VERSION ""

NS_ :

BS_:

BU_: ECU BMU SHDN CHRG TOOL LOGGER C125 DTI_L DTI_R SEVCON_L SEVCON_R SBG

BO_ 2284095744 BMU_TransmitBalancing_N_16: 8 BMU
 SG_ BMU_M16_Balance : 0|16@1+ (1,0) [0|65535] "" LOGGER
 SG_ BMU_M16_DieTemp : 16|8@1+ (1,0) [0|255] "degC" LOGGER

BO_ 2284095760 BMU_TransmitBalancing_N_17: 8 BMU
 SG_ BMU_M17_Balance : 0|16@1+ (1,0) [0|65535] "" LOGGER
 SG_ BMU_M17_DieTemp : 16|8@1+ (1,0) [0|255] "degC" LOGGER

BO_ 2284095776 BMU_TransmitBalancing_N_18: 8 BMU
 SG_ BMU_M18_Balance : 0|16@1+ (1,0) [0|65535] "" LOGGER
 SG_ BMU_M18_DieTemp : 16|8@1+ (1,0) [0|255] "degC" LOGGER

BO_ 2284095792 BMU_TransmitBalancing_N_19: 8 BMU
 SG_ BMU_M19_Balance : 0|16@1+ (1,0) [0|65535] "" LOGGER
 SG_ BMU_M19_DieTemp : 16|8@1+ (1,0) [0|255] "degC" LOGGER

BO_ 2284095808 BMU_TransmitBalancing_N_20: 8 BMU
 SG_ BMU_M20_Balance : 0|16@1+ (1,0) [0|65535] "" LOGGER
 SG_ BMU_M20_DieTemp : 16|8@1+ (1,0) [0|255] "degC" LOGGER

BO_ 2284095824 BMU_TransmitBalancing_N_21: 8 BMU
 SG_ BMU_M21_Balance : 0|16@1+ (1,0) [0|65535] "" LOGGER
 SG_ BMU_M21_DieTemp : 16|8@1+ (1,0) [0|255] "degC" LOGGER

BO_ 2284095840 BMU_TransmitBalancing_N_22: 8 BMU
 SG_ BMU_M22_Balance : 0|16@1+ (1,0) [0|65535] "" LOGGER
 SG_ BMU_M22_DieTemp : 16|8@1+ (1,0) [0|255] "degC" LOGGER

BO_ 2284095856 BMU_TransmitBalancing_N_23: 8 BMU
 SG_ BMU_M23_Balance : 0|16@1+ (1,0) [0|65535] "" LOGGER
 SG_ BMU_M23_DieTemp : 16|8@1+ (1,0) [0|255] "degC" LOGGER

BO_ 2284096768 BMU25_TransmitPackInfo: 8 BMU
 SG_ BMU_PackCurrent : 0|32@1- (0.000001,0) [-2147.483648|2147.483647] "A" ECU,C125
 SG_ BMU_PackVoltage : 32|32@1- (0.000001,0) [-2147.483648|2147.483647] "V" ECU,C125

BO_ 2284096784 BMU25_TransmitPackSummary: 8 BMU
 SG_ BMU_MinCell : 0|16@1+ (1,0) [0|65535] "mV" C125
 SG_ BMU_ValidCells : 16|16@1+ (1,0) [0|65535] "" C125
 SG_ BMU_MaxCellTemp : 32|8@1+ (1,0) [0|255] "degC" C125

BO_ 2284096800 BMU25_TransmitSOC: 8 BMU
 SG_ BMU_SocPct : 0|8@1+ (1,0) [0|255] "%" C125
 SG_ BMU_SocValid : 8|1@1+ (1,0) [0|1] "" C125
 SG_ BMU_SocCalibrated : 9|1@1+ (1,0) [0|1] "" C125
 SG_ BMU_Charge : 16|32@1- (0.000001,0) [-2147.483648|2147.483647] "Ah" C125

BO_ 2284097024 BMU25_TransmitPower: 8 BMU
 SG_ BMU_PackPower : 0|32@1- (1,0) [-2147483648|2147483647] "W" Vector__XXX

BO_ 2286157824 ECU_HEARTBEAT: 8 ECU
 SG_ ECU_State : 0|8@1+ (1,0) [0|255] "" BMU,SHDN,C125
 SG_ ECU_F_PedalPolarity : 8|1@1+ (1,0) [0|1] "" BMU,SHDN,C125
 SG_ ECU_F_BmuAlive : 9|1@1+ (1,0) [0|1] "" BMU,SHDN,C125
 SG_ ECU_F_InvAlive : 10|1@1+ (1,0) [0|1] "" BMU,SHDN,C125
 SG_ ECU_F_ShdnClosed : 11|1@1+ (1,0) [0|1] "" BMU,SHDN,C125
 SG_ ECU_F_PedalOk : 12|1@1+ (1,0) [0|1] "" BMU,SHDN,C125
 SG_ ECU_F_BrakePressed : 13|1@1+ (1,0) [0|1] "" BMU,SHDN,C125
 SG_ ECU_F_PrechargeReq : 14|1@1+ (1,0) [0|1] "" BMU,SHDN,C125
 SG_ ECU_F_TorqueAllowed : 15|1@1+ (1,0) [0|1] "" BMU,SHDN,C125
 SG_ ECU_F_OutputFault : 16|1@1+ (1,0) [0|1] "" BMU,SHDN,C125
 SG_ ECU_F_CanAOk : 17|1@1+ (1,0) [0|1] "" BMU,SHDN,C125
 SG_ ECU_F_CanBOk : 18|1@1+ (1,0) [0|1] "" BMU,SHDN,C125
 SG_ ECU_F_Warning : 19|1@1+ (1,0) [0|1] "" BMU,SHDN,C125
 SG_ ECU_F_EepromOk : 20|1@1+ (1,0) [0|1] "" BMU,SHDN,C125
 SG_ ECU_F_Calibrated : 21|1@1+ (1,0) [0|1] "" BMU,SHDN,C125
 SG_ ECU_F_HvOffReq : 22|1@1+ (1,0) [0|1] "" BMU,SHDN,C125
 SG_ ECU_FaultCode : 24|16@1+ (1,0) [0|65535] "" BMU,SHDN,C125
 SG_ ECU_FaultSeverity : 40|8@1+ (1,0) [0|255] "" BMU,SHDN,C125
 SG_ ECU_Uptime : 48|16@1+ (1,0) [0|65535] "s" BMU,SHDN,C125

BO_ 2290122752 VCU_ShutdownStatus: 8 SHDN
 SG_ SHDN_OldLines : 0|16@1+ (1,0) [0|65535] "" ECU,BMU
 SG_ SHDN_OldFirstFault : 16|8@1+ (1,0) [0|255] "" ECU,BMU

BO_ 2290122784 VCU_Pedal_Accel: 8 ECU
 SG_ VCU_Pedal_Accel_0 : 7|16@0+ (0.1,0) [0|6553.5] "%" Vector__XXX
 SG_ VCU_Pedal_Accel_1 : 23|16@0+ (0.1,0) [0|6553.5] "%" Vector__XXX
 SG_ VCU_Pedal_Accel_ADC_0 : 39|16@0+ (1,0) [0|65535] "mV" Vector__XXX
 SG_ VCU_Pedal_Accel_ADC_1 : 55|16@0+ (1,0) [0|65535] "mV" Vector__XXX

BO_ 2290122800 VCU_Pedal_Brake: 8 ECU
 SG_ VCU_Pedal_Brake_ADC_0 : 7|16@0+ (1,0) [0|65535] "mV" Vector__XXX
 SG_ VCU_Pedal_Brake_ADC_1 : 23|16@0+ (1,0) [0|65535] "mV" Vector__XXX
 SG_ VCU_Pedal_Brake_PSI_0 : 39|16@0- (0.0625,0) [-2048|2047.9375] "psi" Vector__XXX
 SG_ VCU_Pedal_Brake_PSI_1 : 55|16@0- (0.0625,0) [-2048|2047.9375] "psi" Vector__XXX

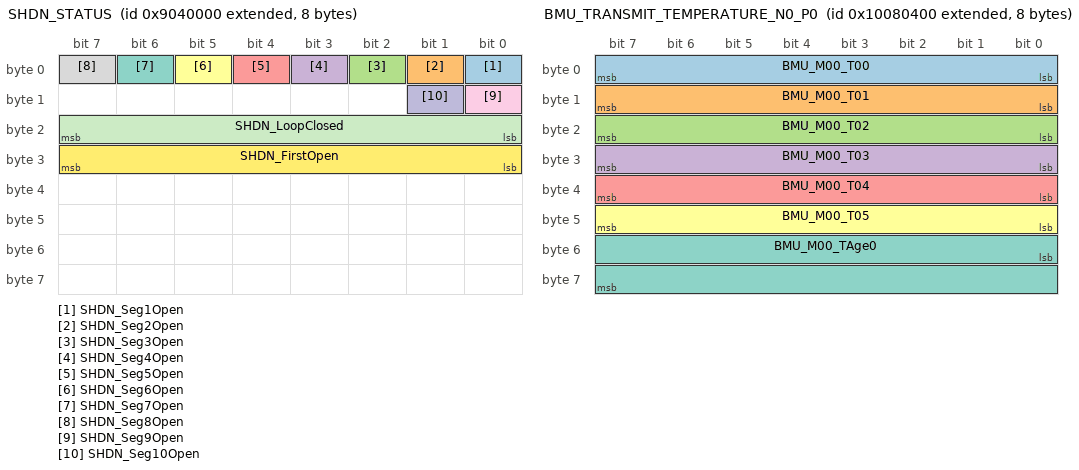
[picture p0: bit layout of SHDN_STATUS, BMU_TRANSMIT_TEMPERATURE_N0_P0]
BO_ 2298740736 SHDN_STATUS: 8 SHDN
 SG_ SHDN_Seg1Open : 0|1@1+ (1,0) [0|1] "" ECU,BMU,C125
 SG_ SHDN_Seg2Open : 1|1@1+ (1,0) [0|1] "" ECU,BMU,C125
 SG_ SHDN_Seg3Open : 2|1@1+ (1,0) [0|1] "" ECU,BMU,C125
 SG_ SHDN_Seg4Open : 3|1@1+ (1,0) [0|1] "" ECU,BMU,C125
 SG_ SHDN_Seg5Open : 4|1@1+ (1,0) [0|1] "" ECU,BMU,C125
 SG_ SHDN_Seg6Open : 5|1@1+ (1,0) [0|1] "" ECU,BMU,C125
 SG_ SHDN_Seg7Open : 6|1@1+ (1,0) [0|1] "" ECU,BMU,C125
 SG_ SHDN_Seg8Open : 7|1@1+ (1,0) [0|1] "" ECU,BMU,C125
 SG_ SHDN_Seg9Open : 8|1@1+ (1,0) [0|1] "" ECU,BMU,C125
 SG_ SHDN_Seg10Open : 9|1@1+ (1,0) [0|1] "" ECU,BMU,C125
 SG_ SHDN_LoopClosed : 16|8@1+ (1,0) [0|255] "" ECU,BMU,C125
 SG_ SHDN_FirstOpen : 24|8@1+ (1,0) [0|255] "" ECU,BMU,C125

BO_ 2307129344 CHARGE_CONTROL_HEARTBEAT: 8 CHRG
 SG_ CHRG_State : 0|8@1+ (1,0) [0|255] "" BMU
 SG_ CHRG_F_HbAms : 8|1@1+ (1,0) [0|1] "" BMU

BO_ 2316304896 BMU25_SendyneForward: 8 BMU

BO_ 2416443392 BMU_TRANSMIT_VOLTAGE_N0_P0: 8 BMU
 SG_ BMU_M00_V00 : 0|16@1+ (1,0) [0|65535] "mV" LOGGER
 SG_ BMU_M00_V01 : 16|16@1+ (1,0) [0|65535] "mV" LOGGER
 SG_ BMU_M00_V02 : 32|16@1+ (1,0) [0|65535] "mV" LOGGER
 SG_ BMU_M00_VAge0 : 48|16@1+ (1,0) [0|65535] "ms" LOGGER

BO_ 2416443393 BMU_TRANSMIT_VOLTAGE_N0_P1: 8 BMU
 SG_ BMU_M00_V03 : 0|16@1+ (1,0) [0|65535] "mV" LOGGER
 SG_ BMU_M00_V04 : 16|16@1+ (1,0) [0|65535] "mV" LOGGER
 SG_ BMU_M00_V05 : 32|16@1+ (1,0) [0|65535] "mV" LOGGER
 SG_ BMU_M00_VAge1 : 48|16@1+ (1,0) [0|65535] "ms" LOGGER

BO_ 2416443394 BMU_TRANSMIT_VOLTAGE_N0_P2: 8 BMU
 SG_ BMU_M00_V06 : 0|16@1+ (1,0) [0|65535] "mV" LOGGER
 SG_ BMU_M00_V07 : 16|16@1+ (1,0) [0|65535] "mV" LOGGER
 SG_ BMU_M00_V08 : 32|16@1+ (1,0) [0|65535] "mV" LOGGER
 SG_ BMU_M00_VAge2 : 48|16@1+ (1,0) [0|65535] "ms" LOGGER

BO_ 2416443395 BMU_TRANSMIT_VOLTAGE_N0_P3: 8 BMU
 SG_ BMU_M00_V09 : 0|16@1+ (1,0) [0|65535] "mV" LOGGER
 SG_ BMU_M00_V10 : 16|16@1+ (1,0) [0|65535] "mV" LOGGER
 SG_ BMU_M00_V11 : 32|16@1+ (1,0) [0|65535] "mV" LOGGER
 SG_ BMU_M00_VAge3 : 48|16@1+ (1,0) [0|65535] "ms" LOGGER

BO_ 2416443408 BMU_TRANSMIT_VOLTAGE_N1_P0: 8 BMU
 SG_ BMU_M01_V00 : 0|16@1+ (1,0) [0|65535] "mV" LOGGER
 SG_ BMU_M01_V01 : 16|16@1+ (1,0) [0|65535] "mV" LOGGER
 SG_ BMU_M01_V02 : 32|16@1+ (1,0) [0|65535] "mV" LOGGER
 SG_ BMU_M01_VAge0 : 48|16@1+ (1,0) [0|65535] "ms" LOGGER

BO_ 2416443409 BMU_TRANSMIT_VOLTAGE_N1_P1: 8 BMU
 SG_ BMU_M01_V03 : 0|16@1+ (1,0) [0|65535] "mV" LOGGER
 SG_ BMU_M01_V04 : 16|16@1+ (1,0) [0|65535] "mV" LOGGER
 SG_ BMU_M01_V05 : 32|16@1+ (1,0) [0|65535] "mV" LOGGER
 SG_ BMU_M01_VAge1 : 48|16@1+ (1,0) [0|65535] "ms" LOGGER

BO_ 2416443410 BMU_TRANSMIT_VOLTAGE_N1_P2: 8 BMU
 SG_ BMU_M01_V06 : 0|16@1+ (1,0) [0|65535] "mV" LOGGER
 SG_ BMU_M01_V07 : 16|16@1+ (1,0) [0|65535] "mV" LOGGER
 SG_ BMU_M01_V08 : 32|16@1+ (1,0) [0|65535] "mV" LOGGER
 SG_ BMU_M01_VAge2 : 48|16@1+ (1,0) [0|65535] "ms" LOGGER

BO_ 2416443411 BMU_TRANSMIT_VOLTAGE_N1_P3: 8 BMU
 SG_ BMU_M01_V09 : 0|16@1+ (1,0) [0|65535] "mV" LOGGER
 SG_ BMU_M01_V10 : 16|16@1+ (1,0) [0|65535] "mV" LOGGER
 SG_ BMU_M01_V11 : 32|16@1+ (1,0) [0|65535] "mV" LOGGER
 SG_ BMU_M01_VAge3 : 48|16@1+ (1,0) [0|65535] "ms" LOGGER

BO_ 2416443424 BMU_TRANSMIT_VOLTAGE_N2_P0: 8 BMU
 SG_ BMU_M02_V00 : 0|16@1+ (1,0) [0|65535] "mV" LOGGER
 SG_ BMU_M02_V01 : 16|16@1+ (1,0) [0|65535] "mV" LOGGER
 SG_ BMU_M02_V02 : 32|16@1+ (1,0) [0|65535] "mV" LOGGER
 SG_ BMU_M02_VAge0 : 48|16@1+ (1,0) [0|65535] "ms" LOGGER

BO_ 2416443425 BMU_TRANSMIT_VOLTAGE_N2_P1: 8 BMU
 SG_ BMU_M02_V03 : 0|16@1+ (1,0) [0|65535] "mV" LOGGER
 SG_ BMU_M02_V04 : 16|16@1+ (1,0) [0|65535] "mV" LOGGER
 SG_ BMU_M02_V05 : 32|16@1+ (1,0) [0|65535] "mV" LOGGER
 SG_ BMU_M02_VAge1 : 48|16@1+ (1,0) [0|65535] "ms" LOGGER

BO_ 2416443426 BMU_TRANSMIT_VOLTAGE_N2_P2: 8 BMU
 SG_ BMU_M02_V06 : 0|16@1+ (1,0) [0|65535] "mV" LOGGER
 SG_ BMU_M02_V07 : 16|16@1+ (1,0) [0|65535] "mV" LOGGER
 SG_ BMU_M02_V08 : 32|16@1+ (1,0) [0|65535] "mV" LOGGER
 SG_ BMU_M02_VAge2 : 48|16@1+ (1,0) [0|65535] "ms" LOGGER

BO_ 2416443427 BMU_TRANSMIT_VOLTAGE_N2_P3: 8 BMU
 SG_ BMU_M02_V09 : 0|16@1+ (1,0) [0|65535] "mV" LOGGER
 SG_ BMU_M02_V10 : 16|16@1+ (1,0) [0|65535] "mV" LOGGER
 SG_ BMU_M02_V11 : 32|16@1+ (1,0) [0|65535] "mV" LOGGER
 SG_ BMU_M02_VAge3 : 48|16@1+ (1,0) [0|65535] "ms" LOGGER

BO_ 2416443440 BMU_TRANSMIT_VOLTAGE_N3_P0: 8 BMU
 SG_ BMU_M03_V00 : 0|16@1+ (1,0) [0|65535] "mV" LOGGER
 SG_ BMU_M03_V01 : 16|16@1+ (1,0) [0|65535] "mV" LOGGER
 SG_ BMU_M03_V02 : 32|16@1+ (1,0) [0|65535] "mV" LOGGER
 SG_ BMU_M03_VAge0 : 48|16@1+ (1,0) [0|65535] "ms" LOGGER

BO_ 2416443441 BMU_TRANSMIT_VOLTAGE_N3_P1: 8 BMU
 SG_ BMU_M03_V03 : 0|16@1+ (1,0) [0|65535] "mV" LOGGER
 SG_ BMU_M03_V04 : 16|16@1+ (1,0) [0|65535] "mV" LOGGER
 SG_ BMU_M03_V05 : 32|16@1+ (1,0) [0|65535] "mV" LOGGER
 SG_ BMU_M03_VAge1 : 48|16@1+ (1,0) [0|65535] "ms" LOGGER

BO_ 2416443442 BMU_TRANSMIT_VOLTAGE_N3_P2: 8 BMU
 SG_ BMU_M03_V06 : 0|16@1+ (1,0) [0|65535] "mV" LOGGER
 SG_ BMU_M03_V07 : 16|16@1+ (1,0) [0|65535] "mV" LOGGER
 SG_ BMU_M03_V08 : 32|16@1+ (1,0) [0|65535] "mV" LOGGER
 SG_ BMU_M03_VAge2 : 48|16@1+ (1,0) [0|65535] "ms" LOGGER

BO_ 2416443443 BMU_TRANSMIT_VOLTAGE_N3_P3: 8 BMU
 SG_ BMU_M03_V09 : 0|16@1+ (1,0) [0|65535] "mV" LOGGER
 SG_ BMU_M03_V10 : 16|16@1+ (1,0) [0|65535] "mV" LOGGER
 SG_ BMU_M03_V11 : 32|16@1+ (1,0) [0|65535] "mV" LOGGER
 SG_ BMU_M03_VAge3 : 48|16@1+ (1,0) [0|65535] "ms" LOGGER

BO_ 2416443456 BMU_TRANSMIT_VOLTAGE_N4_P0: 8 BMU
 SG_ BMU_M04_V00 : 0|16@1+ (1,0) [0|65535] "mV" LOGGER
 SG_ BMU_M04_V01 : 16|16@1+ (1,0) [0|65535] "mV" LOGGER
 SG_ BMU_M04_V02 : 32|16@1+ (1,0) [0|65535] "mV" LOGGER
 SG_ BMU_M04_VAge0 : 48|16@1+ (1,0) [0|65535] "ms" LOGGER

BO_ 2416443457 BMU_TRANSMIT_VOLTAGE_N4_P1: 8 BMU
 SG_ BMU_M04_V03 : 0|16@1+ (1,0) [0|65535] "mV" LOGGER
 SG_ BMU_M04_V04 : 16|16@1+ (1,0) [0|65535] "mV" LOGGER
 SG_ BMU_M04_V05 : 32|16@1+ (1,0) [0|65535] "mV" LOGGER
 SG_ BMU_M04_VAge1 : 48|16@1+ (1,0) [0|65535] "ms" LOGGER

BO_ 2416443458 BMU_TRANSMIT_VOLTAGE_N4_P2: 8 BMU
 SG_ BMU_M04_V06 : 0|16@1+ (1,0) [0|65535] "mV" LOGGER
 SG_ BMU_M04_V07 : 16|16@1+ (1,0) [0|65535] "mV" LOGGER
 SG_ BMU_M04_V08 : 32|16@1+ (1,0) [0|65535] "mV" LOGGER
 SG_ BMU_M04_VAge2 : 48|16@1+ (1,0) [0|65535] "ms" LOGGER

BO_ 2416443459 BMU_TRANSMIT_VOLTAGE_N4_P3: 8 BMU
 SG_ BMU_M04_V09 : 0|16@1+ (1,0) [0|65535] "mV" LOGGER
 SG_ BMU_M04_V10 : 16|16@1+ (1,0) [0|65535] "mV" LOGGER
 SG_ BMU_M04_V11 : 32|16@1+ (1,0) [0|65535] "mV" LOGGER
 SG_ BMU_M04_VAge3 : 48|16@1+ (1,0) [0|65535] "ms" LOGGER

BO_ 2416443472 BMU_TRANSMIT_VOLTAGE_N5_P0: 8 BMU
 SG_ BMU_M05_V00 : 0|16@1+ (1,0) [0|65535] "mV" LOGGER
 SG_ BMU_M05_V01 : 16|16@1+ (1,0) [0|65535] "mV" LOGGER
 SG_ BMU_M05_V02 : 32|16@1+ (1,0) [0|65535] "mV" LOGGER
 SG_ BMU_M05_VAge0 : 48|16@1+ (1,0) [0|65535] "ms" LOGGER

BO_ 2416443473 BMU_TRANSMIT_VOLTAGE_N5_P1: 8 BMU
 SG_ BMU_M05_V03 : 0|16@1+ (1,0) [0|65535] "mV" LOGGER
 SG_ BMU_M05_V04 : 16|16@1+ (1,0) [0|65535] "mV" LOGGER
 SG_ BMU_M05_V05 : 32|16@1+ (1,0) [0|65535] "mV" LOGGER
 SG_ BMU_M05_VAge1 : 48|16@1+ (1,0) [0|65535] "ms" LOGGER

BO_ 2416443474 BMU_TRANSMIT_VOLTAGE_N5_P2: 8 BMU
 SG_ BMU_M05_V06 : 0|16@1+ (1,0) [0|65535] "mV" LOGGER
 SG_ BMU_M05_V07 : 16|16@1+ (1,0) [0|65535] "mV" LOGGER
 SG_ BMU_M05_V08 : 32|16@1+ (1,0) [0|65535] "mV" LOGGER
 SG_ BMU_M05_VAge2 : 48|16@1+ (1,0) [0|65535] "ms" LOGGER

BO_ 2416443475 BMU_TRANSMIT_VOLTAGE_N5_P3: 8 BMU
 SG_ BMU_M05_V09 : 0|16@1+ (1,0) [0|65535] "mV" LOGGER
 SG_ BMU_M05_V10 : 16|16@1+ (1,0) [0|65535] "mV" LOGGER
 SG_ BMU_M05_V11 : 32|16@1+ (1,0) [0|65535] "mV" LOGGER
 SG_ BMU_M05_VAge3 : 48|16@1+ (1,0) [0|65535] "ms" LOGGER

BO_ 2416443488 BMU_TRANSMIT_VOLTAGE_N6_P0: 8 BMU
 SG_ BMU_M06_V00 : 0|16@1+ (1,0) [0|65535] "mV" LOGGER
 SG_ BMU_M06_V01 : 16|16@1+ (1,0) [0|65535] "mV" LOGGER
 SG_ BMU_M06_V02 : 32|16@1+ (1,0) [0|65535] "mV" LOGGER
 SG_ BMU_M06_VAge0 : 48|16@1+ (1,0) [0|65535] "ms" LOGGER

BO_ 2416443489 BMU_TRANSMIT_VOLTAGE_N6_P1: 8 BMU
 SG_ BMU_M06_V03 : 0|16@1+ (1,0) [0|65535] "mV" LOGGER
 SG_ BMU_M06_V04 : 16|16@1+ (1,0) [0|65535] "mV" LOGGER
 SG_ BMU_M06_V05 : 32|16@1+ (1,0) [0|65535] "mV" LOGGER
 SG_ BMU_M06_VAge1 : 48|16@1+ (1,0) [0|65535] "ms" LOGGER

BO_ 2416443490 BMU_TRANSMIT_VOLTAGE_N6_P2: 8 BMU
 SG_ BMU_M06_V06 : 0|16@1+ (1,0) [0|65535] "mV" LOGGER
 SG_ BMU_M06_V07 : 16|16@1+ (1,0) [0|65535] "mV" LOGGER
 SG_ BMU_M06_V08 : 32|16@1+ (1,0) [0|65535] "mV" LOGGER
 SG_ BMU_M06_VAge2 : 48|16@1+ (1,0) [0|65535] "ms" LOGGER

BO_ 2416443491 BMU_TRANSMIT_VOLTAGE_N6_P3: 8 BMU
 SG_ BMU_M06_V09 : 0|16@1+ (1,0) [0|65535] "mV" LOGGER
 SG_ BMU_M06_V10 : 16|16@1+ (1,0) [0|65535] "mV" LOGGER
 SG_ BMU_M06_V11 : 32|16@1+ (1,0) [0|65535] "mV" LOGGER
 SG_ BMU_M06_VAge3 : 48|16@1+ (1,0) [0|65535] "ms" LOGGER

BO_ 2416443504 BMU_TRANSMIT_VOLTAGE_N7_P0: 8 BMU
 SG_ BMU_M07_V00 : 0|16@1+ (1,0) [0|65535] "mV" LOGGER
 SG_ BMU_M07_V01 : 16|16@1+ (1,0) [0|65535] "mV" LOGGER
 SG_ BMU_M07_V02 : 32|16@1+ (1,0) [0|65535] "mV" LOGGER
 SG_ BMU_M07_VAge0 : 48|16@1+ (1,0) [0|65535] "ms" LOGGER

BO_ 2416443505 BMU_TRANSMIT_VOLTAGE_N7_P1: 8 BMU
 SG_ BMU_M07_V03 : 0|16@1+ (1,0) [0|65535] "mV" LOGGER
 SG_ BMU_M07_V04 : 16|16@1+ (1,0) [0|65535] "mV" LOGGER
 SG_ BMU_M07_V05 : 32|16@1+ (1,0) [0|65535] "mV" LOGGER
 SG_ BMU_M07_VAge1 : 48|16@1+ (1,0) [0|65535] "ms" LOGGER

BO_ 2416443506 BMU_TRANSMIT_VOLTAGE_N7_P2: 8 BMU
 SG_ BMU_M07_V06 : 0|16@1+ (1,0) [0|65535] "mV" LOGGER
 SG_ BMU_M07_V07 : 16|16@1+ (1,0) [0|65535] "mV" LOGGER
 SG_ BMU_M07_V08 : 32|16@1+ (1,0) [0|65535] "mV" LOGGER
 SG_ BMU_M07_VAge2 : 48|16@1+ (1,0) [0|65535] "ms" LOGGER

BO_ 2416443507 BMU_TRANSMIT_VOLTAGE_N7_P3: 8 BMU
 SG_ BMU_M07_V09 : 0|16@1+ (1,0) [0|65535] "mV" LOGGER
 SG_ BMU_M07_V10 : 16|16@1+ (1,0) [0|65535] "mV" LOGGER
 SG_ BMU_M07_V11 : 32|16@1+ (1,0) [0|65535] "mV" LOGGER
 SG_ BMU_M07_VAge3 : 48|16@1+ (1,0) [0|65535] "ms" LOGGER

BO_ 2416443520 BMU_TRANSMIT_VOLTAGE_N8_P0: 8 BMU
 SG_ BMU_M08_V00 : 0|16@1+ (1,0) [0|65535] "mV" LOGGER
 SG_ BMU_M08_V01 : 16|16@1+ (1,0) [0|65535] "mV" LOGGER
 SG_ BMU_M08_V02 : 32|16@1+ (1,0) [0|65535] "mV" LOGGER
 SG_ BMU_M08_VAge0 : 48|16@1+ (1,0) [0|65535] "ms" LOGGER

BO_ 2416443521 BMU_TRANSMIT_VOLTAGE_N8_P1: 8 BMU
 SG_ BMU_M08_V03 : 0|16@1+ (1,0) [0|65535] "mV" LOGGER
 SG_ BMU_M08_V04 : 16|16@1+ (1,0) [0|65535] "mV" LOGGER
 SG_ BMU_M08_V05 : 32|16@1+ (1,0) [0|65535] "mV" LOGGER
 SG_ BMU_M08_VAge1 : 48|16@1+ (1,0) [0|65535] "ms" LOGGER

BO_ 2416443522 BMU_TRANSMIT_VOLTAGE_N8_P2: 8 BMU
 SG_ BMU_M08_V06 : 0|16@1+ (1,0) [0|65535] "mV" LOGGER
 SG_ BMU_M08_V07 : 16|16@1+ (1,0) [0|65535] "mV" LOGGER
 SG_ BMU_M08_V08 : 32|16@1+ (1,0) [0|65535] "mV" LOGGER
 SG_ BMU_M08_VAge2 : 48|16@1+ (1,0) [0|65535] "ms" LOGGER

BO_ 2416443523 BMU_TRANSMIT_VOLTAGE_N8_P3: 8 BMU
 SG_ BMU_M08_V09 : 0|16@1+ (1,0) [0|65535] "mV" LOGGER
 SG_ BMU_M08_V10 : 16|16@1+ (1,0) [0|65535] "mV" LOGGER
 SG_ BMU_M08_V11 : 32|16@1+ (1,0) [0|65535] "mV" LOGGER
 SG_ BMU_M08_VAge3 : 48|16@1+ (1,0) [0|65535] "ms" LOGGER

BO_ 2416443536 BMU_TRANSMIT_VOLTAGE_N9_P0: 8 BMU
 SG_ BMU_M09_V00 : 0|16@1+ (1,0) [0|65535] "mV" LOGGER
 SG_ BMU_M09_V01 : 16|16@1+ (1,0) [0|65535] "mV" LOGGER
 SG_ BMU_M09_V02 : 32|16@1+ (1,0) [0|65535] "mV" LOGGER
 SG_ BMU_M09_VAge0 : 48|16@1+ (1,0) [0|65535] "ms" LOGGER

BO_ 2416443537 BMU_TRANSMIT_VOLTAGE_N9_P1: 8 BMU
 SG_ BMU_M09_V03 : 0|16@1+ (1,0) [0|65535] "mV" LOGGER
 SG_ BMU_M09_V04 : 16|16@1+ (1,0) [0|65535] "mV" LOGGER
 SG_ BMU_M09_V05 : 32|16@1+ (1,0) [0|65535] "mV" LOGGER
 SG_ BMU_M09_VAge1 : 48|16@1+ (1,0) [0|65535] "ms" LOGGER

BO_ 2416443538 BMU_TRANSMIT_VOLTAGE_N9_P2: 8 BMU
 SG_ BMU_M09_V06 : 0|16@1+ (1,0) [0|65535] "mV" LOGGER
 SG_ BMU_M09_V07 : 16|16@1+ (1,0) [0|65535] "mV" LOGGER
 SG_ BMU_M09_V08 : 32|16@1+ (1,0) [0|65535] "mV" LOGGER
 SG_ BMU_M09_VAge2 : 48|16@1+ (1,0) [0|65535] "ms" LOGGER

BO_ 2416443539 BMU_TRANSMIT_VOLTAGE_N9_P3: 8 BMU
 SG_ BMU_M09_V09 : 0|16@1+ (1,0) [0|65535] "mV" LOGGER
 SG_ BMU_M09_V10 : 16|16@1+ (1,0) [0|65535] "mV" LOGGER
 SG_ BMU_M09_V11 : 32|16@1+ (1,0) [0|65535] "mV" LOGGER
 SG_ BMU_M09_VAge3 : 48|16@1+ (1,0) [0|65535] "ms" LOGGER

BO_ 2416443552 BMU_TRANSMIT_VOLTAGE_N10_P0: 8 BMU
 SG_ BMU_M10_V00 : 0|16@1+ (1,0) [0|65535] "mV" LOGGER
 SG_ BMU_M10_V01 : 16|16@1+ (1,0) [0|65535] "mV" LOGGER
 SG_ BMU_M10_V02 : 32|16@1+ (1,0) [0|65535] "mV" LOGGER
 SG_ BMU_M10_VAge0 : 48|16@1+ (1,0) [0|65535] "ms" LOGGER

BO_ 2416443553 BMU_TRANSMIT_VOLTAGE_N10_P1: 8 BMU
 SG_ BMU_M10_V03 : 0|16@1+ (1,0) [0|65535] "mV" LOGGER
 SG_ BMU_M10_V04 : 16|16@1+ (1,0) [0|65535] "mV" LOGGER
 SG_ BMU_M10_V05 : 32|16@1+ (1,0) [0|65535] "mV" LOGGER
 SG_ BMU_M10_VAge1 : 48|16@1+ (1,0) [0|65535] "ms" LOGGER

BO_ 2416443554 BMU_TRANSMIT_VOLTAGE_N10_P2: 8 BMU
 SG_ BMU_M10_V06 : 0|16@1+ (1,0) [0|65535] "mV" LOGGER
 SG_ BMU_M10_V07 : 16|16@1+ (1,0) [0|65535] "mV" LOGGER
 SG_ BMU_M10_V08 : 32|16@1+ (1,0) [0|65535] "mV" LOGGER
 SG_ BMU_M10_VAge2 : 48|16@1+ (1,0) [0|65535] "ms" LOGGER

BO_ 2416443555 BMU_TRANSMIT_VOLTAGE_N10_P3: 8 BMU
 SG_ BMU_M10_V09 : 0|16@1+ (1,0) [0|65535] "mV" LOGGER
 SG_ BMU_M10_V10 : 16|16@1+ (1,0) [0|65535] "mV" LOGGER
 SG_ BMU_M10_V11 : 32|16@1+ (1,0) [0|65535] "mV" LOGGER
 SG_ BMU_M10_VAge3 : 48|16@1+ (1,0) [0|65535] "ms" LOGGER

BO_ 2416443568 BMU_TRANSMIT_VOLTAGE_N11_P0: 8 BMU
 SG_ BMU_M11_V00 : 0|16@1+ (1,0) [0|65535] "mV" LOGGER
 SG_ BMU_M11_V01 : 16|16@1+ (1,0) [0|65535] "mV" LOGGER
 SG_ BMU_M11_V02 : 32|16@1+ (1,0) [0|65535] "mV" LOGGER
 SG_ BMU_M11_VAge0 : 48|16@1+ (1,0) [0|65535] "ms" LOGGER

BO_ 2416443569 BMU_TRANSMIT_VOLTAGE_N11_P1: 8 BMU
 SG_ BMU_M11_V03 : 0|16@1+ (1,0) [0|65535] "mV" LOGGER
 SG_ BMU_M11_V04 : 16|16@1+ (1,0) [0|65535] "mV" LOGGER
 SG_ BMU_M11_V05 : 32|16@1+ (1,0) [0|65535] "mV" LOGGER
 SG_ BMU_M11_VAge1 : 48|16@1+ (1,0) [0|65535] "ms" LOGGER

BO_ 2416443570 BMU_TRANSMIT_VOLTAGE_N11_P2: 8 BMU
 SG_ BMU_M11_V06 : 0|16@1+ (1,0) [0|65535] "mV" LOGGER
 SG_ BMU_M11_V07 : 16|16@1+ (1,0) [0|65535] "mV" LOGGER
 SG_ BMU_M11_V08 : 32|16@1+ (1,0) [0|65535] "mV" LOGGER
 SG_ BMU_M11_VAge2 : 48|16@1+ (1,0) [0|65535] "ms" LOGGER

BO_ 2416443571 BMU_TRANSMIT_VOLTAGE_N11_P3: 8 BMU
 SG_ BMU_M11_V09 : 0|16@1+ (1,0) [0|65535] "mV" LOGGER
 SG_ BMU_M11_V10 : 16|16@1+ (1,0) [0|65535] "mV" LOGGER
 SG_ BMU_M11_V11 : 32|16@1+ (1,0) [0|65535] "mV" LOGGER
 SG_ BMU_M11_VAge3 : 48|16@1+ (1,0) [0|65535] "ms" LOGGER

BO_ 2416443584 BMU_TRANSMIT_VOLTAGE_N12_P0: 8 BMU
 SG_ BMU_M12_V00 : 0|16@1+ (1,0) [0|65535] "mV" LOGGER
 SG_ BMU_M12_V01 : 16|16@1+ (1,0) [0|65535] "mV" LOGGER
 SG_ BMU_M12_V02 : 32|16@1+ (1,0) [0|65535] "mV" LOGGER
 SG_ BMU_M12_VAge0 : 48|16@1+ (1,0) [0|65535] "ms" LOGGER

BO_ 2416443585 BMU_TRANSMIT_VOLTAGE_N12_P1: 8 BMU
 SG_ BMU_M12_V03 : 0|16@1+ (1,0) [0|65535] "mV" LOGGER
 SG_ BMU_M12_V04 : 16|16@1+ (1,0) [0|65535] "mV" LOGGER
 SG_ BMU_M12_V05 : 32|16@1+ (1,0) [0|65535] "mV" LOGGER
 SG_ BMU_M12_VAge1 : 48|16@1+ (1,0) [0|65535] "ms" LOGGER

BO_ 2416443586 BMU_TRANSMIT_VOLTAGE_N12_P2: 8 BMU
 SG_ BMU_M12_V06 : 0|16@1+ (1,0) [0|65535] "mV" LOGGER
 SG_ BMU_M12_V07 : 16|16@1+ (1,0) [0|65535] "mV" LOGGER
 SG_ BMU_M12_V08 : 32|16@1+ (1,0) [0|65535] "mV" LOGGER
 SG_ BMU_M12_VAge2 : 48|16@1+ (1,0) [0|65535] "ms" LOGGER

BO_ 2416443587 BMU_TRANSMIT_VOLTAGE_N12_P3: 8 BMU
 SG_ BMU_M12_V09 : 0|16@1+ (1,0) [0|65535] "mV" LOGGER
 SG_ BMU_M12_V10 : 16|16@1+ (1,0) [0|65535] "mV" LOGGER
 SG_ BMU_M12_V11 : 32|16@1+ (1,0) [0|65535] "mV" LOGGER
 SG_ BMU_M12_VAge3 : 48|16@1+ (1,0) [0|65535] "ms" LOGGER

BO_ 2416443600 BMU_TRANSMIT_VOLTAGE_N13_P0: 8 BMU
 SG_ BMU_M13_V00 : 0|16@1+ (1,0) [0|65535] "mV" LOGGER
 SG_ BMU_M13_V01 : 16|16@1+ (1,0) [0|65535] "mV" LOGGER
 SG_ BMU_M13_V02 : 32|16@1+ (1,0) [0|65535] "mV" LOGGER
 SG_ BMU_M13_VAge0 : 48|16@1+ (1,0) [0|65535] "ms" LOGGER

BO_ 2416443601 BMU_TRANSMIT_VOLTAGE_N13_P1: 8 BMU
 SG_ BMU_M13_V03 : 0|16@1+ (1,0) [0|65535] "mV" LOGGER
 SG_ BMU_M13_V04 : 16|16@1+ (1,0) [0|65535] "mV" LOGGER
 SG_ BMU_M13_V05 : 32|16@1+ (1,0) [0|65535] "mV" LOGGER
 SG_ BMU_M13_VAge1 : 48|16@1+ (1,0) [0|65535] "ms" LOGGER

BO_ 2416443602 BMU_TRANSMIT_VOLTAGE_N13_P2: 8 BMU
 SG_ BMU_M13_V06 : 0|16@1+ (1,0) [0|65535] "mV" LOGGER
 SG_ BMU_M13_V07 : 16|16@1+ (1,0) [0|65535] "mV" LOGGER
 SG_ BMU_M13_V08 : 32|16@1+ (1,0) [0|65535] "mV" LOGGER
 SG_ BMU_M13_VAge2 : 48|16@1+ (1,0) [0|65535] "ms" LOGGER

BO_ 2416443603 BMU_TRANSMIT_VOLTAGE_N13_P3: 8 BMU
 SG_ BMU_M13_V09 : 0|16@1+ (1,0) [0|65535] "mV" LOGGER
 SG_ BMU_M13_V10 : 16|16@1+ (1,0) [0|65535] "mV" LOGGER
 SG_ BMU_M13_V11 : 32|16@1+ (1,0) [0|65535] "mV" LOGGER
 SG_ BMU_M13_VAge3 : 48|16@1+ (1,0) [0|65535] "ms" LOGGER

BO_ 2416443616 BMU_TRANSMIT_VOLTAGE_N14_P0: 8 BMU
 SG_ BMU_M14_V00 : 0|16@1+ (1,0) [0|65535] "mV" LOGGER
 SG_ BMU_M14_V01 : 16|16@1+ (1,0) [0|65535] "mV" LOGGER
 SG_ BMU_M14_V02 : 32|16@1+ (1,0) [0|65535] "mV" LOGGER
 SG_ BMU_M14_VAge0 : 48|16@1+ (1,0) [0|65535] "ms" LOGGER

BO_ 2416443617 BMU_TRANSMIT_VOLTAGE_N14_P1: 8 BMU
 SG_ BMU_M14_V03 : 0|16@1+ (1,0) [0|65535] "mV" LOGGER
 SG_ BMU_M14_V04 : 16|16@1+ (1,0) [0|65535] "mV" LOGGER
 SG_ BMU_M14_V05 : 32|16@1+ (1,0) [0|65535] "mV" LOGGER
 SG_ BMU_M14_VAge1 : 48|16@1+ (1,0) [0|65535] "ms" LOGGER

BO_ 2416443618 BMU_TRANSMIT_VOLTAGE_N14_P2: 8 BMU
 SG_ BMU_M14_V06 : 0|16@1+ (1,0) [0|65535] "mV" LOGGER
 SG_ BMU_M14_V07 : 16|16@1+ (1,0) [0|65535] "mV" LOGGER
 SG_ BMU_M14_V08 : 32|16@1+ (1,0) [0|65535] "mV" LOGGER
 SG_ BMU_M14_VAge2 : 48|16@1+ (1,0) [0|65535] "ms" LOGGER

BO_ 2416443619 BMU_TRANSMIT_VOLTAGE_N14_P3: 8 BMU
 SG_ BMU_M14_V09 : 0|16@1+ (1,0) [0|65535] "mV" LOGGER
 SG_ BMU_M14_V10 : 16|16@1+ (1,0) [0|65535] "mV" LOGGER
 SG_ BMU_M14_V11 : 32|16@1+ (1,0) [0|65535] "mV" LOGGER
 SG_ BMU_M14_VAge3 : 48|16@1+ (1,0) [0|65535] "ms" LOGGER

BO_ 2416443632 BMU_TRANSMIT_VOLTAGE_N15_P0: 8 BMU
 SG_ BMU_M15_V00 : 0|16@1+ (1,0) [0|65535] "mV" LOGGER
 SG_ BMU_M15_V01 : 16|16@1+ (1,0) [0|65535] "mV" LOGGER
 SG_ BMU_M15_V02 : 32|16@1+ (1,0) [0|65535] "mV" LOGGER
 SG_ BMU_M15_VAge0 : 48|16@1+ (1,0) [0|65535] "ms" LOGGER

BO_ 2416443633 BMU_TRANSMIT_VOLTAGE_N15_P1: 8 BMU
 SG_ BMU_M15_V03 : 0|16@1+ (1,0) [0|65535] "mV" LOGGER
 SG_ BMU_M15_V04 : 16|16@1+ (1,0) [0|65535] "mV" LOGGER
 SG_ BMU_M15_V05 : 32|16@1+ (1,0) [0|65535] "mV" LOGGER
 SG_ BMU_M15_VAge1 : 48|16@1+ (1,0) [0|65535] "ms" LOGGER

BO_ 2416443634 BMU_TRANSMIT_VOLTAGE_N15_P2: 8 BMU
 SG_ BMU_M15_V06 : 0|16@1+ (1,0) [0|65535] "mV" LOGGER
 SG_ BMU_M15_V07 : 16|16@1+ (1,0) [0|65535] "mV" LOGGER
 SG_ BMU_M15_V08 : 32|16@1+ (1,0) [0|65535] "mV" LOGGER
 SG_ BMU_M15_VAge2 : 48|16@1+ (1,0) [0|65535] "ms" LOGGER

BO_ 2416443635 BMU_TRANSMIT_VOLTAGE_N15_P3: 8 BMU
 SG_ BMU_M15_V09 : 0|16@1+ (1,0) [0|65535] "mV" LOGGER
 SG_ BMU_M15_V10 : 16|16@1+ (1,0) [0|65535] "mV" LOGGER
 SG_ BMU_M15_V11 : 32|16@1+ (1,0) [0|65535] "mV" LOGGER
 SG_ BMU_M15_VAge3 : 48|16@1+ (1,0) [0|65535] "ms" LOGGER

BO_ 2416443648 BMU_TRANSMIT_VOLTAGE_N16_P0: 8 BMU
 SG_ BMU_M16_V00 : 0|16@1+ (1,0) [0|65535] "mV" LOGGER
 SG_ BMU_M16_V01 : 16|16@1+ (1,0) [0|65535] "mV" LOGGER
 SG_ BMU_M16_V02 : 32|16@1+ (1,0) [0|65535] "mV" LOGGER
 SG_ BMU_M16_VAge0 : 48|16@1+ (1,0) [0|65535] "ms" LOGGER

BO_ 2416443649 BMU_TRANSMIT_VOLTAGE_N16_P1: 8 BMU
 SG_ BMU_M16_V03 : 0|16@1+ (1,0) [0|65535] "mV" LOGGER
 SG_ BMU_M16_V04 : 16|16@1+ (1,0) [0|65535] "mV" LOGGER
 SG_ BMU_M16_V05 : 32|16@1+ (1,0) [0|65535] "mV" LOGGER
 SG_ BMU_M16_VAge1 : 48|16@1+ (1,0) [0|65535] "ms" LOGGER

BO_ 2416443650 BMU_TRANSMIT_VOLTAGE_N16_P2: 8 BMU
 SG_ BMU_M16_V06 : 0|16@1+ (1,0) [0|65535] "mV" LOGGER
 SG_ BMU_M16_V07 : 16|16@1+ (1,0) [0|65535] "mV" LOGGER
 SG_ BMU_M16_V08 : 32|16@1+ (1,0) [0|65535] "mV" LOGGER
 SG_ BMU_M16_VAge2 : 48|16@1+ (1,0) [0|65535] "ms" LOGGER

BO_ 2416443651 BMU_TRANSMIT_VOLTAGE_N16_P3: 8 BMU
 SG_ BMU_M16_V09 : 0|16@1+ (1,0) [0|65535] "mV" LOGGER
 SG_ BMU_M16_V10 : 16|16@1+ (1,0) [0|65535] "mV" LOGGER
 SG_ BMU_M16_V11 : 32|16@1+ (1,0) [0|65535] "mV" LOGGER
 SG_ BMU_M16_VAge3 : 48|16@1+ (1,0) [0|65535] "ms" LOGGER

BO_ 2416443664 BMU_TRANSMIT_VOLTAGE_N17_P0: 8 BMU
 SG_ BMU_M17_V00 : 0|16@1+ (1,0) [0|65535] "mV" LOGGER
 SG_ BMU_M17_V01 : 16|16@1+ (1,0) [0|65535] "mV" LOGGER
 SG_ BMU_M17_V02 : 32|16@1+ (1,0) [0|65535] "mV" LOGGER
 SG_ BMU_M17_VAge0 : 48|16@1+ (1,0) [0|65535] "ms" LOGGER

BO_ 2416443665 BMU_TRANSMIT_VOLTAGE_N17_P1: 8 BMU
 SG_ BMU_M17_V03 : 0|16@1+ (1,0) [0|65535] "mV" LOGGER
 SG_ BMU_M17_V04 : 16|16@1+ (1,0) [0|65535] "mV" LOGGER
 SG_ BMU_M17_V05 : 32|16@1+ (1,0) [0|65535] "mV" LOGGER
 SG_ BMU_M17_VAge1 : 48|16@1+ (1,0) [0|65535] "ms" LOGGER

BO_ 2416443666 BMU_TRANSMIT_VOLTAGE_N17_P2: 8 BMU
 SG_ BMU_M17_V06 : 0|16@1+ (1,0) [0|65535] "mV" LOGGER
 SG_ BMU_M17_V07 : 16|16@1+ (1,0) [0|65535] "mV" LOGGER
 SG_ BMU_M17_V08 : 32|16@1+ (1,0) [0|65535] "mV" LOGGER
 SG_ BMU_M17_VAge2 : 48|16@1+ (1,0) [0|65535] "ms" LOGGER

BO_ 2416443667 BMU_TRANSMIT_VOLTAGE_N17_P3: 8 BMU
 SG_ BMU_M17_V09 : 0|16@1+ (1,0) [0|65535] "mV" LOGGER
 SG_ BMU_M17_V10 : 16|16@1+ (1,0) [0|65535] "mV" LOGGER
 SG_ BMU_M17_V11 : 32|16@1+ (1,0) [0|65535] "mV" LOGGER
 SG_ BMU_M17_VAge3 : 48|16@1+ (1,0) [0|65535] "ms" LOGGER

BO_ 2416443680 BMU_TRANSMIT_VOLTAGE_N18_P0: 8 BMU
 SG_ BMU_M18_V00 : 0|16@1+ (1,0) [0|65535] "mV" LOGGER
 SG_ BMU_M18_V01 : 16|16@1+ (1,0) [0|65535] "mV" LOGGER
 SG_ BMU_M18_V02 : 32|16@1+ (1,0) [0|65535] "mV" LOGGER
 SG_ BMU_M18_VAge0 : 48|16@1+ (1,0) [0|65535] "ms" LOGGER

BO_ 2416443681 BMU_TRANSMIT_VOLTAGE_N18_P1: 8 BMU
 SG_ BMU_M18_V03 : 0|16@1+ (1,0) [0|65535] "mV" LOGGER
 SG_ BMU_M18_V04 : 16|16@1+ (1,0) [0|65535] "mV" LOGGER
 SG_ BMU_M18_V05 : 32|16@1+ (1,0) [0|65535] "mV" LOGGER
 SG_ BMU_M18_VAge1 : 48|16@1+ (1,0) [0|65535] "ms" LOGGER

BO_ 2416443682 BMU_TRANSMIT_VOLTAGE_N18_P2: 8 BMU
 SG_ BMU_M18_V06 : 0|16@1+ (1,0) [0|65535] "mV" LOGGER
 SG_ BMU_M18_V07 : 16|16@1+ (1,0) [0|65535] "mV" LOGGER
 SG_ BMU_M18_V08 : 32|16@1+ (1,0) [0|65535] "mV" LOGGER
 SG_ BMU_M18_VAge2 : 48|16@1+ (1,0) [0|65535] "ms" LOGGER

BO_ 2416443683 BMU_TRANSMIT_VOLTAGE_N18_P3: 8 BMU
 SG_ BMU_M18_V09 : 0|16@1+ (1,0) [0|65535] "mV" LOGGER
 SG_ BMU_M18_V10 : 16|16@1+ (1,0) [0|65535] "mV" LOGGER
 SG_ BMU_M18_V11 : 32|16@1+ (1,0) [0|65535] "mV" LOGGER
 SG_ BMU_M18_VAge3 : 48|16@1+ (1,0) [0|65535] "ms" LOGGER

BO_ 2416443696 BMU_TRANSMIT_VOLTAGE_N19_P0: 8 BMU
 SG_ BMU_M19_V00 : 0|16@1+ (1,0) [0|65535] "mV" LOGGER
 SG_ BMU_M19_V01 : 16|16@1+ (1,0) [0|65535] "mV" LOGGER
 SG_ BMU_M19_V02 : 32|16@1+ (1,0) [0|65535] "mV" LOGGER
 SG_ BMU_M19_VAge0 : 48|16@1+ (1,0) [0|65535] "ms" LOGGER

BO_ 2416443697 BMU_TRANSMIT_VOLTAGE_N19_P1: 8 BMU
 SG_ BMU_M19_V03 : 0|16@1+ (1,0) [0|65535] "mV" LOGGER
 SG_ BMU_M19_V04 : 16|16@1+ (1,0) [0|65535] "mV" LOGGER
 SG_ BMU_M19_V05 : 32|16@1+ (1,0) [0|65535] "mV" LOGGER
 SG_ BMU_M19_VAge1 : 48|16@1+ (1,0) [0|65535] "ms" LOGGER

BO_ 2416443698 BMU_TRANSMIT_VOLTAGE_N19_P2: 8 BMU
 SG_ BMU_M19_V06 : 0|16@1+ (1,0) [0|65535] "mV" LOGGER
 SG_ BMU_M19_V07 : 16|16@1+ (1,0) [0|65535] "mV" LOGGER
 SG_ BMU_M19_V08 : 32|16@1+ (1,0) [0|65535] "mV" LOGGER
 SG_ BMU_M19_VAge2 : 48|16@1+ (1,0) [0|65535] "ms" LOGGER

BO_ 2416443699 BMU_TRANSMIT_VOLTAGE_N19_P3: 8 BMU
 SG_ BMU_M19_V09 : 0|16@1+ (1,0) [0|65535] "mV" LOGGER
 SG_ BMU_M19_V10 : 16|16@1+ (1,0) [0|65535] "mV" LOGGER
 SG_ BMU_M19_V11 : 32|16@1+ (1,0) [0|65535] "mV" LOGGER
 SG_ BMU_M19_VAge3 : 48|16@1+ (1,0) [0|65535] "ms" LOGGER

BO_ 2416443712 BMU_TRANSMIT_VOLTAGE_N20_P0: 8 BMU
 SG_ BMU_M20_V00 : 0|16@1+ (1,0) [0|65535] "mV" LOGGER
 SG_ BMU_M20_V01 : 16|16@1+ (1,0) [0|65535] "mV" LOGGER
 SG_ BMU_M20_V02 : 32|16@1+ (1,0) [0|65535] "mV" LOGGER
 SG_ BMU_M20_VAge0 : 48|16@1+ (1,0) [0|65535] "ms" LOGGER

BO_ 2416443713 BMU_TRANSMIT_VOLTAGE_N20_P1: 8 BMU
 SG_ BMU_M20_V03 : 0|16@1+ (1,0) [0|65535] "mV" LOGGER
 SG_ BMU_M20_V04 : 16|16@1+ (1,0) [0|65535] "mV" LOGGER
 SG_ BMU_M20_V05 : 32|16@1+ (1,0) [0|65535] "mV" LOGGER
 SG_ BMU_M20_VAge1 : 48|16@1+ (1,0) [0|65535] "ms" LOGGER

BO_ 2416443714 BMU_TRANSMIT_VOLTAGE_N20_P2: 8 BMU
 SG_ BMU_M20_V06 : 0|16@1+ (1,0) [0|65535] "mV" LOGGER
 SG_ BMU_M20_V07 : 16|16@1+ (1,0) [0|65535] "mV" LOGGER
 SG_ BMU_M20_V08 : 32|16@1+ (1,0) [0|65535] "mV" LOGGER
 SG_ BMU_M20_VAge2 : 48|16@1+ (1,0) [0|65535] "ms" LOGGER

BO_ 2416443715 BMU_TRANSMIT_VOLTAGE_N20_P3: 8 BMU
 SG_ BMU_M20_V09 : 0|16@1+ (1,0) [0|65535] "mV" LOGGER
 SG_ BMU_M20_V10 : 16|16@1+ (1,0) [0|65535] "mV" LOGGER
 SG_ BMU_M20_V11 : 32|16@1+ (1,0) [0|65535] "mV" LOGGER
 SG_ BMU_M20_VAge3 : 48|16@1+ (1,0) [0|65535] "ms" LOGGER

BO_ 2416443728 BMU_TRANSMIT_VOLTAGE_N21_P0: 8 BMU
 SG_ BMU_M21_V00 : 0|16@1+ (1,0) [0|65535] "mV" LOGGER
 SG_ BMU_M21_V01 : 16|16@1+ (1,0) [0|65535] "mV" LOGGER
 SG_ BMU_M21_V02 : 32|16@1+ (1,0) [0|65535] "mV" LOGGER
 SG_ BMU_M21_VAge0 : 48|16@1+ (1,0) [0|65535] "ms" LOGGER

BO_ 2416443729 BMU_TRANSMIT_VOLTAGE_N21_P1: 8 BMU
 SG_ BMU_M21_V03 : 0|16@1+ (1,0) [0|65535] "mV" LOGGER
 SG_ BMU_M21_V04 : 16|16@1+ (1,0) [0|65535] "mV" LOGGER
 SG_ BMU_M21_V05 : 32|16@1+ (1,0) [0|65535] "mV" LOGGER
 SG_ BMU_M21_VAge1 : 48|16@1+ (1,0) [0|65535] "ms" LOGGER

BO_ 2416443730 BMU_TRANSMIT_VOLTAGE_N21_P2: 8 BMU
 SG_ BMU_M21_V06 : 0|16@1+ (1,0) [0|65535] "mV" LOGGER
 SG_ BMU_M21_V07 : 16|16@1+ (1,0) [0|65535] "mV" LOGGER
 SG_ BMU_M21_V08 : 32|16@1+ (1,0) [0|65535] "mV" LOGGER
 SG_ BMU_M21_VAge2 : 48|16@1+ (1,0) [0|65535] "ms" LOGGER

BO_ 2416443731 BMU_TRANSMIT_VOLTAGE_N21_P3: 8 BMU
 SG_ BMU_M21_V09 : 0|16@1+ (1,0) [0|65535] "mV" LOGGER
 SG_ BMU_M21_V10 : 16|16@1+ (1,0) [0|65535] "mV" LOGGER
 SG_ BMU_M21_V11 : 32|16@1+ (1,0) [0|65535] "mV" LOGGER
 SG_ BMU_M21_VAge3 : 48|16@1+ (1,0) [0|65535] "ms" LOGGER

BO_ 2416443744 BMU_TRANSMIT_VOLTAGE_N22_P0: 8 BMU
 SG_ BMU_M22_V00 : 0|16@1+ (1,0) [0|65535] "mV" LOGGER
 SG_ BMU_M22_V01 : 16|16@1+ (1,0) [0|65535] "mV" LOGGER
 SG_ BMU_M22_V02 : 32|16@1+ (1,0) [0|65535] "mV" LOGGER
 SG_ BMU_M22_VAge0 : 48|16@1+ (1,0) [0|65535] "ms" LOGGER

BO_ 2416443745 BMU_TRANSMIT_VOLTAGE_N22_P1: 8 BMU
 SG_ BMU_M22_V03 : 0|16@1+ (1,0) [0|65535] "mV" LOGGER
 SG_ BMU_M22_V04 : 16|16@1+ (1,0) [0|65535] "mV" LOGGER
 SG_ BMU_M22_V05 : 32|16@1+ (1,0) [0|65535] "mV" LOGGER
 SG_ BMU_M22_VAge1 : 48|16@1+ (1,0) [0|65535] "ms" LOGGER

BO_ 2416443746 BMU_TRANSMIT_VOLTAGE_N22_P2: 8 BMU
 SG_ BMU_M22_V06 : 0|16@1+ (1,0) [0|65535] "mV" LOGGER
 SG_ BMU_M22_V07 : 16|16@1+ (1,0) [0|65535] "mV" LOGGER
 SG_ BMU_M22_V08 : 32|16@1+ (1,0) [0|65535] "mV" LOGGER
 SG_ BMU_M22_VAge2 : 48|16@1+ (1,0) [0|65535] "ms" LOGGER

BO_ 2416443747 BMU_TRANSMIT_VOLTAGE_N22_P3: 8 BMU
 SG_ BMU_M22_V09 : 0|16@1+ (1,0) [0|65535] "mV" LOGGER
 SG_ BMU_M22_V10 : 16|16@1+ (1,0) [0|65535] "mV" LOGGER
 SG_ BMU_M22_V11 : 32|16@1+ (1,0) [0|65535] "mV" LOGGER
 SG_ BMU_M22_VAge3 : 48|16@1+ (1,0) [0|65535] "ms" LOGGER

BO_ 2416443760 BMU_TRANSMIT_VOLTAGE_N23_P0: 8 BMU
 SG_ BMU_M23_V00 : 0|16@1+ (1,0) [0|65535] "mV" LOGGER
 SG_ BMU_M23_V01 : 16|16@1+ (1,0) [0|65535] "mV" LOGGER
 SG_ BMU_M23_V02 : 32|16@1+ (1,0) [0|65535] "mV" LOGGER
 SG_ BMU_M23_VAge0 : 48|16@1+ (1,0) [0|65535] "ms" LOGGER

BO_ 2416443761 BMU_TRANSMIT_VOLTAGE_N23_P1: 8 BMU
 SG_ BMU_M23_V03 : 0|16@1+ (1,0) [0|65535] "mV" LOGGER
 SG_ BMU_M23_V04 : 16|16@1+ (1,0) [0|65535] "mV" LOGGER
 SG_ BMU_M23_V05 : 32|16@1+ (1,0) [0|65535] "mV" LOGGER
 SG_ BMU_M23_VAge1 : 48|16@1+ (1,0) [0|65535] "ms" LOGGER

BO_ 2416443762 BMU_TRANSMIT_VOLTAGE_N23_P2: 8 BMU
 SG_ BMU_M23_V06 : 0|16@1+ (1,0) [0|65535] "mV" LOGGER
 SG_ BMU_M23_V07 : 16|16@1+ (1,0) [0|65535] "mV" LOGGER
 SG_ BMU_M23_V08 : 32|16@1+ (1,0) [0|65535] "mV" LOGGER
 SG_ BMU_M23_VAge2 : 48|16@1+ (1,0) [0|65535] "ms" LOGGER

BO_ 2416443763 BMU_TRANSMIT_VOLTAGE_N23_P3: 8 BMU
 SG_ BMU_M23_V09 : 0|16@1+ (1,0) [0|65535] "mV" LOGGER
 SG_ BMU_M23_V10 : 16|16@1+ (1,0) [0|65535] "mV" LOGGER
 SG_ BMU_M23_V11 : 32|16@1+ (1,0) [0|65535] "mV" LOGGER
 SG_ BMU_M23_VAge3 : 48|16@1+ (1,0) [0|65535] "ms" LOGGER

BO_ 2416444416 BMU_TRANSMIT_TEMPERATURE_N0_P0: 8 BMU
 SG_ BMU_M00_T00 : 0|8@1+ (1,0) [0|255] "degC" LOGGER
 SG_ BMU_M00_T01 : 8|8@1+ (1,0) [0|255] "degC" LOGGER
 SG_ BMU_M00_T02 : 16|8@1+ (1,0) [0|255] "degC" LOGGER
 SG_ BMU_M00_T03 : 24|8@1+ (1,0) [0|255] "degC" LOGGER
 SG_ BMU_M00_T04 : 32|8@1+ (1,0) [0|255] "degC" LOGGER
 SG_ BMU_M00_T05 : 40|8@1+ (1,0) [0|255] "degC" LOGGER
 SG_ BMU_M00_TAge0 : 48|16@1+ (1,0) [0|65535] "ms" LOGGER

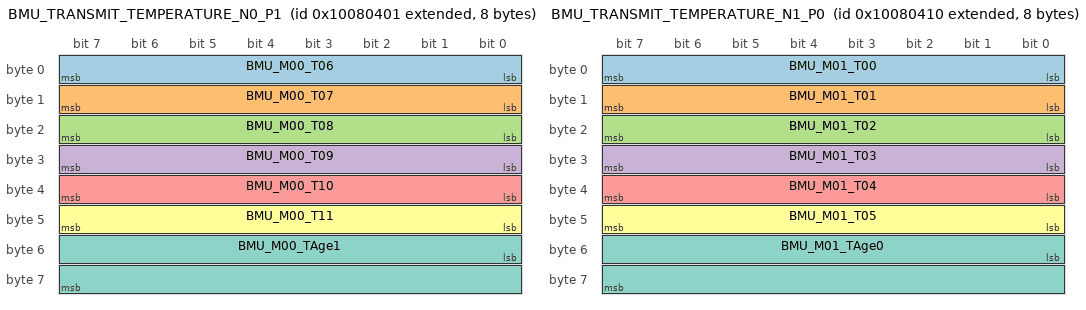
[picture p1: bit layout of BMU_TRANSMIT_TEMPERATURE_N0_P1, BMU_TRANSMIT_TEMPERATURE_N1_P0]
BO_ 2416444417 BMU_TRANSMIT_TEMPERATURE_N0_P1: 8 BMU
 SG_ BMU_M00_T06 : 0|8@1+ (1,0) [0|255] "degC" LOGGER
 SG_ BMU_M00_T07 : 8|8@1+ (1,0) [0|255] "degC" LOGGER
 SG_ BMU_M00_T08 : 16|8@1+ (1,0) [0|255] "degC" LOGGER
 SG_ BMU_M00_T09 : 24|8@1+ (1,0) [0|255] "degC" LOGGER
 SG_ BMU_M00_T10 : 32|8@1+ (1,0) [0|255] "degC" LOGGER
 SG_ BMU_M00_T11 : 40|8@1+ (1,0) [0|255] "degC" LOGGER
 SG_ BMU_M00_TAge1 : 48|16@1+ (1,0) [0|65535] "ms" LOGGER

BO_ 2416444432 BMU_TRANSMIT_TEMPERATURE_N1_P0: 8 BMU
 SG_ BMU_M01_T00 : 0|8@1+ (1,0) [0|255] "degC" LOGGER
 SG_ BMU_M01_T01 : 8|8@1+ (1,0) [0|255] "degC" LOGGER
 SG_ BMU_M01_T02 : 16|8@1+ (1,0) [0|255] "degC" LOGGER
 SG_ BMU_M01_T03 : 24|8@1+ (1,0) [0|255] "degC" LOGGER
 SG_ BMU_M01_T04 : 32|8@1+ (1,0) [0|255] "degC" LOGGER
 SG_ BMU_M01_T05 : 40|8@1+ (1,0) [0|255] "degC" LOGGER
 SG_ BMU_M01_TAge0 : 48|16@1+ (1,0) [0|65535] "ms" LOGGER

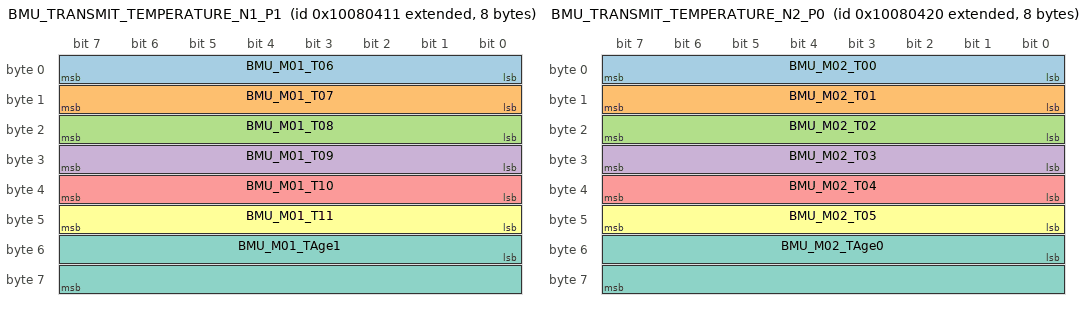
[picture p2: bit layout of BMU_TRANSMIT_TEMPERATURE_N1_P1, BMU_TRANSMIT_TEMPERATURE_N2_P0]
BO_ 2416444433 BMU_TRANSMIT_TEMPERATURE_N1_P1: 8 BMU
 SG_ BMU_M01_T06 : 0|8@1+ (1,0) [0|255] "degC" LOGGER
 SG_ BMU_M01_T07 : 8|8@1+ (1,0) [0|255] "degC" LOGGER
 SG_ BMU_M01_T08 : 16|8@1+ (1,0) [0|255] "degC" LOGGER
 SG_ BMU_M01_T09 : 24|8@1+ (1,0) [0|255] "degC" LOGGER
 SG_ BMU_M01_T10 : 32|8@1+ (1,0) [0|255] "degC" LOGGER
 SG_ BMU_M01_T11 : 40|8@1+ (1,0) [0|255] "degC" LOGGER
 SG_ BMU_M01_TAge1 : 48|16@1+ (1,0) [0|65535] "ms" LOGGER

BO_ 2416444448 BMU_TRANSMIT_TEMPERATURE_N2_P0: 8 BMU
 SG_ BMU_M02_T00 : 0|8@1+ (1,0) [0|255] "degC" LOGGER
 SG_ BMU_M02_T01 : 8|8@1+ (1,0) [0|255] "degC" LOGGER
 SG_ BMU_M02_T02 : 16|8@1+ (1,0) [0|255] "degC" LOGGER
 SG_ BMU_M02_T03 : 24|8@1+ (1,0) [0|255] "degC" LOGGER
 SG_ BMU_M02_T04 : 32|8@1+ (1,0) [0|255] "degC" LOGGER
 SG_ BMU_M02_T05 : 40|8@1+ (1,0) [0|255] "degC" LOGGER
 SG_ BMU_M02_TAge0 : 48|16@1+ (1,0) [0|65535] "ms" LOGGER

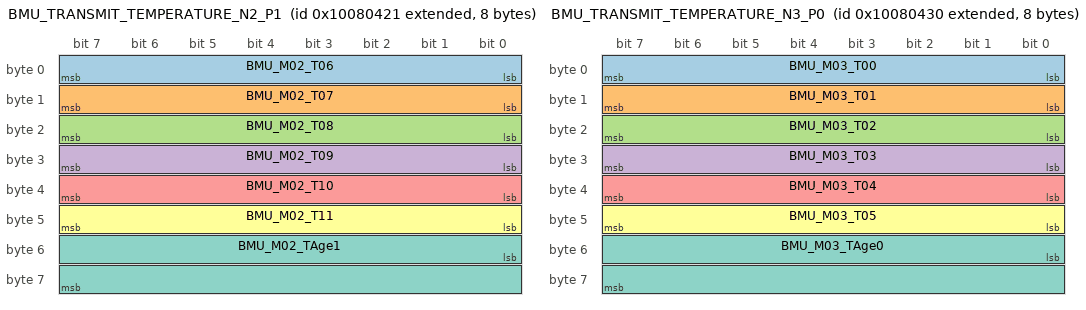
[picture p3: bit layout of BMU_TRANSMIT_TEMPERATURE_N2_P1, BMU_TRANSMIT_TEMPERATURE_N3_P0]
BO_ 2416444449 BMU_TRANSMIT_TEMPERATURE_N2_P1: 8 BMU
 SG_ BMU_M02_T06 : 0|8@1+ (1,0) [0|255] "degC" LOGGER
 SG_ BMU_M02_T07 : 8|8@1+ (1,0) [0|255] "degC" LOGGER
 SG_ BMU_M02_T08 : 16|8@1+ (1,0) [0|255] "degC" LOGGER
 SG_ BMU_M02_T09 : 24|8@1+ (1,0) [0|255] "degC" LOGGER
 SG_ BMU_M02_T10 : 32|8@1+ (1,0) [0|255] "degC" LOGGER
 SG_ BMU_M02_T11 : 40|8@1+ (1,0) [0|255] "degC" LOGGER
 SG_ BMU_M02_TAge1 : 48|16@1+ (1,0) [0|65535] "ms" LOGGER

BO_ 2416444464 BMU_TRANSMIT_TEMPERATURE_N3_P0: 8 BMU
 SG_ BMU_M03_T00 : 0|8@1+ (1,0) [0|255] "degC" LOGGER
 SG_ BMU_M03_T01 : 8|8@1+ (1,0) [0|255] "degC" LOGGER
 SG_ BMU_M03_T02 : 16|8@1+ (1,0) [0|255] "degC" LOGGER
 SG_ BMU_M03_T03 : 24|8@1+ (1,0) [0|255] "degC" LOGGER
 SG_ BMU_M03_T04 : 32|8@1+ (1,0) [0|255] "degC" LOGGER
 SG_ BMU_M03_T05 : 40|8@1+ (1,0) [0|255] "degC" LOGGER
 SG_ BMU_M03_TAge0 : 48|16@1+ (1,0) [0|65535] "ms" LOGGER

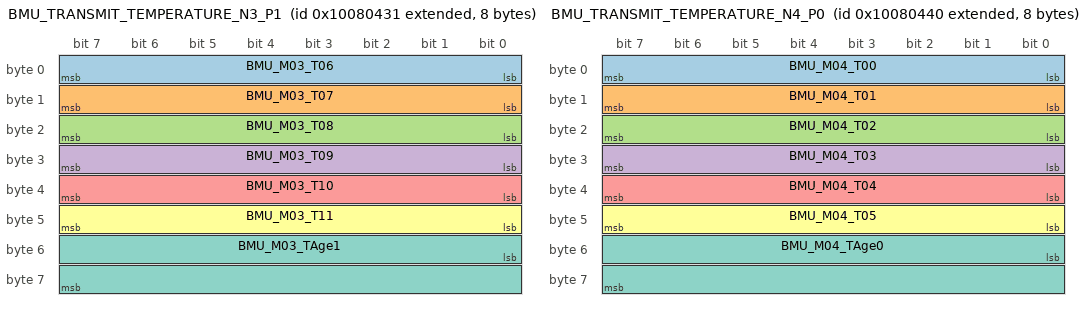
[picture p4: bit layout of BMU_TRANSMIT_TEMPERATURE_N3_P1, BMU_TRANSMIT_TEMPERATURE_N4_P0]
BO_ 2416444465 BMU_TRANSMIT_TEMPERATURE_N3_P1: 8 BMU
 SG_ BMU_M03_T06 : 0|8@1+ (1,0) [0|255] "degC" LOGGER
 SG_ BMU_M03_T07 : 8|8@1+ (1,0) [0|255] "degC" LOGGER
 SG_ BMU_M03_T08 : 16|8@1+ (1,0) [0|255] "degC" LOGGER
 SG_ BMU_M03_T09 : 24|8@1+ (1,0) [0|255] "degC" LOGGER
 SG_ BMU_M03_T10 : 32|8@1+ (1,0) [0|255] "degC" LOGGER
 SG_ BMU_M03_T11 : 40|8@1+ (1,0) [0|255] "degC" LOGGER
 SG_ BMU_M03_TAge1 : 48|16@1+ (1,0) [0|65535] "ms" LOGGER

BO_ 2416444480 BMU_TRANSMIT_TEMPERATURE_N4_P0: 8 BMU
 SG_ BMU_M04_T00 : 0|8@1+ (1,0) [0|255] "degC" LOGGER
 SG_ BMU_M04_T01 : 8|8@1+ (1,0) [0|255] "degC" LOGGER
 SG_ BMU_M04_T02 : 16|8@1+ (1,0) [0|255] "degC" LOGGER
 SG_ BMU_M04_T03 : 24|8@1+ (1,0) [0|255] "degC" LOGGER
 SG_ BMU_M04_T04 : 32|8@1+ (1,0) [0|255] "degC" LOGGER
 SG_ BMU_M04_T05 : 40|8@1+ (1,0) [0|255] "degC" LOGGER
 SG_ BMU_M04_TAge0 : 48|16@1+ (1,0) [0|65535] "ms" LOGGER

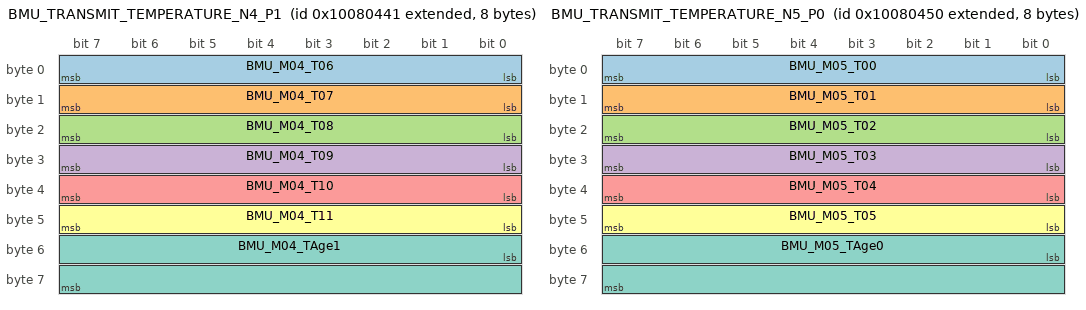
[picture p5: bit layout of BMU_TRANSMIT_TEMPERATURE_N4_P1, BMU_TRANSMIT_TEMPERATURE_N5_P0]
BO_ 2416444481 BMU_TRANSMIT_TEMPERATURE_N4_P1: 8 BMU
 SG_ BMU_M04_T06 : 0|8@1+ (1,0) [0|255] "degC" LOGGER
 SG_ BMU_M04_T07 : 8|8@1+ (1,0) [0|255] "degC" LOGGER
 SG_ BMU_M04_T08 : 16|8@1+ (1,0) [0|255] "degC" LOGGER
 SG_ BMU_M04_T09 : 24|8@1+ (1,0) [0|255] "degC" LOGGER
 SG_ BMU_M04_T10 : 32|8@1+ (1,0) [0|255] "degC" LOGGER
 SG_ BMU_M04_T11 : 40|8@1+ (1,0) [0|255] "degC" LOGGER
 SG_ BMU_M04_TAge1 : 48|16@1+ (1,0) [0|65535] "ms" LOGGER

BO_ 2416444496 BMU_TRANSMIT_TEMPERATURE_N5_P0: 8 BMU
 SG_ BMU_M05_T00 : 0|8@1+ (1,0) [0|255] "degC" LOGGER
 SG_ BMU_M05_T01 : 8|8@1+ (1,0) [0|255] "degC" LOGGER
 SG_ BMU_M05_T02 : 16|8@1+ (1,0) [0|255] "degC" LOGGER
 SG_ BMU_M05_T03 : 24|8@1+ (1,0) [0|255] "degC" LOGGER
 SG_ BMU_M05_T04 : 32|8@1+ (1,0) [0|255] "degC" LOGGER
 SG_ BMU_M05_T05 : 40|8@1+ (1,0) [0|255] "degC" LOGGER
 SG_ BMU_M05_TAge0 : 48|16@1+ (1,0) [0|65535] "ms" LOGGER

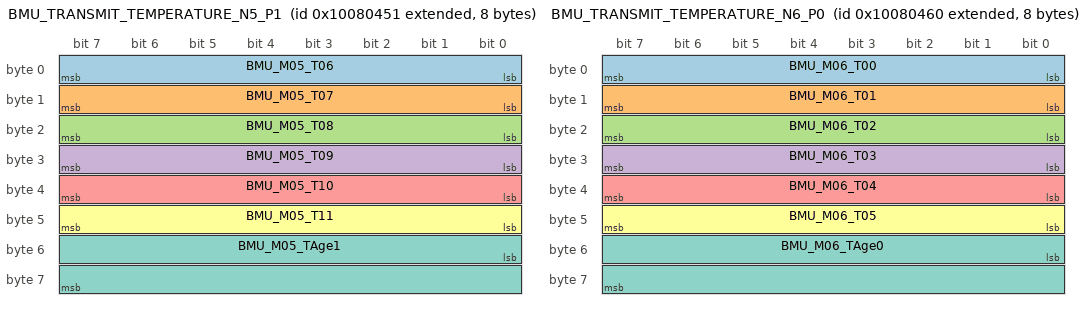
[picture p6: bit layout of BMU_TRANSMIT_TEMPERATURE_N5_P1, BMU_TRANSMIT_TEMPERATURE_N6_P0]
BO_ 2416444497 BMU_TRANSMIT_TEMPERATURE_N5_P1: 8 BMU
 SG_ BMU_M05_T06 : 0|8@1+ (1,0) [0|255] "degC" LOGGER
 SG_ BMU_M05_T07 : 8|8@1+ (1,0) [0|255] "degC" LOGGER
 SG_ BMU_M05_T08 : 16|8@1+ (1,0) [0|255] "degC" LOGGER
 SG_ BMU_M05_T09 : 24|8@1+ (1,0) [0|255] "degC" LOGGER
 SG_ BMU_M05_T10 : 32|8@1+ (1,0) [0|255] "degC" LOGGER
 SG_ BMU_M05_T11 : 40|8@1+ (1,0) [0|255] "degC" LOGGER
 SG_ BMU_M05_TAge1 : 48|16@1+ (1,0) [0|65535] "ms" LOGGER

BO_ 2416444512 BMU_TRANSMIT_TEMPERATURE_N6_P0: 8 BMU
 SG_ BMU_M06_T00 : 0|8@1+ (1,0) [0|255] "degC" LOGGER
 SG_ BMU_M06_T01 : 8|8@1+ (1,0) [0|255] "degC" LOGGER
 SG_ BMU_M06_T02 : 16|8@1+ (1,0) [0|255] "degC" LOGGER
 SG_ BMU_M06_T03 : 24|8@1+ (1,0) [0|255] "degC" LOGGER
 SG_ BMU_M06_T04 : 32|8@1+ (1,0) [0|255] "degC" LOGGER
 SG_ BMU_M06_T05 : 40|8@1+ (1,0) [0|255] "degC" LOGGER
 SG_ BMU_M06_TAge0 : 48|16@1+ (1,0) [0|65535] "ms" LOGGER

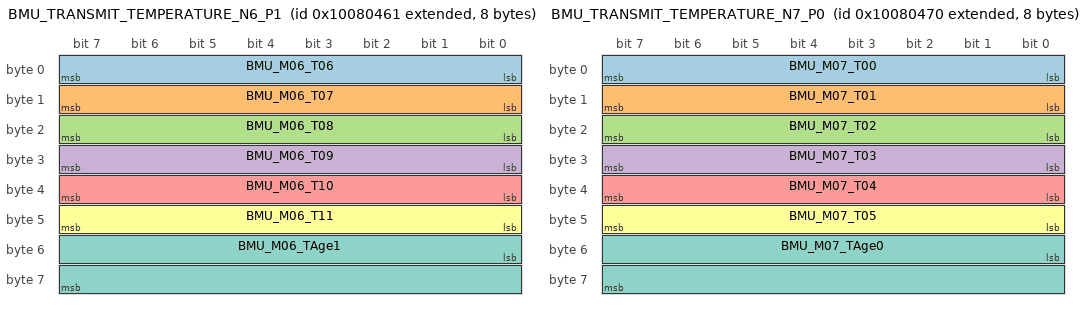
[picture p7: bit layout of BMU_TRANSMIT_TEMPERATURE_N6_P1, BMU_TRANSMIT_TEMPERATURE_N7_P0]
BO_ 2416444513 BMU_TRANSMIT_TEMPERATURE_N6_P1: 8 BMU
 SG_ BMU_M06_T06 : 0|8@1+ (1,0) [0|255] "degC" LOGGER
 SG_ BMU_M06_T07 : 8|8@1+ (1,0) [0|255] "degC" LOGGER
 SG_ BMU_M06_T08 : 16|8@1+ (1,0) [0|255] "degC" LOGGER
 SG_ BMU_M06_T09 : 24|8@1+ (1,0) [0|255] "degC" LOGGER
 SG_ BMU_M06_T10 : 32|8@1+ (1,0) [0|255] "degC" LOGGER
 SG_ BMU_M06_T11 : 40|8@1+ (1,0) [0|255] "degC" LOGGER
 SG_ BMU_M06_TAge1 : 48|16@1+ (1,0) [0|65535] "ms" LOGGER

BO_ 2416444528 BMU_TRANSMIT_TEMPERATURE_N7_P0: 8 BMU
 SG_ BMU_M07_T00 : 0|8@1+ (1,0) [0|255] "degC" LOGGER
 SG_ BMU_M07_T01 : 8|8@1+ (1,0) [0|255] "degC" LOGGER
 SG_ BMU_M07_T02 : 16|8@1+ (1,0) [0|255] "degC" LOGGER
 SG_ BMU_M07_T03 : 24|8@1+ (1,0) [0|255] "degC" LOGGER
 SG_ BMU_M07_T04 : 32|8@1+ (1,0) [0|255] "degC" LOGGER
 SG_ BMU_M07_T05 : 40|8@1+ (1,0) [0|255] "degC" LOGGER
 SG_ BMU_M07_TAge0 : 48|16@1+ (1,0) [0|65535] "ms" LOGGER

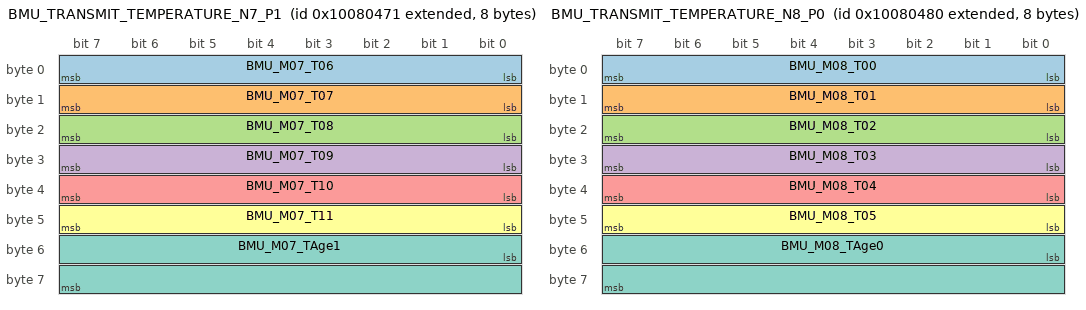
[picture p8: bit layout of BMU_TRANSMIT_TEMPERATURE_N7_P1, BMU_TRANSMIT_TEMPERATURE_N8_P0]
BO_ 2416444529 BMU_TRANSMIT_TEMPERATURE_N7_P1: 8 BMU
 SG_ BMU_M07_T06 : 0|8@1+ (1,0) [0|255] "degC" LOGGER
 SG_ BMU_M07_T07 : 8|8@1+ (1,0) [0|255] "degC" LOGGER
 SG_ BMU_M07_T08 : 16|8@1+ (1,0) [0|255] "degC" LOGGER
 SG_ BMU_M07_T09 : 24|8@1+ (1,0) [0|255] "degC" LOGGER
 SG_ BMU_M07_T10 : 32|8@1+ (1,0) [0|255] "degC" LOGGER
 SG_ BMU_M07_T11 : 40|8@1+ (1,0) [0|255] "degC" LOGGER
 SG_ BMU_M07_TAge1 : 48|16@1+ (1,0) [0|65535] "ms" LOGGER

BO_ 2416444544 BMU_TRANSMIT_TEMPERATURE_N8_P0: 8 BMU
 SG_ BMU_M08_T00 : 0|8@1+ (1,0) [0|255] "degC" LOGGER
 SG_ BMU_M08_T01 : 8|8@1+ (1,0) [0|255] "degC" LOGGER
 SG_ BMU_M08_T02 : 16|8@1+ (1,0) [0|255] "degC" LOGGER
 SG_ BMU_M08_T03 : 24|8@1+ (1,0) [0|255] "degC" LOGGER
 SG_ BMU_M08_T04 : 32|8@1+ (1,0) [0|255] "degC" LOGGER
 SG_ BMU_M08_T05 : 40|8@1+ (1,0) [0|255] "degC" LOGGER
 SG_ BMU_M08_TAge0 : 48|16@1+ (1,0) [0|65535] "ms" LOGGER

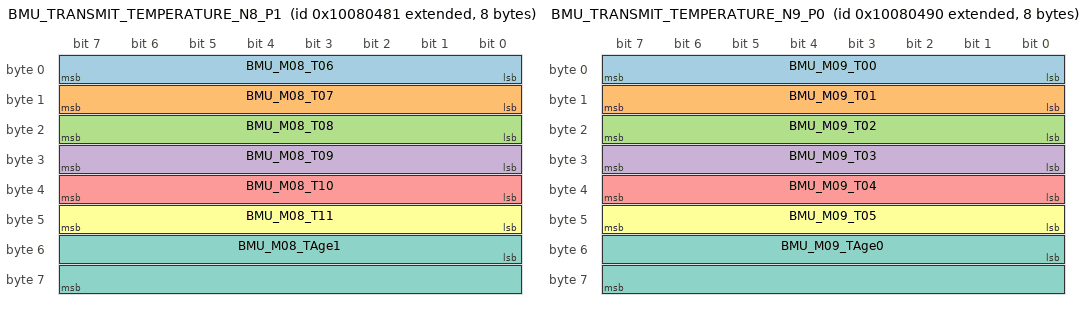
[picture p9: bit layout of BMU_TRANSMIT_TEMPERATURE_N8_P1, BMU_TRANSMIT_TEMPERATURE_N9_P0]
BO_ 2416444545 BMU_TRANSMIT_TEMPERATURE_N8_P1: 8 BMU
 SG_ BMU_M08_T06 : 0|8@1+ (1,0) [0|255] "degC" LOGGER
 SG_ BMU_M08_T07 : 8|8@1+ (1,0) [0|255] "degC" LOGGER
 SG_ BMU_M08_T08 : 16|8@1+ (1,0) [0|255] "degC" LOGGER
 SG_ BMU_M08_T09 : 24|8@1+ (1,0) [0|255] "degC" LOGGER
 SG_ BMU_M08_T10 : 32|8@1+ (1,0) [0|255] "degC" LOGGER
 SG_ BMU_M08_T11 : 40|8@1+ (1,0) [0|255] "degC" LOGGER
 SG_ BMU_M08_TAge1 : 48|16@1+ (1,0) [0|65535] "ms" LOGGER

BO_ 2416444560 BMU_TRANSMIT_TEMPERATURE_N9_P0: 8 BMU
 SG_ BMU_M09_T00 : 0|8@1+ (1,0) [0|255] "degC" LOGGER
 SG_ BMU_M09_T01 : 8|8@1+ (1,0) [0|255] "degC" LOGGER
 SG_ BMU_M09_T02 : 16|8@1+ (1,0) [0|255] "degC" LOGGER
 SG_ BMU_M09_T03 : 24|8@1+ (1,0) [0|255] "degC" LOGGER
 SG_ BMU_M09_T04 : 32|8@1+ (1,0) [0|255] "degC" LOGGER
 SG_ BMU_M09_T05 : 40|8@1+ (1,0) [0|255] "degC" LOGGER
 SG_ BMU_M09_TAge0 : 48|16@1+ (1,0) [0|65535] "ms" LOGGER

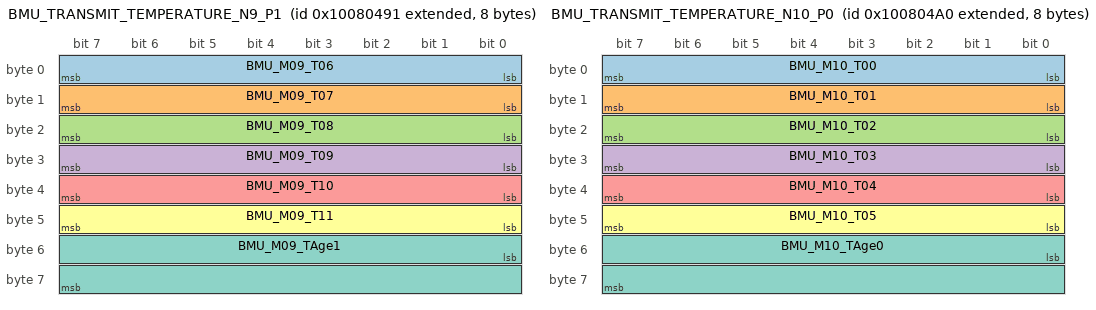
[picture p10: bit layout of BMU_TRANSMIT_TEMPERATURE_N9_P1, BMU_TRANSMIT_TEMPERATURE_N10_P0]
BO_ 2416444561 BMU_TRANSMIT_TEMPERATURE_N9_P1: 8 BMU
 SG_ BMU_M09_T06 : 0|8@1+ (1,0) [0|255] "degC" LOGGER
 SG_ BMU_M09_T07 : 8|8@1+ (1,0) [0|255] "degC" LOGGER
 SG_ BMU_M09_T08 : 16|8@1+ (1,0) [0|255] "degC" LOGGER
 SG_ BMU_M09_T09 : 24|8@1+ (1,0) [0|255] "degC" LOGGER
 SG_ BMU_M09_T10 : 32|8@1+ (1,0) [0|255] "degC" LOGGER
 SG_ BMU_M09_T11 : 40|8@1+ (1,0) [0|255] "degC" LOGGER
 SG_ BMU_M09_TAge1 : 48|16@1+ (1,0) [0|65535] "ms" LOGGER

BO_ 2416444576 BMU_TRANSMIT_TEMPERATURE_N10_P0: 8 BMU
 SG_ BMU_M10_T00 : 0|8@1+ (1,0) [0|255] "degC" LOGGER
 SG_ BMU_M10_T01 : 8|8@1+ (1,0) [0|255] "degC" LOGGER
 SG_ BMU_M10_T02 : 16|8@1+ (1,0) [0|255] "degC" LOGGER
 SG_ BMU_M10_T03 : 24|8@1+ (1,0) [0|255] "degC" LOGGER
 SG_ BMU_M10_T04 : 32|8@1+ (1,0) [0|255] "degC" LOGGER
 SG_ BMU_M10_T05 : 40|8@1+ (1,0) [0|255] "degC" LOGGER
 SG_ BMU_M10_TAge0 : 48|16@1+ (1,0) [0|65535] "ms" LOGGER

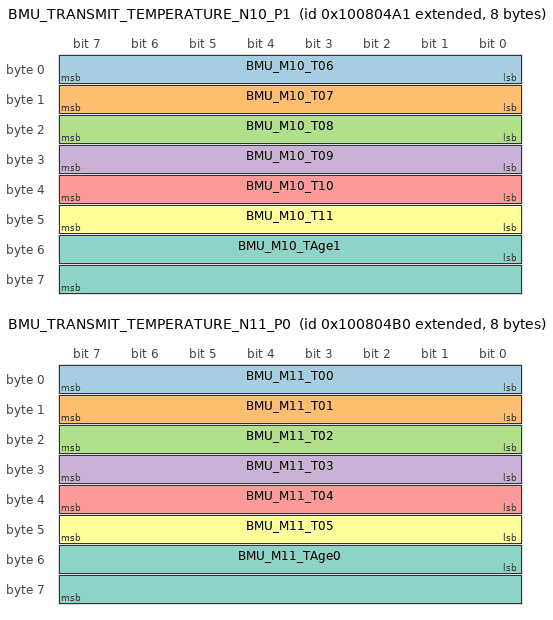
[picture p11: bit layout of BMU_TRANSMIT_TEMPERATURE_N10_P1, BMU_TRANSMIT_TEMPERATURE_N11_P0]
BO_ 2416444577 BMU_TRANSMIT_TEMPERATURE_N10_P1: 8 BMU
 SG_ BMU_M10_T06 : 0|8@1+ (1,0) [0|255] "degC" LOGGER
 SG_ BMU_M10_T07 : 8|8@1+ (1,0) [0|255] "degC" LOGGER
 SG_ BMU_M10_T08 : 16|8@1+ (1,0) [0|255] "degC" LOGGER
 SG_ BMU_M10_T09 : 24|8@1+ (1,0) [0|255] "degC" LOGGER
 SG_ BMU_M10_T10 : 32|8@1+ (1,0) [0|255] "degC" LOGGER
 SG_ BMU_M10_T11 : 40|8@1+ (1,0) [0|255] "degC" LOGGER
 SG_ BMU_M10_TAge1 : 48|16@1+ (1,0) [0|65535] "ms" LOGGER

BO_ 2416444592 BMU_TRANSMIT_TEMPERATURE_N11_P0: 8 BMU
 SG_ BMU_M11_T00 : 0|8@1+ (1,0) [0|255] "degC" LOGGER
 SG_ BMU_M11_T01 : 8|8@1+ (1,0) [0|255] "degC" LOGGER
 SG_ BMU_M11_T02 : 16|8@1+ (1,0) [0|255] "degC" LOGGER
 SG_ BMU_M11_T03 : 24|8@1+ (1,0) [0|255] "degC" LOGGER
 SG_ BMU_M11_T04 : 32|8@1+ (1,0) [0|255] "degC" LOGGER
 SG_ BMU_M11_T05 : 40|8@1+ (1,0) [0|255] "degC" LOGGER
 SG_ BMU_M11_TAge0 : 48|16@1+ (1,0) [0|65535] "ms" LOGGER

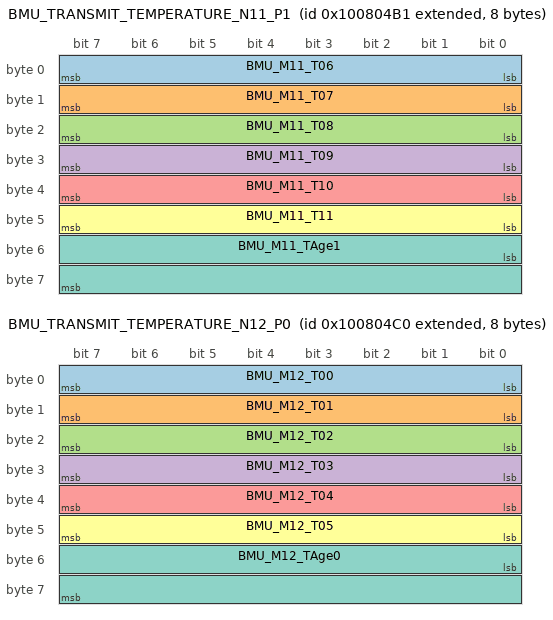
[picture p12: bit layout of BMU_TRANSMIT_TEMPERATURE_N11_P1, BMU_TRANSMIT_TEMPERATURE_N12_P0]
BO_ 2416444593 BMU_TRANSMIT_TEMPERATURE_N11_P1: 8 BMU
 SG_ BMU_M11_T06 : 0|8@1+ (1,0) [0|255] "degC" LOGGER
 SG_ BMU_M11_T07 : 8|8@1+ (1,0) [0|255] "degC" LOGGER
 SG_ BMU_M11_T08 : 16|8@1+ (1,0) [0|255] "degC" LOGGER
 SG_ BMU_M11_T09 : 24|8@1+ (1,0) [0|255] "degC" LOGGER
 SG_ BMU_M11_T10 : 32|8@1+ (1,0) [0|255] "degC" LOGGER
 SG_ BMU_M11_T11 : 40|8@1+ (1,0) [0|255] "degC" LOGGER
 SG_ BMU_M11_TAge1 : 48|16@1+ (1,0) [0|65535] "ms" LOGGER

BO_ 2416444608 BMU_TRANSMIT_TEMPERATURE_N12_P0: 8 BMU
 SG_ BMU_M12_T00 : 0|8@1+ (1,0) [0|255] "degC" LOGGER
 SG_ BMU_M12_T01 : 8|8@1+ (1,0) [0|255] "degC" LOGGER
 SG_ BMU_M12_T02 : 16|8@1+ (1,0) [0|255] "degC" LOGGER
 SG_ BMU_M12_T03 : 24|8@1+ (1,0) [0|255] "degC" LOGGER
 SG_ BMU_M12_T04 : 32|8@1+ (1,0) [0|255] "degC" LOGGER
 SG_ BMU_M12_T05 : 40|8@1+ (1,0) [0|255] "degC" LOGGER
 SG_ BMU_M12_TAge0 : 48|16@1+ (1,0) [0|65535] "ms" LOGGER

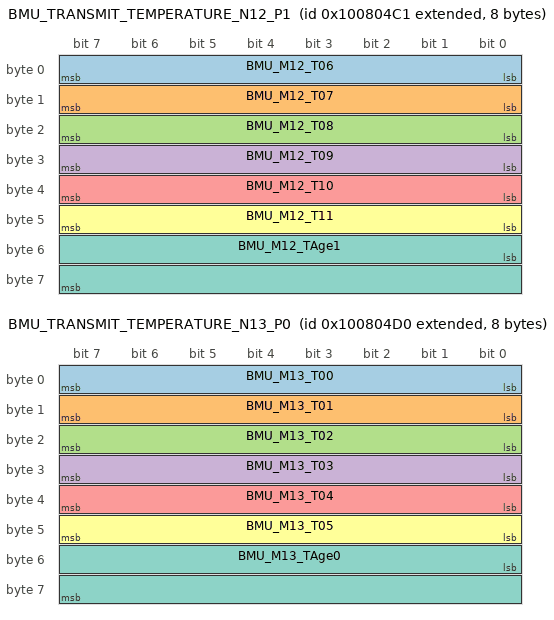
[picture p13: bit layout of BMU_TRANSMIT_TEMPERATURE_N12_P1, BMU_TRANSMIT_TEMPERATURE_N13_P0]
BO_ 2416444609 BMU_TRANSMIT_TEMPERATURE_N12_P1: 8 BMU
 SG_ BMU_M12_T06 : 0|8@1+ (1,0) [0|255] "degC" LOGGER
 SG_ BMU_M12_T07 : 8|8@1+ (1,0) [0|255] "degC" LOGGER
 SG_ BMU_M12_T08 : 16|8@1+ (1,0) [0|255] "degC" LOGGER
 SG_ BMU_M12_T09 : 24|8@1+ (1,0) [0|255] "degC" LOGGER
 SG_ BMU_M12_T10 : 32|8@1+ (1,0) [0|255] "degC" LOGGER
 SG_ BMU_M12_T11 : 40|8@1+ (1,0) [0|255] "degC" LOGGER
 SG_ BMU_M12_TAge1 : 48|16@1+ (1,0) [0|65535] "ms" LOGGER

BO_ 2416444624 BMU_TRANSMIT_TEMPERATURE_N13_P0: 8 BMU
 SG_ BMU_M13_T00 : 0|8@1+ (1,0) [0|255] "degC" LOGGER
 SG_ BMU_M13_T01 : 8|8@1+ (1,0) [0|255] "degC" LOGGER
 SG_ BMU_M13_T02 : 16|8@1+ (1,0) [0|255] "degC" LOGGER
 SG_ BMU_M13_T03 : 24|8@1+ (1,0) [0|255] "degC" LOGGER
 SG_ BMU_M13_T04 : 32|8@1+ (1,0) [0|255] "degC" LOGGER
 SG_ BMU_M13_T05 : 40|8@1+ (1,0) [0|255] "degC" LOGGER
 SG_ BMU_M13_TAge0 : 48|16@1+ (1,0) [0|65535] "ms" LOGGER

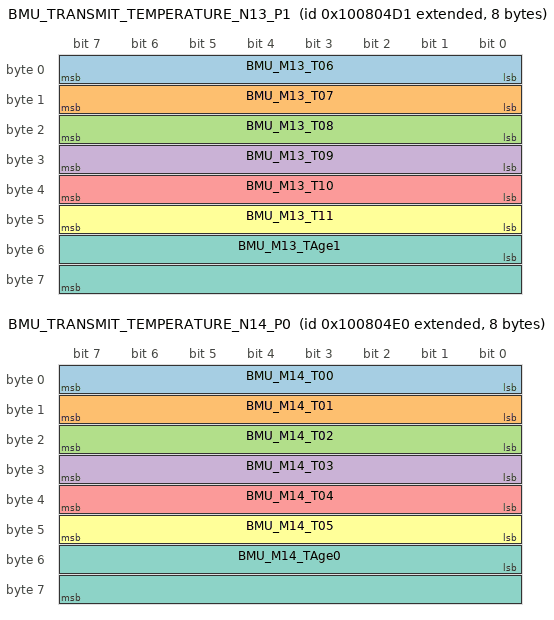
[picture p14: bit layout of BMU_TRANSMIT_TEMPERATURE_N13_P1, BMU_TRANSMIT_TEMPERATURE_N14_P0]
BO_ 2416444625 BMU_TRANSMIT_TEMPERATURE_N13_P1: 8 BMU
 SG_ BMU_M13_T06 : 0|8@1+ (1,0) [0|255] "degC" LOGGER
 SG_ BMU_M13_T07 : 8|8@1+ (1,0) [0|255] "degC" LOGGER
 SG_ BMU_M13_T08 : 16|8@1+ (1,0) [0|255] "degC" LOGGER
 SG_ BMU_M13_T09 : 24|8@1+ (1,0) [0|255] "degC" LOGGER
 SG_ BMU_M13_T10 : 32|8@1+ (1,0) [0|255] "degC" LOGGER
 SG_ BMU_M13_T11 : 40|8@1+ (1,0) [0|255] "degC" LOGGER
 SG_ BMU_M13_TAge1 : 48|16@1+ (1,0) [0|65535] "ms" LOGGER

BO_ 2416444640 BMU_TRANSMIT_TEMPERATURE_N14_P0: 8 BMU
 SG_ BMU_M14_T00 : 0|8@1+ (1,0) [0|255] "degC" LOGGER
 SG_ BMU_M14_T01 : 8|8@1+ (1,0) [0|255] "degC" LOGGER
 SG_ BMU_M14_T02 : 16|8@1+ (1,0) [0|255] "degC" LOGGER
 SG_ BMU_M14_T03 : 24|8@1+ (1,0) [0|255] "degC" LOGGER
 SG_ BMU_M14_T04 : 32|8@1+ (1,0) [0|255] "degC" LOGGER
 SG_ BMU_M14_T05 : 40|8@1+ (1,0) [0|255] "degC" LOGGER
 SG_ BMU_M14_TAge0 : 48|16@1+ (1,0) [0|65535] "ms" LOGGER

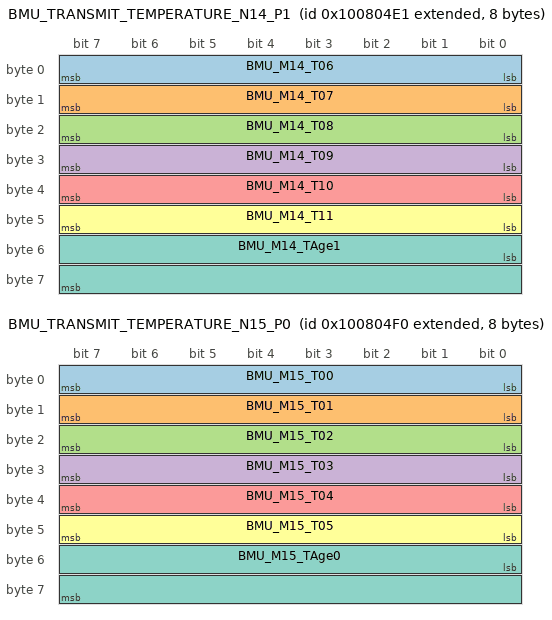
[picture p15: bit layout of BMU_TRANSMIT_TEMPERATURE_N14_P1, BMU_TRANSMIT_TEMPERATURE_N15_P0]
BO_ 2416444641 BMU_TRANSMIT_TEMPERATURE_N14_P1: 8 BMU
 SG_ BMU_M14_T06 : 0|8@1+ (1,0) [0|255] "degC" LOGGER
 SG_ BMU_M14_T07 : 8|8@1+ (1,0) [0|255] "degC" LOGGER
 SG_ BMU_M14_T08 : 16|8@1+ (1,0) [0|255] "degC" LOGGER
 SG_ BMU_M14_T09 : 24|8@1+ (1,0) [0|255] "degC" LOGGER
 SG_ BMU_M14_T10 : 32|8@1+ (1,0) [0|255] "degC" LOGGER
 SG_ BMU_M14_T11 : 40|8@1+ (1,0) [0|255] "degC" LOGGER
 SG_ BMU_M14_TAge1 : 48|16@1+ (1,0) [0|65535] "ms" LOGGER

BO_ 2416444656 BMU_TRANSMIT_TEMPERATURE_N15_P0: 8 BMU
 SG_ BMU_M15_T00 : 0|8@1+ (1,0) [0|255] "degC" LOGGER
 SG_ BMU_M15_T01 : 8|8@1+ (1,0) [0|255] "degC" LOGGER
 SG_ BMU_M15_T02 : 16|8@1+ (1,0) [0|255] "degC" LOGGER
 SG_ BMU_M15_T03 : 24|8@1+ (1,0) [0|255] "degC" LOGGER
 SG_ BMU_M15_T04 : 32|8@1+ (1,0) [0|255] "degC" LOGGER
 SG_ BMU_M15_T05 : 40|8@1+ (1,0) [0|255] "degC" LOGGER
 SG_ BMU_M15_TAge0 : 48|16@1+ (1,0) [0|65535] "ms" LOGGER

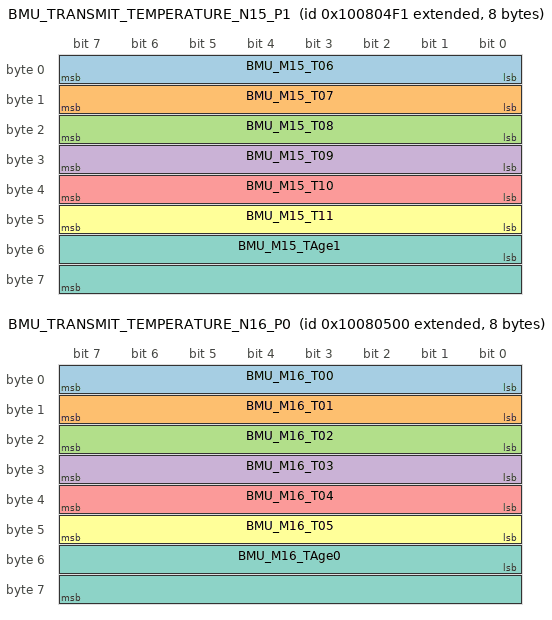
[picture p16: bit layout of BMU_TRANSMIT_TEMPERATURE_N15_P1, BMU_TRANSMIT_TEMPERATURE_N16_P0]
BO_ 2416444657 BMU_TRANSMIT_TEMPERATURE_N15_P1: 8 BMU
 SG_ BMU_M15_T06 : 0|8@1+ (1,0) [0|255] "degC" LOGGER
 SG_ BMU_M15_T07 : 8|8@1+ (1,0) [0|255] "degC" LOGGER
 SG_ BMU_M15_T08 : 16|8@1+ (1,0) [0|255] "degC" LOGGER
 SG_ BMU_M15_T09 : 24|8@1+ (1,0) [0|255] "degC" LOGGER
 SG_ BMU_M15_T10 : 32|8@1+ (1,0) [0|255] "degC" LOGGER
 SG_ BMU_M15_T11 : 40|8@1+ (1,0) [0|255] "degC" LOGGER
 SG_ BMU_M15_TAge1 : 48|16@1+ (1,0) [0|65535] "ms" LOGGER

BO_ 2416444672 BMU_TRANSMIT_TEMPERATURE_N16_P0: 8 BMU
 SG_ BMU_M16_T00 : 0|8@1+ (1,0) [0|255] "degC" LOGGER
 SG_ BMU_M16_T01 : 8|8@1+ (1,0) [0|255] "degC" LOGGER
 SG_ BMU_M16_T02 : 16|8@1+ (1,0) [0|255] "degC" LOGGER
 SG_ BMU_M16_T03 : 24|8@1+ (1,0) [0|255] "degC" LOGGER
 SG_ BMU_M16_T04 : 32|8@1+ (1,0) [0|255] "degC" LOGGER
 SG_ BMU_M16_T05 : 40|8@1+ (1,0) [0|255] "degC" LOGGER
 SG_ BMU_M16_TAge0 : 48|16@1+ (1,0) [0|65535] "ms" LOGGER

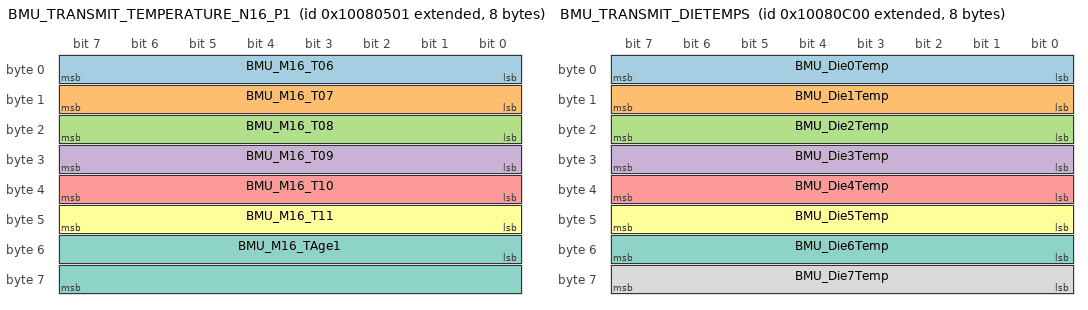
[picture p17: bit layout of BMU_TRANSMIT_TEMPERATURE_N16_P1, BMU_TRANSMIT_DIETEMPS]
BO_ 2416444673 BMU_TRANSMIT_TEMPERATURE_N16_P1: 8 BMU
 SG_ BMU_M16_T06 : 0|8@1+ (1,0) [0|255] "degC" LOGGER
 SG_ BMU_M16_T07 : 8|8@1+ (1,0) [0|255] "degC" LOGGER
 SG_ BMU_M16_T08 : 16|8@1+ (1,0) [0|255] "degC" LOGGER
 SG_ BMU_M16_T09 : 24|8@1+ (1,0) [0|255] "degC" LOGGER
 SG_ BMU_M16_T10 : 32|8@1+ (1,0) [0|255] "degC" LOGGER
 SG_ BMU_M16_T11 : 40|8@1+ (1,0) [0|255] "degC" LOGGER
 SG_ BMU_M16_TAge1 : 48|16@1+ (1,0) [0|65535] "ms" LOGGER

BO_ 2416444688 BMU_TRANSMIT_TEMPERATURE_N17_P0: 8 BMU
 SG_ BMU_M17_T00 : 0|8@1+ (1,0) [0|255] "degC" LOGGER
 SG_ BMU_M17_T01 : 8|8@1+ (1,0) [0|255] "degC" LOGGER
 SG_ BMU_M17_T02 : 16|8@1+ (1,0) [0|255] "degC" LOGGER
 SG_ BMU_M17_T03 : 24|8@1+ (1,0) [0|255] "degC" LOGGER
 SG_ BMU_M17_T04 : 32|8@1+ (1,0) [0|255] "degC" LOGGER
 SG_ BMU_M17_T05 : 40|8@1+ (1,0) [0|255] "degC" LOGGER
 SG_ BMU_M17_TAge0 : 48|16@1+ (1,0) [0|65535] "ms" LOGGER

BO_ 2416444689 BMU_TRANSMIT_TEMPERATURE_N17_P1: 8 BMU
 SG_ BMU_M17_T06 : 0|8@1+ (1,0) [0|255] "degC" LOGGER
 SG_ BMU_M17_T07 : 8|8@1+ (1,0) [0|255] "degC" LOGGER
 SG_ BMU_M17_T08 : 16|8@1+ (1,0) [0|255] "degC" LOGGER
 SG_ BMU_M17_T09 : 24|8@1+ (1,0) [0|255] "degC" LOGGER
 SG_ BMU_M17_T10 : 32|8@1+ (1,0) [0|255] "degC" LOGGER
 SG_ BMU_M17_T11 : 40|8@1+ (1,0) [0|255] "degC" LOGGER
 SG_ BMU_M17_TAge1 : 48|16@1+ (1,0) [0|65535] "ms" LOGGER

BO_ 2416444704 BMU_TRANSMIT_TEMPERATURE_N18_P0: 8 BMU
 SG_ BMU_M18_T00 : 0|8@1+ (1,0) [0|255] "degC" LOGGER
 SG_ BMU_M18_T01 : 8|8@1+ (1,0) [0|255] "degC" LOGGER
 SG_ BMU_M18_T02 : 16|8@1+ (1,0) [0|255] "degC" LOGGER
 SG_ BMU_M18_T03 : 24|8@1+ (1,0) [0|255] "degC" LOGGER
 SG_ BMU_M18_T04 : 32|8@1+ (1,0) [0|255] "degC" LOGGER
 SG_ BMU_M18_T05 : 40|8@1+ (1,0) [0|255] "degC" LOGGER
 SG_ BMU_M18_TAge0 : 48|16@1+ (1,0) [0|65535] "ms" LOGGER

BO_ 2416444705 BMU_TRANSMIT_TEMPERATURE_N18_P1: 8 BMU
 SG_ BMU_M18_T06 : 0|8@1+ (1,0) [0|255] "degC" LOGGER
 SG_ BMU_M18_T07 : 8|8@1+ (1,0) [0|255] "degC" LOGGER
 SG_ BMU_M18_T08 : 16|8@1+ (1,0) [0|255] "degC" LOGGER
 SG_ BMU_M18_T09 : 24|8@1+ (1,0) [0|255] "degC" LOGGER
 SG_ BMU_M18_T10 : 32|8@1+ (1,0) [0|255] "degC" LOGGER
 SG_ BMU_M18_T11 : 40|8@1+ (1,0) [0|255] "degC" LOGGER
 SG_ BMU_M18_TAge1 : 48|16@1+ (1,0) [0|65535] "ms" LOGGER

BO_ 2416444720 BMU_TRANSMIT_TEMPERATURE_N19_P0: 8 BMU
 SG_ BMU_M19_T00 : 0|8@1+ (1,0) [0|255] "degC" LOGGER
 SG_ BMU_M19_T01 : 8|8@1+ (1,0) [0|255] "degC" LOGGER
 SG_ BMU_M19_T02 : 16|8@1+ (1,0) [0|255] "degC" LOGGER
 SG_ BMU_M19_T03 : 24|8@1+ (1,0) [0|255] "degC" LOGGER
 SG_ BMU_M19_T04 : 32|8@1+ (1,0) [0|255] "degC" LOGGER
 SG_ BMU_M19_T05 : 40|8@1+ (1,0) [0|255] "degC" LOGGER
 SG_ BMU_M19_TAge0 : 48|16@1+ (1,0) [0|65535] "ms" LOGGER

BO_ 2416444721 BMU_TRANSMIT_TEMPERATURE_N19_P1: 8 BMU
 SG_ BMU_M19_T06 : 0|8@1+ (1,0) [0|255] "degC" LOGGER
 SG_ BMU_M19_T07 : 8|8@1+ (1,0) [0|255] "degC" LOGGER
 SG_ BMU_M19_T08 : 16|8@1+ (1,0) [0|255] "degC" LOGGER
 SG_ BMU_M19_T09 : 24|8@1+ (1,0) [0|255] "degC" LOGGER
 SG_ BMU_M19_T10 : 32|8@1+ (1,0) [0|255] "degC" LOGGER
 SG_ BMU_M19_T11 : 40|8@1+ (1,0) [0|255] "degC" LOGGER
 SG_ BMU_M19_TAge1 : 48|16@1+ (1,0) [0|65535] "ms" LOGGER

BO_ 2416444736 BMU_TRANSMIT_TEMPERATURE_N20_P0: 8 BMU
 SG_ BMU_M20_T00 : 0|8@1+ (1,0) [0|255] "degC" LOGGER
 SG_ BMU_M20_T01 : 8|8@1+ (1,0) [0|255] "degC" LOGGER
 SG_ BMU_M20_T02 : 16|8@1+ (1,0) [0|255] "degC" LOGGER
 SG_ BMU_M20_T03 : 24|8@1+ (1,0) [0|255] "degC" LOGGER
 SG_ BMU_M20_T04 : 32|8@1+ (1,0) [0|255] "degC" LOGGER
 SG_ BMU_M20_T05 : 40|8@1+ (1,0) [0|255] "degC" LOGGER
 SG_ BMU_M20_TAge0 : 48|16@1+ (1,0) [0|65535] "ms" LOGGER

BO_ 2416444737 BMU_TRANSMIT_TEMPERATURE_N20_P1: 8 BMU
 SG_ BMU_M20_T06 : 0|8@1+ (1,0) [0|255] "degC" LOGGER
 SG_ BMU_M20_T07 : 8|8@1+ (1,0) [0|255] "degC" LOGGER
 SG_ BMU_M20_T08 : 16|8@1+ (1,0) [0|255] "degC" LOGGER
 SG_ BMU_M20_T09 : 24|8@1+ (1,0) [0|255] "degC" LOGGER
 SG_ BMU_M20_T10 : 32|8@1+ (1,0) [0|255] "degC" LOGGER
 SG_ BMU_M20_T11 : 40|8@1+ (1,0) [0|255] "degC" LOGGER
 SG_ BMU_M20_TAge1 : 48|16@1+ (1,0) [0|65535] "ms" LOGGER

BO_ 2416444752 BMU_TRANSMIT_TEMPERATURE_N21_P0: 8 BMU
 SG_ BMU_M21_T00 : 0|8@1+ (1,0) [0|255] "degC" LOGGER
 SG_ BMU_M21_T01 : 8|8@1+ (1,0) [0|255] "degC" LOGGER
 SG_ BMU_M21_T02 : 16|8@1+ (1,0) [0|255] "degC" LOGGER
 SG_ BMU_M21_T03 : 24|8@1+ (1,0) [0|255] "degC" LOGGER
 SG_ BMU_M21_T04 : 32|8@1+ (1,0) [0|255] "degC" LOGGER
 SG_ BMU_M21_T05 : 40|8@1+ (1,0) [0|255] "degC" LOGGER
 SG_ BMU_M21_TAge0 : 48|16@1+ (1,0) [0|65535] "ms" LOGGER

BO_ 2416444753 BMU_TRANSMIT_TEMPERATURE_N21_P1: 8 BMU
 SG_ BMU_M21_T06 : 0|8@1+ (1,0) [0|255] "degC" LOGGER
 SG_ BMU_M21_T07 : 8|8@1+ (1,0) [0|255] "degC" LOGGER
 SG_ BMU_M21_T08 : 16|8@1+ (1,0) [0|255] "degC" LOGGER
 SG_ BMU_M21_T09 : 24|8@1+ (1,0) [0|255] "degC" LOGGER
 SG_ BMU_M21_T10 : 32|8@1+ (1,0) [0|255] "degC" LOGGER
 SG_ BMU_M21_T11 : 40|8@1+ (1,0) [0|255] "degC" LOGGER
 SG_ BMU_M21_TAge1 : 48|16@1+ (1,0) [0|65535] "ms" LOGGER

BO_ 2416444768 BMU_TRANSMIT_TEMPERATURE_N22_P0: 8 BMU
 SG_ BMU_M22_T00 : 0|8@1+ (1,0) [0|255] "degC" LOGGER
 SG_ BMU_M22_T01 : 8|8@1+ (1,0) [0|255] "degC" LOGGER
 SG_ BMU_M22_T02 : 16|8@1+ (1,0) [0|255] "degC" LOGGER
 SG_ BMU_M22_T03 : 24|8@1+ (1,0) [0|255] "degC" LOGGER
 SG_ BMU_M22_T04 : 32|8@1+ (1,0) [0|255] "degC" LOGGER
 SG_ BMU_M22_T05 : 40|8@1+ (1,0) [0|255] "degC" LOGGER
 SG_ BMU_M22_TAge0 : 48|16@1+ (1,0) [0|65535] "ms" LOGGER

BO_ 2416444769 BMU_TRANSMIT_TEMPERATURE_N22_P1: 8 BMU
 SG_ BMU_M22_T06 : 0|8@1+ (1,0) [0|255] "degC" LOGGER
 SG_ BMU_M22_T07 : 8|8@1+ (1,0) [0|255] "degC" LOGGER
 SG_ BMU_M22_T08 : 16|8@1+ (1,0) [0|255] "degC" LOGGER
 SG_ BMU_M22_T09 : 24|8@1+ (1,0) [0|255] "degC" LOGGER
 SG_ BMU_M22_T10 : 32|8@1+ (1,0) [0|255] "degC" LOGGER
 SG_ BMU_M22_T11 : 40|8@1+ (1,0) [0|255] "degC" LOGGER
 SG_ BMU_M22_TAge1 : 48|16@1+ (1,0) [0|65535] "ms" LOGGER

BO_ 2416444784 BMU_TRANSMIT_TEMPERATURE_N23_P0: 8 BMU
 SG_ BMU_M23_T00 : 0|8@1+ (1,0) [0|255] "degC" LOGGER
 SG_ BMU_M23_T01 : 8|8@1+ (1,0) [0|255] "degC" LOGGER
 SG_ BMU_M23_T02 : 16|8@1+ (1,0) [0|255] "degC" LOGGER
 SG_ BMU_M23_T03 : 24|8@1+ (1,0) [0|255] "degC" LOGGER
 SG_ BMU_M23_T04 : 32|8@1+ (1,0) [0|255] "degC" LOGGER
 SG_ BMU_M23_T05 : 40|8@1+ (1,0) [0|255] "degC" LOGGER
 SG_ BMU_M23_TAge0 : 48|16@1+ (1,0) [0|65535] "ms" LOGGER

BO_ 2416444785 BMU_TRANSMIT_TEMPERATURE_N23_P1: 8 BMU
 SG_ BMU_M23_T06 : 0|8@1+ (1,0) [0|255] "degC" LOGGER
 SG_ BMU_M23_T07 : 8|8@1+ (1,0) [0|255] "degC" LOGGER
 SG_ BMU_M23_T08 : 16|8@1+ (1,0) [0|255] "degC" LOGGER
 SG_ BMU_M23_T09 : 24|8@1+ (1,0) [0|255] "degC" LOGGER
 SG_ BMU_M23_T10 : 32|8@1+ (1,0) [0|255] "degC" LOGGER
 SG_ BMU_M23_T11 : 40|8@1+ (1,0) [0|255] "degC" LOGGER
 SG_ BMU_M23_TAge1 : 48|16@1+ (1,0) [0|65535] "ms" LOGGER

BO_ 2416445440 BMU_TRANSMIT_BALANCING_N0: 8 BMU
 SG_ BMU_M00_Balance : 0|16@1+ (1,0) [0|65535] "" LOGGER
 SG_ BMU_M00_DieTemp : 16|8@1+ (1,0) [0|255] "degC" LOGGER

BO_ 2416445456 BMU_TRANSMIT_BALANCING_N1: 8 BMU
 SG_ BMU_M01_Balance : 0|16@1+ (1,0) [0|65535] "" LOGGER
 SG_ BMU_M01_DieTemp : 16|8@1+ (1,0) [0|255] "degC" LOGGER

BO_ 2416445472 BMU_TRANSMIT_BALANCING_N2: 8 BMU
 SG_ BMU_M02_Balance : 0|16@1+ (1,0) [0|65535] "" LOGGER
 SG_ BMU_M02_DieTemp : 16|8@1+ (1,0) [0|255] "degC" LOGGER

BO_ 2416445488 BMU_TRANSMIT_BALANCING_N3: 8 BMU
 SG_ BMU_M03_Balance : 0|16@1+ (1,0) [0|65535] "" LOGGER
 SG_ BMU_M03_DieTemp : 16|8@1+ (1,0) [0|255] "degC" LOGGER

BO_ 2416445504 BMU_TRANSMIT_BALANCING_N4: 8 BMU
 SG_ BMU_M04_Balance : 0|16@1+ (1,0) [0|65535] "" LOGGER
 SG_ BMU_M04_DieTemp : 16|8@1+ (1,0) [0|255] "degC" LOGGER

BO_ 2416445520 BMU_TRANSMIT_BALANCING_N5: 8 BMU
 SG_ BMU_M05_Balance : 0|16@1+ (1,0) [0|65535] "" LOGGER
 SG_ BMU_M05_DieTemp : 16|8@1+ (1,0) [0|255] "degC" LOGGER

BO_ 2416445536 BMU_TRANSMIT_BALANCING_N6: 8 BMU
 SG_ BMU_M06_Balance : 0|16@1+ (1,0) [0|65535] "" LOGGER
 SG_ BMU_M06_DieTemp : 16|8@1+ (1,0) [0|255] "degC" LOGGER

BO_ 2416445552 BMU_TRANSMIT_BALANCING_N7: 8 BMU
 SG_ BMU_M07_Balance : 0|16@1+ (1,0) [0|65535] "" LOGGER
 SG_ BMU_M07_DieTemp : 16|8@1+ (1,0) [0|255] "degC" LOGGER

BO_ 2416445568 BMU_TRANSMIT_BALANCING_N8: 8 BMU
 SG_ BMU_M08_Balance : 0|16@1+ (1,0) [0|65535] "" LOGGER
 SG_ BMU_M08_DieTemp : 16|8@1+ (1,0) [0|255] "degC" LOGGER

BO_ 2416445584 BMU_TRANSMIT_BALANCING_N9: 8 BMU
 SG_ BMU_M09_Balance : 0|16@1+ (1,0) [0|65535] "" LOGGER
 SG_ BMU_M09_DieTemp : 16|8@1+ (1,0) [0|255] "degC" LOGGER

BO_ 2416445600 BMU_TRANSMIT_BALANCING_N10: 8 BMU
 SG_ BMU_M10_Balance : 0|16@1+ (1,0) [0|65535] "" LOGGER
 SG_ BMU_M10_DieTemp : 16|8@1+ (1,0) [0|255] "degC" LOGGER

BO_ 2416445616 BMU_TRANSMIT_BALANCING_N11: 8 BMU
 SG_ BMU_M11_Balance : 0|16@1+ (1,0) [0|65535] "" LOGGER
 SG_ BMU_M11_DieTemp : 16|8@1+ (1,0) [0|255] "degC" LOGGER

BO_ 2416445632 BMU_TRANSMIT_BALANCING_N12: 8 BMU
 SG_ BMU_M12_Balance : 0|16@1+ (1,0) [0|65535] "" LOGGER
 SG_ BMU_M12_DieTemp : 16|8@1+ (1,0) [0|255] "degC" LOGGER

BO_ 2416445648 BMU_TRANSMIT_BALANCING_N13: 8 BMU
 SG_ BMU_M13_Balance : 0|16@1+ (1,0) [0|65535] "" LOGGER
 SG_ BMU_M13_DieTemp : 16|8@1+ (1,0) [0|255] "degC" LOGGER

BO_ 2416445664 BMU_TRANSMIT_BALANCING_N14: 8 BMU
 SG_ BMU_M14_Balance : 0|16@1+ (1,0) [0|65535] "" LOGGER
 SG_ BMU_M14_DieTemp : 16|8@1+ (1,0) [0|255] "degC" LOGGER

BO_ 2416445680 BMU_TRANSMIT_BALANCING_N15: 8 BMU
 SG_ BMU_M15_Balance : 0|16@1+ (1,0) [0|65535] "" LOGGER
 SG_ BMU_M15_DieTemp : 16|8@1+ (1,0) [0|255] "degC" LOGGER

BO_ 2416445696 BMU_TRANSMIT_BALANCING_N16: 8 BMU
 SG_ BMU_M16_Balance : 0|16@1+ (1,0) [0|65535] "" LOGGER
 SG_ BMU_M16_DieTemp : 16|8@1+ (1,0) [0|255] "degC" LOGGER

BO_ 2416445712 BMU_TRANSMIT_BALANCING_N17: 8 BMU
 SG_ BMU_M17_Balance : 0|16@1+ (1,0) [0|65535] "" LOGGER
 SG_ BMU_M17_DieTemp : 16|8@1+ (1,0) [0|255] "degC" LOGGER

BO_ 2416445728 BMU_TRANSMIT_BALANCING_N18: 8 BMU
 SG_ BMU_M18_Balance : 0|16@1+ (1,0) [0|65535] "" LOGGER
 SG_ BMU_M18_DieTemp : 16|8@1+ (1,0) [0|255] "degC" LOGGER

BO_ 2416445744 BMU_TRANSMIT_BALANCING_N19: 8 BMU
 SG_ BMU_M19_Balance : 0|16@1+ (1,0) [0|65535] "" LOGGER
 SG_ BMU_M19_DieTemp : 16|8@1+ (1,0) [0|255] "degC" LOGGER

BO_ 2416445760 BMU_TRANSMIT_BALANCING_N20: 8 BMU
 SG_ BMU_M20_Balance : 0|16@1+ (1,0) [0|65535] "" LOGGER
 SG_ BMU_M20_DieTemp : 16|8@1+ (1,0) [0|255] "degC" LOGGER

BO_ 2416445776 BMU_TRANSMIT_BALANCING_N21: 8 BMU
 SG_ BMU_M21_Balance : 0|16@1+ (1,0) [0|65535] "" LOGGER
 SG_ BMU_M21_DieTemp : 16|8@1+ (1,0) [0|255] "degC" LOGGER

BO_ 2416445792 BMU_TRANSMIT_BALANCING_N22: 8 BMU
 SG_ BMU_M22_Balance : 0|16@1+ (1,0) [0|65535] "" LOGGER
 SG_ BMU_M22_DieTemp : 16|8@1+ (1,0) [0|255] "degC" LOGGER

BO_ 2416445808 BMU_TRANSMIT_BALANCING_N23: 8 BMU
 SG_ BMU_M23_Balance : 0|16@1+ (1,0) [0|65535] "" LOGGER
 SG_ BMU_M23_DieTemp : 16|8@1+ (1,0) [0|255] "degC" LOGGER

BO_ 2416446464 BMU_TRANSMIT_DIETEMPS: 8 BMU
 SG_ BMU_Die0Temp : 0|8@1+ (1,0) [0|255] "degC" LOGGER
 SG_ BMU_Die1Temp : 8|8@1+ (1,0) [0|255] "degC" LOGGER
 SG_ BMU_Die2Temp : 16|8@1+ (1,0) [0|255] "degC" LOGGER
 SG_ BMU_Die3Temp : 24|8@1+ (1,0) [0|255] "degC" LOGGER
 SG_ BMU_Die4Temp : 32|8@1+ (1,0) [0|255] "degC" LOGGER
 SG_ BMU_Die5Temp : 40|8@1+ (1,0) [0|255] "degC" LOGGER
 SG_ BMU_Die6Temp : 48|8@1+ (1,0) [0|255] "degC" LOGGER
 SG_ BMU_Die7Temp : 56|8@1+ (1,0) [0|255] "degC" LOGGER

BO_ 2416446720 BMU_TRANSMIT_PACKINFO: 8 BMU
 SG_ BMU_PackCurrent : 0|32@1- (0.001,0) [-2147483.648|2147483.6469999999] "A" ECU,C125
 SG_ BMU_PackVoltage : 32|32@1- (0.001,0) [-2147483.648|2147483.6469999999] "V" ECU,C125

BO_ 2416446736 BMU_TRANSMIT_PACKSUMMARY: 8 BMU
 SG_ BMU_MinCell : 0|16@1+ (1,0) [0|65535] "mV" ECU,C125
 SG_ BMU_CellSum : 16|32@1+ (1,0) [0|4294967295] "mV" ECU,C125
 SG_ BMU_ValidCells : 48|8@1+ (1,0) [0|255] "" ECU,C125
 SG_ BMU_MaxCellTemp : 56|8@1+ (1,0) [0|255] "degC" ECU,C125

BO_ 2416446752 BMU_TRANSMIT_SOC: 8 BMU
 SG_ BMU_SocPct : 0|8@1+ (1,0) [0|255] "%" C125
 SG_ BMU_SocValid : 8|1@1+ (1,0) [0|1] "" C125
 SG_ BMU_SocCalibrated : 9|1@1+ (1,0) [0|1] "" C125
 SG_ BMU_Charge : 16|32@1- (0.000001,0) [-2147.483648|2147.483647] "Ah" C125

BO_ 2416446768 BMU_TRANSMIT_CELL_EXTREMES: 8 BMU
 SG_ BMU_MaxCell : 0|16@1+ (1,0) [0|65535] "mV" C125
 SG_ BMU_AvgCell : 16|16@1+ (1,0) [0|65535] "mV" C125
 SG_ BMU_MinCellTemp : 32|8@1+ (1,0) [0|255] "degC" C125
 SG_ BMU_AvgCellTemp : 40|8@1+ (1,0) [0|255] "degC" C125
 SG_ BMU_MinCellIdx : 48|8@1+ (1,0) [0|255] "" C125
 SG_ BMU_MaxCellIdx : 56|8@1+ (1,0) [0|255] "" C125

BO_ 2416446976 BMU_TRANSMIT_POWER: 8 BMU
 SG_ BMU_PackPower : 0|32@1- (1,0) [-2147483648|2147483647] "W" Vector__XXX

BO_ 2418327552 BMU25_Heartbeat: 8 BMU
 SG_ BMU_State : 0|8@1+ (1,0) [0|255] "" ECU,C125
 SG_ BMU_F_HbCmu : 8|1@1+ (1,0) [0|1] "" ECU,C125
 SG_ BMU_F_HbSendyne1 : 9|1@1+ (1,0) [0|1] "" ECU,C125
 SG_ BMU_F_HbSendyne2 : 10|1@1+ (1,0) [0|1] "" ECU,C125
 SG_ BMU_F_HbEcu : 11|1@1+ (1,0) [0|1] "" ECU,C125
 SG_ BMU_F_HbChrgCtrl : 12|1@1+ (1,0) [0|1] "" ECU,C125
 SG_ BMU_F_Watchdog : 13|1@1+ (1,0) [0|1] "" ECU,C125
 SG_ BMU_F_Can1 : 14|1@1+ (1,0) [0|1] "" ECU,C125
 SG_ BMU_F_Can2 : 15|1@1+ (1,0) [0|1] "" ECU,C125
 SG_ BMU_F_ContactorPos : 16|1@1+ (1,0) [0|1] "" ECU,C125
 SG_ BMU_F_ContactorNeg : 17|1@1+ (1,0) [0|1] "" ECU,C125
 SG_ BMU_F_ContactorPchrg : 18|1@1+ (1,0) [0|1] "" ECU,C125
 SG_ BMU_F_PrechargeTimeout : 19|1@1+ (1,0) [0|1] "" ECU,C125
 SG_ BMU_F_CmuOverVolt : 20|1@1+ (1,0) [0|1] "" ECU,C125
 SG_ BMU_F_CmuUnderVolt : 21|1@1+ (1,0) [0|1] "" ECU,C125
 SG_ BMU_F_CmuBadTemp : 22|1@1+ (1,0) [0|1] "" ECU,C125
 SG_ BMU_F_CmuOpenVolt : 23|1@1+ (1,0) [0|1] "" ECU,C125
 SG_ BMU_F_CmuOpenTemp : 24|1@1+ (1,0) [0|1] "" ECU,C125
 SG_ BMU_F_CmuMissingVolt : 25|1@1+ (1,0) [0|1] "" ECU,C125
 SG_ BMU_F_CmuMissingTemp : 26|1@1+ (1,0) [0|1] "" ECU,C125
 SG_ BMU_F_ShdnBmu : 27|1@1+ (1,0) [0|1] "" ECU,C125
 SG_ BMU_F_ShdnPdoc : 28|1@1+ (1,0) [0|1] "" ECU,C125
 SG_ BMU_F_ShdnImd : 29|1@1+ (1,0) [0|1] "" ECU,C125
 SG_ BMU_F_ShdnInterlock : 30|1@1+ (1,0) [0|1] "" ECU,C125
 SG_ BMU_F_Balancing : 31|1@1+ (1,0) [0|1] "" ECU,C125
 SG_ BMU_F_DieTemps : 32|1@1+ (1,0) [0|1] "" ECU,C125
 SG_ BMU_F_HvKey : 33|1@1+ (1,0) [0|1] "" ECU,C125
 SG_ BMU_F_ChrgDetect : 34|1@1+ (1,0) [0|1] "" ECU,C125
 SG_ BMU_F_ChrgCtrl : 35|1@1+ (1,0) [0|1] "" ECU,C125
 SG_ BMU_PackState : 40|8@1+ (1,0) [0|255] "" ECU
 SG_ BMU_SOC : 48|8@1+ (1,0) [0|255] "%" ECU

BO_ 2424356864 VCU_Heartbeat_CTRL: 8 ECU
 SG_ VCU_Heartbeat_StateID : 0|8@1+ (1,0) [0|255] "" Vector__XXX
 SG_ fault_code : 8|16@1+ (1,0) [0|65535] "" Vector__XXX
 SG_ active_profile : 24|8@1+ (1,0) [0|255] "" Vector__XXX
 SG_ HB_FLAG_BMU_ALIVE : 32|1@1+ (1,0) [0|1] "" Vector__XXX
 SG_ HB_FLAG_INV_ALIVE : 33|1@1+ (1,0) [0|1] "" Vector__XXX
 SG_ HB_FLAG_SHDN_CLOSED : 34|1@1+ (1,0) [0|1] "" Vector__XXX
 SG_ HB_FLAG_PEDAL_OK : 35|1@1+ (1,0) [0|1] "" Vector__XXX
 SG_ HB_FLAG_BRAKE_PRESSED : 36|1@1+ (1,0) [0|1] "" Vector__XXX
 SG_ HB_FLAG_PRECHARGE_REQ : 37|1@1+ (1,0) [0|1] "" Vector__XXX
 SG_ HB_FLAG_TORQUE_ALLOWED : 38|1@1+ (1,0) [0|1] "" Vector__XXX
 SG_ HB_FLAG_OUTPUT_FAULT : 39|1@1+ (1,0) [0|1] "" Vector__XXX
 SG_ HB_FLAG_CAN_B_OK : 40|1@1+ (1,0) [0|1] "" Vector__XXX
 SG_ HB_FLAG_WARNING : 41|1@1+ (1,0) [0|1] "" Vector__XXX
 SG_ HB_FLAG_EEPROM_OK : 42|1@1+ (1,0) [0|1] "" Vector__XXX
 SG_ HB_FLAG_CALIBRATED : 43|1@1+ (1,0) [0|1] "" Vector__XXX
 SG_ VCU_Heartbeat_Flags_spare : 44|4@1+ (1,0) [0|15] "" Vector__XXX
 SG_ VCU_WARN_PedalPolarity : 48|1@1+ (1,0) [0|1] "" Vector__XXX
 SG_ VCU_Heartbeat_Reserved : 49|15@1+ (1,0) [0|32767] "s" Vector__XXX

BO_ 2424356865 ECU_BMU_COMP25_HEARTBEAT: 8 ECU
 SG_ ECU_C25_State : 0|8@1+ (1,0) [0|255] "" BMU

BO_ 2424357104 ECU_DEBUG_REQ_OLD: 8 TOOL
 SG_ DBG_ReqCmd : 0|8@1+ (1,0) [0|255] "" ECU
 SG_ DBG_ReqIndex : 8|8@1+ (1,0) [0|255] "" ECU
 SG_ DBG_ReqArg : 16|32@1+ (1,0) [0|4294967295] "" ECU

BO_ 2424357105 ECU_DEBUG_RESP_OLD: 8 ECU
 SG_ DBG_RespCmd : 0|8@1+ (1,0) [0|255] "" TOOL
 SG_ DBG_RespIndex : 8|8@1+ (1,0) [0|255] "" TOOL
 SG_ DBG_RespStatus : 16|8@1+ (1,0) [0|255] "" TOOL
 SG_ DBG_RespValue : 24|32@1+ (1,0) [0|4294967295] "" TOOL
 SG_ DBG_RespExtra : 56|8@1+ (1,0) [0|255] "" TOOL

BO_ 2554855424 ECU_DEBUG_RESP: 8 ECU
 SG_ DBG_RespCmd : 0|8@1+ (1,0) [0|255] "" TOOL
 SG_ DBG_RespIndex : 8|8@1+ (1,0) [0|255] "" TOOL
 SG_ DBG_RespStatus : 16|8@1+ (1,0) [0|255] "" TOOL
 SG_ DBG_RespValue : 24|32@1+ (1,0) [0|4294967295] "" TOOL
 SG_ DBG_RespExtra : 56|8@1+ (1,0) [0|255] "" TOOL

BO_ 2555117568 ECU_DEBUG_REQ: 8 TOOL
 SG_ DBG_ReqCmd : 0|8@1+ (1,0) [0|255] "" ECU
 SG_ DBG_ReqIndex : 8|8@1+ (1,0) [0|255] "" ECU
 SG_ DBG_ReqArg : 16|32@1+ (1,0) [0|4294967295] "" ECU

BO_ 2568552305 Sevcon_1_HS1: 8 SEVCON_L
 SG_ Sevcon_1_OutputTorque : 0|16@1- (0.0625,0) [-2048|2047.9375] "Nm" ECU,C125
 SG_ Sevcon_1_Speed : 16|16@1- (1,0) [-32768|32767] "RPM" ECU,C125
 SG_ Sevcon_1_BatteryCurrent : 32|16@1- (1,0) [-32768|32767] "A" ECU,C125

BO_ 2568552306 Sevcon_2_HS1: 8 SEVCON_R
 SG_ Sevcon_2_OutputTorque : 0|16@1- (0.0625,0) [-2048|2047.9375] "Nm" ECU,C125
 SG_ Sevcon_2_Speed : 16|16@1- (1,0) [-32768|32767] "RPM" ECU,C125
 SG_ Sevcon_2_BatteryCurrent : 32|16@1- (1,0) [-32768|32767] "A" ECU,C125

BO_ 2568617841 Sevcon_1_HS2: 8 SEVCON_L
 SG_ Sevcon_1_AvailFwdTorque : 0|16@1- (0.0625,0) [-2048|2047.9375] "Nm" ECU,C125
 SG_ Sevcon_1_AvailRevTorque : 16|16@1- (0.0625,0) [-2048|2047.9375] "Nm" ECU,C125
 SG_ Sevcon_1_StatusWord : 32|16@1+ (1,0) [0|65535] "" ECU,C125

BO_ 2568617842 Sevcon_2_HS2: 8 SEVCON_R
 SG_ Sevcon_2_AvailFwdTorque : 0|16@1- (0.0625,0) [-2048|2047.9375] "Nm" ECU,C125
 SG_ Sevcon_2_AvailRevTorque : 16|16@1- (0.0625,0) [-2048|2047.9375] "Nm" ECU,C125
 SG_ Sevcon_2_StatusWord : 32|16@1+ (1,0) [0|65535] "" ECU,C125

BO_ 2568683377 Sevcon_1_HS3: 8 SEVCON_L
 SG_ Sevcon_1_HeatSinkTemp : 0|16@1- (1,0) [-32768|32767] "degC" ECU,C125
 SG_ Sevcon_1_RemainingTemp : 16|16@1- (1,0) [-32768|32767] "degC" ECU,C125
 SG_ Sevcon_1_CapVoltage : 32|16@1- (0.0625,0) [-2048|2047.9375] "V" ECU,C125

BO_ 2568683378 Sevcon_2_HS3: 8 SEVCON_R
 SG_ Sevcon_2_HeatSinkTemp : 0|16@1- (1,0) [-32768|32767] "degC" ECU,C125
 SG_ Sevcon_2_RemainingTemp : 16|16@1- (1,0) [-32768|32767] "degC" ECU,C125
 SG_ Sevcon_2_CapVoltage : 32|16@1- (0.0625,0) [-2048|2047.9375] "V" ECU,C125

BO_ 2568748913 Sevcon_1_HS4: 8 SEVCON_L
 SG_ Sevcon_1_FaultCode : 0|16@1+ (1,0) [0|65535] "" LOGGER
 SG_ Sevcon_1_DebugBytes : 16|32@1+ (1,0) [0|4294967295] "" LOGGER

BO_ 2568748914 Sevcon_2_HS4: 8 SEVCON_R
 SG_ Sevcon_2_FaultCode : 0|16@1+ (1,0) [0|65535] "" LOGGER
 SG_ Sevcon_2_DebugBytes : 16|32@1+ (1,0) [0|4294967295] "" LOGGER

BO_ 2568814449 Sevcon_1_HS5: 8 SEVCON_L
 SG_ Sevcon_1_EncoderAngle : 0|32@1- (0.00001525,0) [-32749.125632|32749.12561675] "" LOGGER

BO_ 2568814450 Sevcon_2_HS5: 8 SEVCON_R
 SG_ Sevcon_2_EncoderAngle : 0|32@1+ (0.00001525,0) [0|65498.25124875] "" LOGGER

BO_ 2569600881 Sevcon_1_HD1: 8 SEVCON_L
 SG_ Sevcon_1_IdActual : 0|16@1- (0.0625,0) [-2048|2047.9375] "A" LOGGER
 SG_ Sevcon_1_IqActual : 16|16@1- (0.0625,0) [-2048|2047.9375] "A" LOGGER
 SG_ Sevcon_1_IdRef : 32|16@1- (0.0625,0) [-2048|2047.9375] "A" LOGGER
 SG_ Sevcon_1_IqRef : 48|16@1- (0.0625,0) [-2048|2047.9375] "A" LOGGER

BO_ 2569600882 Sevcon_2_HD1: 8 SEVCON_R
 SG_ Sevcon_2_IdActual : 0|16@1- (0.0625,0) [-2048|2047.9375] "A" LOGGER
 SG_ Sevcon_2_IqActual : 16|16@1- (0.0625,0) [-2048|2047.9375] "A" LOGGER
 SG_ Sevcon_2_IdRef : 32|16@1- (0.0625,0) [-2048|2047.9375] "A" LOGGER
 SG_ Sevcon_2_IqRef : 48|16@1- (0.0625,0) [-2048|2047.9375] "A" LOGGER

BO_ 2569666417 Sevcon_1_HD2: 8 SEVCON_L
 SG_ Sevcon_1_Ud : 0|16@1- (0.0625,0) [-2048|2047.9375] "V" LOGGER
 SG_ Sevcon_1_Uq : 16|16@1- (0.0625,0) [-2048|2047.9375] "V" LOGGER
 SG_ Sevcon_1_ModIndex : 32|16@1+ (0.0030517578,0) [0|199.9969482422] "%" LOGGER
 SG_ Sevcon_1_TargetTorque : 48|16@1- (0.0625,0) [-2048|2047.9375] "Nm" LOGGER

BO_ 2569666418 Sevcon_2_HD2: 8 SEVCON_R
 SG_ Sevcon_2_Ud : 0|16@1- (0.0625,0) [-2048|2047.9375] "V" LOGGER
 SG_ Sevcon_2_Uq : 16|16@1- (0.0625,0) [-2048|2047.9375] "V" LOGGER
 SG_ Sevcon_2_ModIndex : 32|16@1+ (0.0030517578,0) [0|199.9969482422] "%" LOGGER
 SG_ Sevcon_2_TargetTorque : 48|16@1- (0.0625,0) [-2048|2047.9375] "Nm" LOGGER

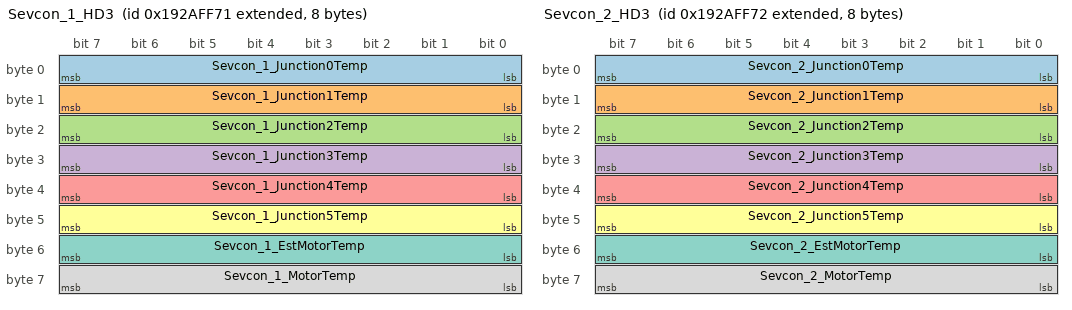
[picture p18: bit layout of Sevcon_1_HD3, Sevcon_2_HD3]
BO_ 2569731953 Sevcon_1_HD3: 8 SEVCON_L
 SG_ Sevcon_1_Junction0Temp : 0|8@1+ (1,0) [0|255] "degC" LOGGER
 SG_ Sevcon_1_Junction1Temp : 8|8@1+ (1,0) [0|255] "degC" LOGGER
 SG_ Sevcon_1_Junction2Temp : 16|8@1+ (1,0) [0|255] "degC" LOGGER
 SG_ Sevcon_1_Junction3Temp : 24|8@1+ (1,0) [0|255] "degC" LOGGER
 SG_ Sevcon_1_Junction4Temp : 32|8@1+ (1,0) [0|255] "degC" LOGGER
 SG_ Sevcon_1_Junction5Temp : 40|8@1+ (1,0) [0|255] "degC" LOGGER
 SG_ Sevcon_1_EstMotorTemp : 48|8@1+ (1,0) [0|255] "degC" LOGGER
 SG_ Sevcon_1_MotorTemp : 56|8@1+ (1,0) [0|255] "degC" LOGGER

BO_ 2569731954 Sevcon_2_HD3: 8 SEVCON_R
 SG_ Sevcon_2_Junction0Temp : 0|8@1+ (1,0) [0|255] "degC" LOGGER
 SG_ Sevcon_2_Junction1Temp : 8|8@1+ (1,0) [0|255] "degC" LOGGER
 SG_ Sevcon_2_Junction2Temp : 16|8@1+ (1,0) [0|255] "degC" LOGGER
 SG_ Sevcon_2_Junction3Temp : 24|8@1+ (1,0) [0|255] "degC" LOGGER
 SG_ Sevcon_2_Junction4Temp : 32|8@1+ (1,0) [0|255] "degC" LOGGER
 SG_ Sevcon_2_Junction5Temp : 40|8@1+ (1,0) [0|255] "degC" LOGGER
 SG_ Sevcon_2_EstMotorTemp : 48|8@1+ (1,0) [0|255] "degC" LOGGER
 SG_ Sevcon_2_MotorTemp : 56|8@1+ (1,0) [0|255] "degC" LOGGER

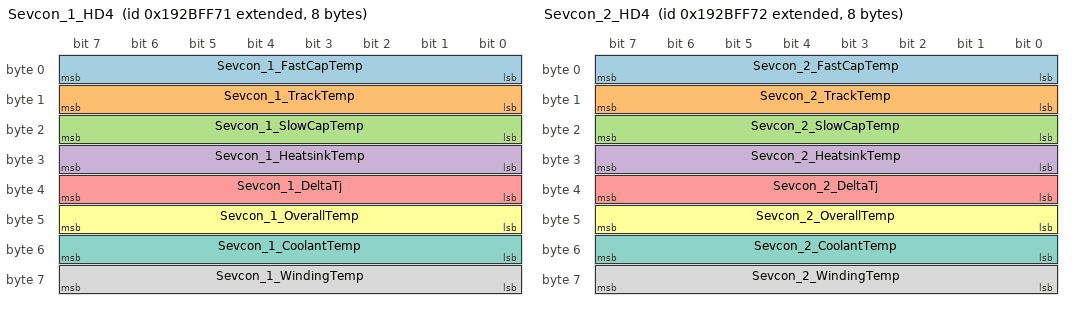
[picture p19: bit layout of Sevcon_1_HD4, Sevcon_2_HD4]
BO_ 2569797489 Sevcon_1_HD4: 8 SEVCON_L
 SG_ Sevcon_1_FastCapTemp : 0|8@1+ (1,0) [0|255] "" LOGGER
 SG_ Sevcon_1_TrackTemp : 8|8@1+ (1,0) [0|255] "degC" LOGGER
 SG_ Sevcon_1_SlowCapTemp : 16|8@1+ (1,0) [0|255] "degC" LOGGER
 SG_ Sevcon_1_HeatsinkTemp : 24|8@1+ (1,0) [0|255] "degC" LOGGER
 SG_ Sevcon_1_DeltaTj : 32|8@1+ (1,0) [0|255] "degC" LOGGER
 SG_ Sevcon_1_OverallTemp : 40|8@1+ (1,0) [0|255] "degC" LOGGER
 SG_ Sevcon_1_CoolantTemp : 48|8@1+ (1,0) [0|255] "degC" LOGGER
 SG_ Sevcon_1_WindingTemp : 56|8@1+ (1,0) [0|255] "degC" LOGGER

BO_ 2569797490 Sevcon_2_HD4: 8 SEVCON_R
 SG_ Sevcon_2_FastCapTemp : 0|8@1+ (1,0) [0|255] "" LOGGER
 SG_ Sevcon_2_TrackTemp : 8|8@1+ (1,0) [0|255] "degC" LOGGER
 SG_ Sevcon_2_SlowCapTemp : 16|8@1+ (1,0) [0|255] "degC" LOGGER
 SG_ Sevcon_2_HeatsinkTemp : 24|8@1+ (1,0) [0|255] "degC" LOGGER
 SG_ Sevcon_2_DeltaTj : 32|8@1+ (1,0) [0|255] "degC" LOGGER
 SG_ Sevcon_2_OverallTemp : 40|8@1+ (1,0) [0|255] "degC" LOGGER
 SG_ Sevcon_2_CoolantTemp : 48|8@1+ (1,0) [0|255] "degC" LOGGER
 SG_ Sevcon_2_WindingTemp : 56|8@1+ (1,0) [0|255] "degC" LOGGER

BO_ 2569863025 Sevcon_1_HD5: 8 SEVCON_L
 SG_ Sevcon_1_MaxFlux : 0|16@1- (1,0) [-32768|32767] "A" LOGGER
 SG_ Sevcon_1_IvLim : 16|16@1- (1,0) [-32768|32767] "A" LOGGER
 SG_ Sevcon_1_IqMax : 32|16@1- (1,0) [-32768|32767] "A" LOGGER
 SG_ Sevcon_1_Ls : 48|16@1+ (0.059604645,0) [0|3906.1904087643] "uH" LOGGER

BO_ 2569863026 Sevcon_2_HD5: 8 SEVCON_R
 SG_ Sevcon_2_MaxFlux : 0|16@1- (1,0) [-32768|32767] "A" LOGGER
 SG_ Sevcon_2_IvLim : 16|16@1- (1,0) [-32768|32767] "A" LOGGER
 SG_ Sevcon_2_IqMax : 32|16@1- (1,0) [-32768|32767] "A" LOGGER
 SG_ Sevcon_2_Ls : 48|16@1+ (0.059604645,0) [0|3906.1904087643] "uH" LOGGER

CM_ BO_ 2286157824 "Miss this for 1 s and the BMU drops HV";
CM_ SG_ 2286157824 ECU_F_PrechargeReq "The comp25 BMU doesn't look at this, it only reads 0x1080C001";
CM_ SG_ 2286157824 ECU_F_HvOffReq "Spare, always 0 till the rules side is sorted";
CM_ SG_ 2286157824 ECU_Uptime "Goes back to 0 on a reset so you can spot it in the log";
CM_ SG_ 2290122752 SHDN_OldLines "Always 0, the old firmware's union is really a struct";
CM_ BO_ 2298740736 "Only LoopClosed decides anything, the segment bits are for humans";
CM_ BO_ 2307129344 "Only on the bus when charging";
CM_ SG_ 2418327552 BMU_F_HbEcu "BMU can't hear our heartbeat";
CM_ SG_ 2418327552 BMU_F_PrechargeTimeout "comp25 sets this on any trip with the contactors shut, not just a slow precharge";
CM_ SG_ 2418327552 BMU_PackState "comp25 never fills this";
CM_ SG_ 2418327552 BMU_SOC "comp25 never fills this";
CM_ SG_ 2424356865 ECU_C25_State "40 is what makes the comp25 BMU precharge";
CM_ SG_ 2424357104 DBG_ReqArg "Float bits for PARAM_SET, OUTPUT_DUTY and the CAL_ ones";
CM_ BO_ 2554855424 "Anything that touches outputs, cal or params is refused while DRIVING. Reply goes back on whichever bus asked";
CM_ BO_ 2555117568 "Anything that touches outputs, cal or params is refused while DRIVING. Reply goes back on whichever bus asked";
CM_ SG_ 2555117568 DBG_ReqArg "Float bits for PARAM_SET, OUTPUT_DUTY and the CAL_ ones";
BA_DEF_ BO_  "GenMsgCycleTime" INT 0 65535;
BA_DEF_ BO_  "SendType" STRING;
BA_DEF_ BO_  "RxTimeoutMs" INT 0 65535;
BA_DEF_ BO_  "MoTeC" STRING;
BA_DEF_ SG_  "MoTeCLog" STRING;
BA_DEF_ SG_  "MoTeCGroup" STRING;
BA_DEF_ BO_  "Status" STRING;
BA_DEF_ BO_  "Variant" STRING;
BA_DEF_ BO_  "VFrameFormat" ENUM "StandardCAN","ExtendedCAN";
BA_DEF_DEF_  "GenMsgCycleTime" 0;
BA_DEF_DEF_  "SendType" "Cyclic";
BA_DEF_DEF_  "RxTimeoutMs" 0;
BA_DEF_DEF_  "MoTeC" "No";
BA_DEF_DEF_  "MoTeCLog" "";
BA_DEF_DEF_  "MoTeCGroup" "";
BA_DEF_DEF_  "Status" "Current";
BA_DEF_DEF_  "Variant" "";
BA_DEF_DEF_  "VFrameFormat" "StandardCAN";
BA_ "GenMsgCycleTime" BO_ 2284095744 3300;
BA_ "SendType" BO_ 2284095744 "Burst";
BA_ "Variant" BO_ 2284095744 "bmu_comp25";
BA_ "VFrameFormat" BO_ 2284095744 1;
BA_ "GenMsgCycleTime" BO_ 2284095760 3300;
BA_ "SendType" BO_ 2284095760 "Burst";
BA_ "Variant" BO_ 2284095760 "bmu_comp25";
BA_ "VFrameFormat" BO_ 2284095760 1;
BA_ "GenMsgCycleTime" BO_ 2284095776 3300;
BA_ "SendType" BO_ 2284095776 "Burst";
BA_ "Variant" BO_ 2284095776 "bmu_comp25";
BA_ "VFrameFormat" BO_ 2284095776 1;
BA_ "GenMsgCycleTime" BO_ 2284095792 3300;
BA_ "SendType" BO_ 2284095792 "Burst";
BA_ "Variant" BO_ 2284095792 "bmu_comp25";
BA_ "VFrameFormat" BO_ 2284095792 1;
BA_ "GenMsgCycleTime" BO_ 2284095808 3300;
BA_ "SendType" BO_ 2284095808 "Burst";
BA_ "Variant" BO_ 2284095808 "bmu_comp25";
BA_ "VFrameFormat" BO_ 2284095808 1;
BA_ "GenMsgCycleTime" BO_ 2284095824 3300;
BA_ "SendType" BO_ 2284095824 "Burst";
BA_ "Variant" BO_ 2284095824 "bmu_comp25";
BA_ "VFrameFormat" BO_ 2284095824 1;
BA_ "GenMsgCycleTime" BO_ 2284095840 3300;
BA_ "SendType" BO_ 2284095840 "Burst";
BA_ "Variant" BO_ 2284095840 "bmu_comp25";
BA_ "VFrameFormat" BO_ 2284095840 1;
BA_ "GenMsgCycleTime" BO_ 2284095856 3300;
BA_ "SendType" BO_ 2284095856 "Burst";
BA_ "Variant" BO_ 2284095856 "bmu_comp25";
BA_ "VFrameFormat" BO_ 2284095856 1;
BA_ "GenMsgCycleTime" BO_ 2284096768 100;
BA_ "RxTimeoutMs" BO_ 2284096768 500;
BA_ "MoTeC" BO_ 2284096768 "Yes";
BA_ "Variant" BO_ 2284096768 "bmu_comp25";
BA_ "VFrameFormat" BO_ 2284096768 1;
BA_ "GenMsgCycleTime" BO_ 2284096784 3300;
BA_ "SendType" BO_ 2284096784 "Burst";
BA_ "RxTimeoutMs" BO_ 2284096784 7000;
BA_ "MoTeC" BO_ 2284096784 "Yes";
BA_ "Variant" BO_ 2284096784 "bmu_comp25";
BA_ "VFrameFormat" BO_ 2284096784 1;
BA_ "GenMsgCycleTime" BO_ 2284096800 1020;
BA_ "RxTimeoutMs" BO_ 2284096800 3000;
BA_ "MoTeC" BO_ 2284096800 "Yes";
BA_ "Variant" BO_ 2284096800 "bmu_comp25";
BA_ "VFrameFormat" BO_ 2284096800 1;
BA_ "MoTeCGroup" SG_ 2284096800 BMU_SocValid "BMU_SocFlags";
BA_ "MoTeCGroup" SG_ 2284096800 BMU_SocCalibrated "BMU_SocFlags";
BA_ "GenMsgCycleTime" BO_ 2284097024 100;
BA_ "Variant" BO_ 2284097024 "bmu_comp25";
BA_ "VFrameFormat" BO_ 2284097024 1;
BA_ "GenMsgCycleTime" BO_ 2286157824 100;
BA_ "RxTimeoutMs" BO_ 2286157824 1000;
BA_ "MoTeC" BO_ 2286157824 "Yes";
BA_ "Status" BO_ 2286157824 "Planned";
BA_ "VFrameFormat" BO_ 2286157824 1;
BA_ "MoTeCGroup" SG_ 2286157824 ECU_F_PedalPolarity "ECU_Flags";
BA_ "MoTeCGroup" SG_ 2286157824 ECU_F_BmuAlive "ECU_Flags";
BA_ "MoTeCGroup" SG_ 2286157824 ECU_F_InvAlive "ECU_Flags";
BA_ "MoTeCGroup" SG_ 2286157824 ECU_F_ShdnClosed "ECU_Flags";
BA_ "MoTeCGroup" SG_ 2286157824 ECU_F_PedalOk "ECU_Flags";
BA_ "MoTeCGroup" SG_ 2286157824 ECU_F_BrakePressed "ECU_Flags";
BA_ "MoTeCGroup" SG_ 2286157824 ECU_F_PrechargeReq "ECU_Flags";
BA_ "MoTeCGroup" SG_ 2286157824 ECU_F_TorqueAllowed "ECU_Flags";
BA_ "MoTeCGroup" SG_ 2286157824 ECU_F_OutputFault "ECU_Flags";
BA_ "MoTeCGroup" SG_ 2286157824 ECU_F_CanAOk "ECU_Flags";
BA_ "MoTeCGroup" SG_ 2286157824 ECU_F_CanBOk "ECU_Flags";
BA_ "MoTeCGroup" SG_ 2286157824 ECU_F_Warning "ECU_Flags";
BA_ "MoTeCGroup" SG_ 2286157824 ECU_F_EepromOk "ECU_Flags";
BA_ "MoTeCGroup" SG_ 2286157824 ECU_F_Calibrated "ECU_Flags";
BA_ "MoTeCGroup" SG_ 2286157824 ECU_F_HvOffReq "ECU_Flags";
BA_ "GenMsgCycleTime" BO_ 2290122752 100;
BA_ "Status" BO_ 2290122752 "Legacy";
BA_ "VFrameFormat" BO_ 2290122752 1;
BA_ "GenMsgCycleTime" BO_ 2290122784 20;
BA_ "Status" BO_ 2290122784 "Legacy";
BA_ "VFrameFormat" BO_ 2290122784 1;
BA_ "GenMsgCycleTime" BO_ 2290122800 20;
BA_ "Status" BO_ 2290122800 "Legacy";
BA_ "VFrameFormat" BO_ 2290122800 1;
BA_ "GenMsgCycleTime" BO_ 2298740736 100;
BA_ "RxTimeoutMs" BO_ 2298740736 500;
BA_ "MoTeC" BO_ 2298740736 "Yes";
BA_ "Status" BO_ 2298740736 "Planned";
BA_ "VFrameFormat" BO_ 2298740736 1;
BA_ "MoTeCGroup" SG_ 2298740736 SHDN_Seg1Open "SHDN_OpenSegs";
BA_ "MoTeCGroup" SG_ 2298740736 SHDN_Seg2Open "SHDN_OpenSegs";
BA_ "MoTeCGroup" SG_ 2298740736 SHDN_Seg3Open "SHDN_OpenSegs";
BA_ "MoTeCGroup" SG_ 2298740736 SHDN_Seg4Open "SHDN_OpenSegs";
BA_ "MoTeCGroup" SG_ 2298740736 SHDN_Seg5Open "SHDN_OpenSegs";
BA_ "MoTeCGroup" SG_ 2298740736 SHDN_Seg6Open "SHDN_OpenSegs";
BA_ "MoTeCGroup" SG_ 2298740736 SHDN_Seg7Open "SHDN_OpenSegs";
BA_ "MoTeCGroup" SG_ 2298740736 SHDN_Seg8Open "SHDN_OpenSegs";
BA_ "MoTeCGroup" SG_ 2298740736 SHDN_Seg9Open "SHDN_OpenSegs";
BA_ "MoTeCGroup" SG_ 2298740736 SHDN_Seg10Open "SHDN_OpenSegs";
BA_ "GenMsgCycleTime" BO_ 2307129344 100;
BA_ "RxTimeoutMs" BO_ 2307129344 1000;
BA_ "Status" BO_ 2307129344 "Planned";
BA_ "VFrameFormat" BO_ 2307129344 1;
BA_ "SendType" BO_ 2316304896 "Event";
BA_ "Variant" BO_ 2316304896 "bmu_comp25";
BA_ "VFrameFormat" BO_ 2316304896 1;
BA_ "GenMsgCycleTime" BO_ 2416443392 3300;
BA_ "SendType" BO_ 2416443392 "Burst";
BA_ "Status" BO_ 2416443392 "Planned";
BA_ "Variant" BO_ 2416443392 "bmu_qev6";
BA_ "VFrameFormat" BO_ 2416443392 1;
BA_ "GenMsgCycleTime" BO_ 2416443393 3300;
BA_ "SendType" BO_ 2416443393 "Burst";
BA_ "Status" BO_ 2416443393 "Planned";
BA_ "Variant" BO_ 2416443393 "bmu_qev6";
BA_ "VFrameFormat" BO_ 2416443393 1;
BA_ "GenMsgCycleTime" BO_ 2416443394 3300;
BA_ "SendType" BO_ 2416443394 "Burst";
BA_ "Status" BO_ 2416443394 "Planned";
BA_ "Variant" BO_ 2416443394 "bmu_qev6";
BA_ "VFrameFormat" BO_ 2416443394 1;
BA_ "GenMsgCycleTime" BO_ 2416443395 3300;
BA_ "SendType" BO_ 2416443395 "Burst";
BA_ "Status" BO_ 2416443395 "Planned";
BA_ "Variant" BO_ 2416443395 "bmu_qev6";
BA_ "VFrameFormat" BO_ 2416443395 1;
BA_ "GenMsgCycleTime" BO_ 2416443408 3300;
BA_ "SendType" BO_ 2416443408 "Burst";
BA_ "Status" BO_ 2416443408 "Planned";
BA_ "Variant" BO_ 2416443408 "bmu_qev6";
BA_ "VFrameFormat" BO_ 2416443408 1;
BA_ "GenMsgCycleTime" BO_ 2416443409 3300;
BA_ "SendType" BO_ 2416443409 "Burst";
BA_ "Status" BO_ 2416443409 "Planned";
BA_ "Variant" BO_ 2416443409 "bmu_qev6";
BA_ "VFrameFormat" BO_ 2416443409 1;
BA_ "GenMsgCycleTime" BO_ 2416443410 3300;
BA_ "SendType" BO_ 2416443410 "Burst";
BA_ "Status" BO_ 2416443410 "Planned";
BA_ "Variant" BO_ 2416443410 "bmu_qev6";
BA_ "VFrameFormat" BO_ 2416443410 1;
BA_ "GenMsgCycleTime" BO_ 2416443411 3300;
BA_ "SendType" BO_ 2416443411 "Burst";
BA_ "Status" BO_ 2416443411 "Planned";
BA_ "Variant" BO_ 2416443411 "bmu_qev6";
BA_ "VFrameFormat" BO_ 2416443411 1;
BA_ "GenMsgCycleTime" BO_ 2416443424 3300;
BA_ "SendType" BO_ 2416443424 "Burst";
BA_ "Status" BO_ 2416443424 "Planned";
BA_ "Variant" BO_ 2416443424 "bmu_qev6";
BA_ "VFrameFormat" BO_ 2416443424 1;
BA_ "GenMsgCycleTime" BO_ 2416443425 3300;
BA_ "SendType" BO_ 2416443425 "Burst";
BA_ "Status" BO_ 2416443425 "Planned";
BA_ "Variant" BO_ 2416443425 "bmu_qev6";
BA_ "VFrameFormat" BO_ 2416443425 1;
BA_ "GenMsgCycleTime" BO_ 2416443426 3300;
BA_ "SendType" BO_ 2416443426 "Burst";
BA_ "Status" BO_ 2416443426 "Planned";
BA_ "Variant" BO_ 2416443426 "bmu_qev6";
BA_ "VFrameFormat" BO_ 2416443426 1;
BA_ "GenMsgCycleTime" BO_ 2416443427 3300;
BA_ "SendType" BO_ 2416443427 "Burst";
BA_ "Status" BO_ 2416443427 "Planned";
BA_ "Variant" BO_ 2416443427 "bmu_qev6";
BA_ "VFrameFormat" BO_ 2416443427 1;
BA_ "GenMsgCycleTime" BO_ 2416443440 3300;
BA_ "SendType" BO_ 2416443440 "Burst";
BA_ "Status" BO_ 2416443440 "Planned";
BA_ "Variant" BO_ 2416443440 "bmu_qev6";
BA_ "VFrameFormat" BO_ 2416443440 1;
BA_ "GenMsgCycleTime" BO_ 2416443441 3300;
BA_ "SendType" BO_ 2416443441 "Burst";
BA_ "Status" BO_ 2416443441 "Planned";
BA_ "Variant" BO_ 2416443441 "bmu_qev6";
BA_ "VFrameFormat" BO_ 2416443441 1;
BA_ "GenMsgCycleTime" BO_ 2416443442 3300;
BA_ "SendType" BO_ 2416443442 "Burst";
BA_ "Status" BO_ 2416443442 "Planned";
BA_ "Variant" BO_ 2416443442 "bmu_qev6";
BA_ "VFrameFormat" BO_ 2416443442 1;
BA_ "GenMsgCycleTime" BO_ 2416443443 3300;
BA_ "SendType" BO_ 2416443443 "Burst";
BA_ "Status" BO_ 2416443443 "Planned";
BA_ "Variant" BO_ 2416443443 "bmu_qev6";
BA_ "VFrameFormat" BO_ 2416443443 1;
BA_ "GenMsgCycleTime" BO_ 2416443456 3300;
BA_ "SendType" BO_ 2416443456 "Burst";
BA_ "Status" BO_ 2416443456 "Planned";
BA_ "Variant" BO_ 2416443456 "bmu_qev6";
BA_ "VFrameFormat" BO_ 2416443456 1;
BA_ "GenMsgCycleTime" BO_ 2416443457 3300;
BA_ "SendType" BO_ 2416443457 "Burst";
BA_ "Status" BO_ 2416443457 "Planned";
BA_ "Variant" BO_ 2416443457 "bmu_qev6";
BA_ "VFrameFormat" BO_ 2416443457 1;
BA_ "GenMsgCycleTime" BO_ 2416443458 3300;
BA_ "SendType" BO_ 2416443458 "Burst";
BA_ "Status" BO_ 2416443458 "Planned";
BA_ "Variant" BO_ 2416443458 "bmu_qev6";
BA_ "VFrameFormat" BO_ 2416443458 1;
BA_ "GenMsgCycleTime" BO_ 2416443459 3300;
BA_ "SendType" BO_ 2416443459 "Burst";
BA_ "Status" BO_ 2416443459 "Planned";
BA_ "Variant" BO_ 2416443459 "bmu_qev6";
BA_ "VFrameFormat" BO_ 2416443459 1;
BA_ "GenMsgCycleTime" BO_ 2416443472 3300;
BA_ "SendType" BO_ 2416443472 "Burst";
BA_ "Status" BO_ 2416443472 "Planned";
BA_ "Variant" BO_ 2416443472 "bmu_qev6";
BA_ "VFrameFormat" BO_ 2416443472 1;
BA_ "GenMsgCycleTime" BO_ 2416443473 3300;
BA_ "SendType" BO_ 2416443473 "Burst";
BA_ "Status" BO_ 2416443473 "Planned";
BA_ "Variant" BO_ 2416443473 "bmu_qev6";
BA_ "VFrameFormat" BO_ 2416443473 1;
BA_ "GenMsgCycleTime" BO_ 2416443474 3300;
BA_ "SendType" BO_ 2416443474 "Burst";
BA_ "Status" BO_ 2416443474 "Planned";
BA_ "Variant" BO_ 2416443474 "bmu_qev6";
BA_ "VFrameFormat" BO_ 2416443474 1;
BA_ "GenMsgCycleTime" BO_ 2416443475 3300;
BA_ "SendType" BO_ 2416443475 "Burst";
BA_ "Status" BO_ 2416443475 "Planned";
BA_ "Variant" BO_ 2416443475 "bmu_qev6";
BA_ "VFrameFormat" BO_ 2416443475 1;
BA_ "GenMsgCycleTime" BO_ 2416443488 3300;
BA_ "SendType" BO_ 2416443488 "Burst";
BA_ "Status" BO_ 2416443488 "Planned";
BA_ "Variant" BO_ 2416443488 "bmu_qev6";
BA_ "VFrameFormat" BO_ 2416443488 1;
BA_ "GenMsgCycleTime" BO_ 2416443489 3300;
BA_ "SendType" BO_ 2416443489 "Burst";
BA_ "Status" BO_ 2416443489 "Planned";
BA_ "Variant" BO_ 2416443489 "bmu_qev6";
BA_ "VFrameFormat" BO_ 2416443489 1;
BA_ "GenMsgCycleTime" BO_ 2416443490 3300;
BA_ "SendType" BO_ 2416443490 "Burst";
BA_ "Status" BO_ 2416443490 "Planned";
BA_ "Variant" BO_ 2416443490 "bmu_qev6";
BA_ "VFrameFormat" BO_ 2416443490 1;
BA_ "GenMsgCycleTime" BO_ 2416443491 3300;
BA_ "SendType" BO_ 2416443491 "Burst";
BA_ "Status" BO_ 2416443491 "Planned";
BA_ "Variant" BO_ 2416443491 "bmu_qev6";
BA_ "VFrameFormat" BO_ 2416443491 1;
BA_ "GenMsgCycleTime" BO_ 2416443504 3300;
BA_ "SendType" BO_ 2416443504 "Burst";
BA_ "Status" BO_ 2416443504 "Planned";
BA_ "Variant" BO_ 2416443504 "bmu_qev6";
BA_ "VFrameFormat" BO_ 2416443504 1;
BA_ "GenMsgCycleTime" BO_ 2416443505 3300;
BA_ "SendType" BO_ 2416443505 "Burst";
BA_ "Status" BO_ 2416443505 "Planned";
BA_ "Variant" BO_ 2416443505 "bmu_qev6";
BA_ "VFrameFormat" BO_ 2416443505 1;
BA_ "GenMsgCycleTime" BO_ 2416443506 3300;
BA_ "SendType" BO_ 2416443506 "Burst";
BA_ "Status" BO_ 2416443506 "Planned";
BA_ "Variant" BO_ 2416443506 "bmu_qev6";
BA_ "VFrameFormat" BO_ 2416443506 1;
BA_ "GenMsgCycleTime" BO_ 2416443507 3300;
BA_ "SendType" BO_ 2416443507 "Burst";
BA_ "Status" BO_ 2416443507 "Planned";
BA_ "Variant" BO_ 2416443507 "bmu_qev6";
BA_ "VFrameFormat" BO_ 2416443507 1;
BA_ "GenMsgCycleTime" BO_ 2416443520 3300;
BA_ "SendType" BO_ 2416443520 "Burst";
BA_ "Status" BO_ 2416443520 "Planned";
BA_ "Variant" BO_ 2416443520 "bmu_qev6";
BA_ "VFrameFormat" BO_ 2416443520 1;
BA_ "GenMsgCycleTime" BO_ 2416443521 3300;
BA_ "SendType" BO_ 2416443521 "Burst";
BA_ "Status" BO_ 2416443521 "Planned";
BA_ "Variant" BO_ 2416443521 "bmu_qev6";
BA_ "VFrameFormat" BO_ 2416443521 1;
BA_ "GenMsgCycleTime" BO_ 2416443522 3300;
BA_ "SendType" BO_ 2416443522 "Burst";
BA_ "Status" BO_ 2416443522 "Planned";
BA_ "Variant" BO_ 2416443522 "bmu_qev6";
BA_ "VFrameFormat" BO_ 2416443522 1;
BA_ "GenMsgCycleTime" BO_ 2416443523 3300;
BA_ "SendType" BO_ 2416443523 "Burst";
BA_ "Status" BO_ 2416443523 "Planned";
BA_ "Variant" BO_ 2416443523 "bmu_qev6";
BA_ "VFrameFormat" BO_ 2416443523 1;
BA_ "GenMsgCycleTime" BO_ 2416443536 3300;
BA_ "SendType" BO_ 2416443536 "Burst";
BA_ "Status" BO_ 2416443536 "Planned";
BA_ "Variant" BO_ 2416443536 "bmu_qev6";
BA_ "VFrameFormat" BO_ 2416443536 1;
BA_ "GenMsgCycleTime" BO_ 2416443537 3300;
BA_ "SendType" BO_ 2416443537 "Burst";
BA_ "Status" BO_ 2416443537 "Planned";
BA_ "Variant" BO_ 2416443537 "bmu_qev6";
BA_ "VFrameFormat" BO_ 2416443537 1;
BA_ "GenMsgCycleTime" BO_ 2416443538 3300;
BA_ "SendType" BO_ 2416443538 "Burst";
BA_ "Status" BO_ 2416443538 "Planned";
BA_ "Variant" BO_ 2416443538 "bmu_qev6";
BA_ "VFrameFormat" BO_ 2416443538 1;
BA_ "GenMsgCycleTime" BO_ 2416443539 3300;
BA_ "SendType" BO_ 2416443539 "Burst";
BA_ "Status" BO_ 2416443539 "Planned";
BA_ "Variant" BO_ 2416443539 "bmu_qev6";
BA_ "VFrameFormat" BO_ 2416443539 1;
BA_ "GenMsgCycleTime" BO_ 2416443552 3300;
BA_ "SendType" BO_ 2416443552 "Burst";
BA_ "Status" BO_ 2416443552 "Planned";
BA_ "Variant" BO_ 2416443552 "bmu_qev6";
BA_ "VFrameFormat" BO_ 2416443552 1;
BA_ "GenMsgCycleTime" BO_ 2416443553 3300;
BA_ "SendType" BO_ 2416443553 "Burst";
BA_ "Status" BO_ 2416443553 "Planned";
BA_ "Variant" BO_ 2416443553 "bmu_qev6";
BA_ "VFrameFormat" BO_ 2416443553 1;
BA_ "GenMsgCycleTime" BO_ 2416443554 3300;
BA_ "SendType" BO_ 2416443554 "Burst";
BA_ "Status" BO_ 2416443554 "Planned";
BA_ "Variant" BO_ 2416443554 "bmu_qev6";
BA_ "VFrameFormat" BO_ 2416443554 1;
BA_ "GenMsgCycleTime" BO_ 2416443555 3300;
BA_ "SendType" BO_ 2416443555 "Burst";
BA_ "Status" BO_ 2416443555 "Planned";
BA_ "Variant" BO_ 2416443555 "bmu_qev6";
BA_ "VFrameFormat" BO_ 2416443555 1;
BA_ "GenMsgCycleTime" BO_ 2416443568 3300;
BA_ "SendType" BO_ 2416443568 "Burst";
BA_ "Status" BO_ 2416443568 "Planned";
BA_ "Variant" BO_ 2416443568 "bmu_qev6";
BA_ "VFrameFormat" BO_ 2416443568 1;
BA_ "GenMsgCycleTime" BO_ 2416443569 3300;
BA_ "SendType" BO_ 2416443569 "Burst";
BA_ "Status" BO_ 2416443569 "Planned";
BA_ "Variant" BO_ 2416443569 "bmu_qev6";
BA_ "VFrameFormat" BO_ 2416443569 1;
BA_ "GenMsgCycleTime" BO_ 2416443570 3300;
BA_ "SendType" BO_ 2416443570 "Burst";
BA_ "Status" BO_ 2416443570 "Planned";
BA_ "Variant" BO_ 2416443570 "bmu_qev6";
BA_ "VFrameFormat" BO_ 2416443570 1;
BA_ "GenMsgCycleTime" BO_ 2416443571 3300;
BA_ "SendType" BO_ 2416443571 "Burst";
BA_ "Status" BO_ 2416443571 "Planned";
BA_ "Variant" BO_ 2416443571 "bmu_qev6";
BA_ "VFrameFormat" BO_ 2416443571 1;
BA_ "GenMsgCycleTime" BO_ 2416443584 3300;
BA_ "SendType" BO_ 2416443584 "Burst";
BA_ "Status" BO_ 2416443584 "Planned";
BA_ "Variant" BO_ 2416443584 "bmu_qev6";
BA_ "VFrameFormat" BO_ 2416443584 1;
BA_ "GenMsgCycleTime" BO_ 2416443585 3300;
BA_ "SendType" BO_ 2416443585 "Burst";
BA_ "Status" BO_ 2416443585 "Planned";
BA_ "Variant" BO_ 2416443585 "bmu_qev6";
BA_ "VFrameFormat" BO_ 2416443585 1;
BA_ "GenMsgCycleTime" BO_ 2416443586 3300;
BA_ "SendType" BO_ 2416443586 "Burst";
BA_ "Status" BO_ 2416443586 "Planned";
BA_ "Variant" BO_ 2416443586 "bmu_qev6";
BA_ "VFrameFormat" BO_ 2416443586 1;
BA_ "GenMsgCycleTime" BO_ 2416443587 3300;
BA_ "SendType" BO_ 2416443587 "Burst";
BA_ "Status" BO_ 2416443587 "Planned";
BA_ "Variant" BO_ 2416443587 "bmu_qev6";
BA_ "VFrameFormat" BO_ 2416443587 1;
BA_ "GenMsgCycleTime" BO_ 2416443600 3300;
BA_ "SendType" BO_ 2416443600 "Burst";
BA_ "Status" BO_ 2416443600 "Planned";
BA_ "Variant" BO_ 2416443600 "bmu_qev6";
BA_ "VFrameFormat" BO_ 2416443600 1;
BA_ "GenMsgCycleTime" BO_ 2416443601 3300;
BA_ "SendType" BO_ 2416443601 "Burst";
BA_ "Status" BO_ 2416443601 "Planned";
BA_ "Variant" BO_ 2416443601 "bmu_qev6";
BA_ "VFrameFormat" BO_ 2416443601 1;
BA_ "GenMsgCycleTime" BO_ 2416443602 3300;
BA_ "SendType" BO_ 2416443602 "Burst";
BA_ "Status" BO_ 2416443602 "Planned";
BA_ "Variant" BO_ 2416443602 "bmu_qev6";
BA_ "VFrameFormat" BO_ 2416443602 1;
BA_ "GenMsgCycleTime" BO_ 2416443603 3300;
BA_ "SendType" BO_ 2416443603 "Burst";
BA_ "Status" BO_ 2416443603 "Planned";
BA_ "Variant" BO_ 2416443603 "bmu_qev6";
BA_ "VFrameFormat" BO_ 2416443603 1;
BA_ "GenMsgCycleTime" BO_ 2416443616 3300;
BA_ "SendType" BO_ 2416443616 "Burst";
BA_ "Status" BO_ 2416443616 "Planned";
BA_ "Variant" BO_ 2416443616 "bmu_qev6";
BA_ "VFrameFormat" BO_ 2416443616 1;
BA_ "GenMsgCycleTime" BO_ 2416443617 3300;
BA_ "SendType" BO_ 2416443617 "Burst";
BA_ "Status" BO_ 2416443617 "Planned";
BA_ "Variant" BO_ 2416443617 "bmu_qev6";
BA_ "VFrameFormat" BO_ 2416443617 1;
BA_ "GenMsgCycleTime" BO_ 2416443618 3300;
BA_ "SendType" BO_ 2416443618 "Burst";
BA_ "Status" BO_ 2416443618 "Planned";
BA_ "Variant" BO_ 2416443618 "bmu_qev6";
BA_ "VFrameFormat" BO_ 2416443618 1;
BA_ "GenMsgCycleTime" BO_ 2416443619 3300;
BA_ "SendType" BO_ 2416443619 "Burst";
BA_ "Status" BO_ 2416443619 "Planned";
BA_ "Variant" BO_ 2416443619 "bmu_qev6";
BA_ "VFrameFormat" BO_ 2416443619 1;
BA_ "GenMsgCycleTime" BO_ 2416443632 3300;
BA_ "SendType" BO_ 2416443632 "Burst";
BA_ "Status" BO_ 2416443632 "Planned";
BA_ "Variant" BO_ 2416443632 "bmu_qev6";
BA_ "VFrameFormat" BO_ 2416443632 1;
BA_ "GenMsgCycleTime" BO_ 2416443633 3300;
BA_ "SendType" BO_ 2416443633 "Burst";
BA_ "Status" BO_ 2416443633 "Planned";
BA_ "Variant" BO_ 2416443633 "bmu_qev6";
BA_ "VFrameFormat" BO_ 2416443633 1;
BA_ "GenMsgCycleTime" BO_ 2416443634 3300;
BA_ "SendType" BO_ 2416443634 "Burst";
BA_ "Status" BO_ 2416443634 "Planned";
BA_ "Variant" BO_ 2416443634 "bmu_qev6";
BA_ "VFrameFormat" BO_ 2416443634 1;
BA_ "GenMsgCycleTime" BO_ 2416443635 3300;
BA_ "SendType" BO_ 2416443635 "Burst";
BA_ "Status" BO_ 2416443635 "Planned";
BA_ "Variant" BO_ 2416443635 "bmu_qev6";
BA_ "VFrameFormat" BO_ 2416443635 1;
BA_ "GenMsgCycleTime" BO_ 2416443648 3300;
BA_ "SendType" BO_ 2416443648 "Burst";
BA_ "Status" BO_ 2416443648 "Planned";
BA_ "Variant" BO_ 2416443648 "bmu_qev6";
BA_ "VFrameFormat" BO_ 2416443648 1;
BA_ "GenMsgCycleTime" BO_ 2416443649 3300;
BA_ "SendType" BO_ 2416443649 "Burst";
BA_ "Status" BO_ 2416443649 "Planned";
BA_ "Variant" BO_ 2416443649 "bmu_qev6";
BA_ "VFrameFormat" BO_ 2416443649 1;
BA_ "GenMsgCycleTime" BO_ 2416443650 3300;
BA_ "SendType" BO_ 2416443650 "Burst";
BA_ "Status" BO_ 2416443650 "Planned";
BA_ "Variant" BO_ 2416443650 "bmu_qev6";
BA_ "VFrameFormat" BO_ 2416443650 1;
BA_ "GenMsgCycleTime" BO_ 2416443651 3300;
BA_ "SendType" BO_ 2416443651 "Burst";
BA_ "Status" BO_ 2416443651 "Planned";
BA_ "Variant" BO_ 2416443651 "bmu_qev6";
BA_ "VFrameFormat" BO_ 2416443651 1;
BA_ "GenMsgCycleTime" BO_ 2416443664 3300;
BA_ "SendType" BO_ 2416443664 "Burst";
BA_ "Status" BO_ 2416443664 "Planned";
BA_ "Variant" BO_ 2416443664 "bmu_qev6";
BA_ "VFrameFormat" BO_ 2416443664 1;
BA_ "GenMsgCycleTime" BO_ 2416443665 3300;
BA_ "SendType" BO_ 2416443665 "Burst";
BA_ "Status" BO_ 2416443665 "Planned";
BA_ "Variant" BO_ 2416443665 "bmu_qev6";
BA_ "VFrameFormat" BO_ 2416443665 1;
BA_ "GenMsgCycleTime" BO_ 2416443666 3300;
BA_ "SendType" BO_ 2416443666 "Burst";
BA_ "Status" BO_ 2416443666 "Planned";
BA_ "Variant" BO_ 2416443666 "bmu_qev6";
BA_ "VFrameFormat" BO_ 2416443666 1;
BA_ "GenMsgCycleTime" BO_ 2416443667 3300;
BA_ "SendType" BO_ 2416443667 "Burst";
BA_ "Status" BO_ 2416443667 "Planned";
BA_ "Variant" BO_ 2416443667 "bmu_qev6";
BA_ "VFrameFormat" BO_ 2416443667 1;
BA_ "GenMsgCycleTime" BO_ 2416443680 3300;
BA_ "SendType" BO_ 2416443680 "Burst";
BA_ "Status" BO_ 2416443680 "Planned";
BA_ "Variant" BO_ 2416443680 "bmu_qev6";
BA_ "VFrameFormat" BO_ 2416443680 1;
BA_ "GenMsgCycleTime" BO_ 2416443681 3300;
BA_ "SendType" BO_ 2416443681 "Burst";
BA_ "Status" BO_ 2416443681 "Planned";
BA_ "Variant" BO_ 2416443681 "bmu_qev6";
BA_ "VFrameFormat" BO_ 2416443681 1;
BA_ "GenMsgCycleTime" BO_ 2416443682 3300;
BA_ "SendType" BO_ 2416443682 "Burst";
BA_ "Status" BO_ 2416443682 "Planned";
BA_ "Variant" BO_ 2416443682 "bmu_qev6";
BA_ "VFrameFormat" BO_ 2416443682 1;
BA_ "GenMsgCycleTime" BO_ 2416443683 3300;
BA_ "SendType" BO_ 2416443683 "Burst";
BA_ "Status" BO_ 2416443683 "Planned";
BA_ "Variant" BO_ 2416443683 "bmu_qev6";
BA_ "VFrameFormat" BO_ 2416443683 1;
BA_ "GenMsgCycleTime" BO_ 2416443696 3300;
BA_ "SendType" BO_ 2416443696 "Burst";
BA_ "Status" BO_ 2416443696 "Planned";
BA_ "Variant" BO_ 2416443696 "bmu_qev6";
BA_ "VFrameFormat" BO_ 2416443696 1;
BA_ "GenMsgCycleTime" BO_ 2416443697 3300;
BA_ "SendType" BO_ 2416443697 "Burst";
BA_ "Status" BO_ 2416443697 "Planned";
BA_ "Variant" BO_ 2416443697 "bmu_qev6";
BA_ "VFrameFormat" BO_ 2416443697 1;
BA_ "GenMsgCycleTime" BO_ 2416443698 3300;
BA_ "SendType" BO_ 2416443698 "Burst";
BA_ "Status" BO_ 2416443698 "Planned";
BA_ "Variant" BO_ 2416443698 "bmu_qev6";
BA_ "VFrameFormat" BO_ 2416443698 1;
BA_ "GenMsgCycleTime" BO_ 2416443699 3300;
BA_ "SendType" BO_ 2416443699 "Burst";
BA_ "Status" BO_ 2416443699 "Planned";
BA_ "Variant" BO_ 2416443699 "bmu_qev6";
BA_ "VFrameFormat" BO_ 2416443699 1;
BA_ "GenMsgCycleTime" BO_ 2416443712 3300;
BA_ "SendType" BO_ 2416443712 "Burst";
BA_ "Status" BO_ 2416443712 "Planned";
BA_ "Variant" BO_ 2416443712 "bmu_qev6";
BA_ "VFrameFormat" BO_ 2416443712 1;
BA_ "GenMsgCycleTime" BO_ 2416443713 3300;
BA_ "SendType" BO_ 2416443713 "Burst";
BA_ "Status" BO_ 2416443713 "Planned";
BA_ "Variant" BO_ 2416443713 "bmu_qev6";
BA_ "VFrameFormat" BO_ 2416443713 1;
BA_ "GenMsgCycleTime" BO_ 2416443714 3300;
BA_ "SendType" BO_ 2416443714 "Burst";
BA_ "Status" BO_ 2416443714 "Planned";
BA_ "Variant" BO_ 2416443714 "bmu_qev6";
BA_ "VFrameFormat" BO_ 2416443714 1;
BA_ "GenMsgCycleTime" BO_ 2416443715 3300;
BA_ "SendType" BO_ 2416443715 "Burst";
BA_ "Status" BO_ 2416443715 "Planned";
BA_ "Variant" BO_ 2416443715 "bmu_qev6";
BA_ "VFrameFormat" BO_ 2416443715 1;
BA_ "GenMsgCycleTime" BO_ 2416443728 3300;
BA_ "SendType" BO_ 2416443728 "Burst";
BA_ "Status" BO_ 2416443728 "Planned";
BA_ "Variant" BO_ 2416443728 "bmu_qev6";
BA_ "VFrameFormat" BO_ 2416443728 1;
BA_ "GenMsgCycleTime" BO_ 2416443729 3300;
BA_ "SendType" BO_ 2416443729 "Burst";
BA_ "Status" BO_ 2416443729 "Planned";
BA_ "Variant" BO_ 2416443729 "bmu_qev6";
BA_ "VFrameFormat" BO_ 2416443729 1;
BA_ "GenMsgCycleTime" BO_ 2416443730 3300;
BA_ "SendType" BO_ 2416443730 "Burst";
BA_ "Status" BO_ 2416443730 "Planned";
BA_ "Variant" BO_ 2416443730 "bmu_qev6";
BA_ "VFrameFormat" BO_ 2416443730 1;
BA_ "GenMsgCycleTime" BO_ 2416443731 3300;
BA_ "SendType" BO_ 2416443731 "Burst";
BA_ "Status" BO_ 2416443731 "Planned";
BA_ "Variant" BO_ 2416443731 "bmu_qev6";
BA_ "VFrameFormat" BO_ 2416443731 1;
BA_ "GenMsgCycleTime" BO_ 2416443744 3300;
BA_ "SendType" BO_ 2416443744 "Burst";
BA_ "Status" BO_ 2416443744 "Planned";
BA_ "Variant" BO_ 2416443744 "bmu_qev6";
BA_ "VFrameFormat" BO_ 2416443744 1;
BA_ "GenMsgCycleTime" BO_ 2416443745 3300;
BA_ "SendType" BO_ 2416443745 "Burst";
BA_ "Status" BO_ 2416443745 "Planned";
BA_ "Variant" BO_ 2416443745 "bmu_qev6";
BA_ "VFrameFormat" BO_ 2416443745 1;
BA_ "GenMsgCycleTime" BO_ 2416443746 3300;
BA_ "SendType" BO_ 2416443746 "Burst";
BA_ "Status" BO_ 2416443746 "Planned";
BA_ "Variant" BO_ 2416443746 "bmu_qev6";
BA_ "VFrameFormat" BO_ 2416443746 1;
BA_ "GenMsgCycleTime" BO_ 2416443747 3300;
BA_ "SendType" BO_ 2416443747 "Burst";
BA_ "Status" BO_ 2416443747 "Planned";
BA_ "Variant" BO_ 2416443747 "bmu_qev6";
BA_ "VFrameFormat" BO_ 2416443747 1;
BA_ "GenMsgCycleTime" BO_ 2416443760 3300;
BA_ "SendType" BO_ 2416443760 "Burst";
BA_ "Status" BO_ 2416443760 "Planned";
BA_ "Variant" BO_ 2416443760 "bmu_qev6";
BA_ "VFrameFormat" BO_ 2416443760 1;
BA_ "GenMsgCycleTime" BO_ 2416443761 3300;
BA_ "SendType" BO_ 2416443761 "Burst";
BA_ "Status" BO_ 2416443761 "Planned";
BA_ "Variant" BO_ 2416443761 "bmu_qev6";
BA_ "VFrameFormat" BO_ 2416443761 1;
BA_ "GenMsgCycleTime" BO_ 2416443762 3300;
BA_ "SendType" BO_ 2416443762 "Burst";
BA_ "Status" BO_ 2416443762 "Planned";
BA_ "Variant" BO_ 2416443762 "bmu_qev6";
BA_ "VFrameFormat" BO_ 2416443762 1;
BA_ "GenMsgCycleTime" BO_ 2416443763 3300;
BA_ "SendType" BO_ 2416443763 "Burst";
BA_ "Status" BO_ 2416443763 "Planned";
BA_ "Variant" BO_ 2416443763 "bmu_qev6";
BA_ "VFrameFormat" BO_ 2416443763 1;
BA_ "GenMsgCycleTime" BO_ 2416444416 3300;
BA_ "SendType" BO_ 2416444416 "Burst";
BA_ "Status" BO_ 2416444416 "Planned";
BA_ "Variant" BO_ 2416444416 "bmu_qev6";
BA_ "VFrameFormat" BO_ 2416444416 1;
BA_ "GenMsgCycleTime" BO_ 2416444417 3300;
BA_ "SendType" BO_ 2416444417 "Burst";
BA_ "Status" BO_ 2416444417 "Planned";
BA_ "Variant" BO_ 2416444417 "bmu_qev6";
BA_ "VFrameFormat" BO_ 2416444417 1;
BA_ "GenMsgCycleTime" BO_ 2416444432 3300;
BA_ "SendType" BO_ 2416444432 "Burst";
BA_ "Status" BO_ 2416444432 "Planned";
BA_ "Variant" BO_ 2416444432 "bmu_qev6";
BA_ "VFrameFormat" BO_ 2416444432 1;
BA_ "GenMsgCycleTime" BO_ 2416444433 3300;
BA_ "SendType" BO_ 2416444433 "Burst";
BA_ "Status" BO_ 2416444433 "Planned";
BA_ "Variant" BO_ 2416444433 "bmu_qev6";
BA_ "VFrameFormat" BO_ 2416444433 1;
BA_ "GenMsgCycleTime" BO_ 2416444448 3300;
BA_ "SendType" BO_ 2416444448 "Burst";
BA_ "Status" BO_ 2416444448 "Planned";
BA_ "Variant" BO_ 2416444448 "bmu_qev6";
BA_ "VFrameFormat" BO_ 2416444448 1;
BA_ "GenMsgCycleTime" BO_ 2416444449 3300;
BA_ "SendType" BO_ 2416444449 "Burst";
BA_ "Status" BO_ 2416444449 "Planned";
BA_ "Variant" BO_ 2416444449 "bmu_qev6";
BA_ "VFrameFormat" BO_ 2416444449 1;
BA_ "GenMsgCycleTime" BO_ 2416444464 3300;
BA_ "SendType" BO_ 2416444464 "Burst";
BA_ "Status" BO_ 2416444464 "Planned";
BA_ "Variant" BO_ 2416444464 "bmu_qev6";
BA_ "VFrameFormat" BO_ 2416444464 1;
BA_ "GenMsgCycleTime" BO_ 2416444465 3300;
BA_ "SendType" BO_ 2416444465 "Burst";
BA_ "Status" BO_ 2416444465 "Planned";
BA_ "Variant" BO_ 2416444465 "bmu_qev6";
BA_ "VFrameFormat" BO_ 2416444465 1;
BA_ "GenMsgCycleTime" BO_ 2416444480 3300;
BA_ "SendType" BO_ 2416444480 "Burst";
BA_ "Status" BO_ 2416444480 "Planned";
BA_ "Variant" BO_ 2416444480 "bmu_qev6";
BA_ "VFrameFormat" BO_ 2416444480 1;
BA_ "GenMsgCycleTime" BO_ 2416444481 3300;
BA_ "SendType" BO_ 2416444481 "Burst";
BA_ "Status" BO_ 2416444481 "Planned";
BA_ "Variant" BO_ 2416444481 "bmu_qev6";
BA_ "VFrameFormat" BO_ 2416444481 1;
BA_ "GenMsgCycleTime" BO_ 2416444496 3300;
BA_ "SendType" BO_ 2416444496 "Burst";
BA_ "Status" BO_ 2416444496 "Planned";
BA_ "Variant" BO_ 2416444496 "bmu_qev6";
BA_ "VFrameFormat" BO_ 2416444496 1;
BA_ "GenMsgCycleTime" BO_ 2416444497 3300;
BA_ "SendType" BO_ 2416444497 "Burst";
BA_ "Status" BO_ 2416444497 "Planned";
BA_ "Variant" BO_ 2416444497 "bmu_qev6";
BA_ "VFrameFormat" BO_ 2416444497 1;
BA_ "GenMsgCycleTime" BO_ 2416444512 3300;
BA_ "SendType" BO_ 2416444512 "Burst";
BA_ "Status" BO_ 2416444512 "Planned";
BA_ "Variant" BO_ 2416444512 "bmu_qev6";
BA_ "VFrameFormat" BO_ 2416444512 1;
BA_ "GenMsgCycleTime" BO_ 2416444513 3300;
BA_ "SendType" BO_ 2416444513 "Burst";
BA_ "Status" BO_ 2416444513 "Planned";
BA_ "Variant" BO_ 2416444513 "bmu_qev6";
BA_ "VFrameFormat" BO_ 2416444513 1;
BA_ "GenMsgCycleTime" BO_ 2416444528 3300;
BA_ "SendType" BO_ 2416444528 "Burst";
BA_ "Status" BO_ 2416444528 "Planned";
BA_ "Variant" BO_ 2416444528 "bmu_qev6";
BA_ "VFrameFormat" BO_ 2416444528 1;
BA_ "GenMsgCycleTime" BO_ 2416444529 3300;
BA_ "SendType" BO_ 2416444529 "Burst";
BA_ "Status" BO_ 2416444529 "Planned";
BA_ "Variant" BO_ 2416444529 "bmu_qev6";
BA_ "VFrameFormat" BO_ 2416444529 1;
BA_ "GenMsgCycleTime" BO_ 2416444544 3300;
BA_ "SendType" BO_ 2416444544 "Burst";
BA_ "Status" BO_ 2416444544 "Planned";
BA_ "Variant" BO_ 2416444544 "bmu_qev6";
BA_ "VFrameFormat" BO_ 2416444544 1;
BA_ "GenMsgCycleTime" BO_ 2416444545 3300;
BA_ "SendType" BO_ 2416444545 "Burst";
BA_ "Status" BO_ 2416444545 "Planned";
BA_ "Variant" BO_ 2416444545 "bmu_qev6";
BA_ "VFrameFormat" BO_ 2416444545 1;
BA_ "GenMsgCycleTime" BO_ 2416444560 3300;
BA_ "SendType" BO_ 2416444560 "Burst";
BA_ "Status" BO_ 2416444560 "Planned";
BA_ "Variant" BO_ 2416444560 "bmu_qev6";
BA_ "VFrameFormat" BO_ 2416444560 1;
BA_ "GenMsgCycleTime" BO_ 2416444561 3300;
BA_ "SendType" BO_ 2416444561 "Burst";
BA_ "Status" BO_ 2416444561 "Planned";
BA_ "Variant" BO_ 2416444561 "bmu_qev6";
BA_ "VFrameFormat" BO_ 2416444561 1;
BA_ "GenMsgCycleTime" BO_ 2416444576 3300;
BA_ "SendType" BO_ 2416444576 "Burst";
BA_ "Status" BO_ 2416444576 "Planned";
BA_ "Variant" BO_ 2416444576 "bmu_qev6";
BA_ "VFrameFormat" BO_ 2416444576 1;
BA_ "GenMsgCycleTime" BO_ 2416444577 3300;
BA_ "SendType" BO_ 2416444577 "Burst";
BA_ "Status" BO_ 2416444577 "Planned";
BA_ "Variant" BO_ 2416444577 "bmu_qev6";
BA_ "VFrameFormat" BO_ 2416444577 1;
BA_ "GenMsgCycleTime" BO_ 2416444592 3300;
BA_ "SendType" BO_ 2416444592 "Burst";
BA_ "Status" BO_ 2416444592 "Planned";
BA_ "Variant" BO_ 2416444592 "bmu_qev6";
BA_ "VFrameFormat" BO_ 2416444592 1;
BA_ "GenMsgCycleTime" BO_ 2416444593 3300;
BA_ "SendType" BO_ 2416444593 "Burst";
BA_ "Status" BO_ 2416444593 "Planned";
BA_ "Variant" BO_ 2416444593 "bmu_qev6";
BA_ "VFrameFormat" BO_ 2416444593 1;
BA_ "GenMsgCycleTime" BO_ 2416444608 3300;
BA_ "SendType" BO_ 2416444608 "Burst";
BA_ "Status" BO_ 2416444608 "Planned";
BA_ "Variant" BO_ 2416444608 "bmu_qev6";
BA_ "VFrameFormat" BO_ 2416444608 1;
BA_ "GenMsgCycleTime" BO_ 2416444609 3300;
BA_ "SendType" BO_ 2416444609 "Burst";
BA_ "Status" BO_ 2416444609 "Planned";
BA_ "Variant" BO_ 2416444609 "bmu_qev6";
BA_ "VFrameFormat" BO_ 2416444609 1;
BA_ "GenMsgCycleTime" BO_ 2416444624 3300;
BA_ "SendType" BO_ 2416444624 "Burst";
BA_ "Status" BO_ 2416444624 "Planned";
BA_ "Variant" BO_ 2416444624 "bmu_qev6";
BA_ "VFrameFormat" BO_ 2416444624 1;
BA_ "GenMsgCycleTime" BO_ 2416444625 3300;
BA_ "SendType" BO_ 2416444625 "Burst";
BA_ "Status" BO_ 2416444625 "Planned";
BA_ "Variant" BO_ 2416444625 "bmu_qev6";
BA_ "VFrameFormat" BO_ 2416444625 1;
BA_ "GenMsgCycleTime" BO_ 2416444640 3300;
BA_ "SendType" BO_ 2416444640 "Burst";
BA_ "Status" BO_ 2416444640 "Planned";
BA_ "Variant" BO_ 2416444640 "bmu_qev6";
BA_ "VFrameFormat" BO_ 2416444640 1;
BA_ "GenMsgCycleTime" BO_ 2416444641 3300;
BA_ "SendType" BO_ 2416444641 "Burst";
BA_ "Status" BO_ 2416444641 "Planned";
BA_ "Variant" BO_ 2416444641 "bmu_qev6";
BA_ "VFrameFormat" BO_ 2416444641 1;
BA_ "GenMsgCycleTime" BO_ 2416444656 3300;
BA_ "SendType" BO_ 2416444656 "Burst";
BA_ "Status" BO_ 2416444656 "Planned";
BA_ "Variant" BO_ 2416444656 "bmu_qev6";
BA_ "VFrameFormat" BO_ 2416444656 1;
BA_ "GenMsgCycleTime" BO_ 2416444657 3300;
BA_ "SendType" BO_ 2416444657 "Burst";
BA_ "Status" BO_ 2416444657 "Planned";
BA_ "Variant" BO_ 2416444657 "bmu_qev6";
BA_ "VFrameFormat" BO_ 2416444657 1;
BA_ "GenMsgCycleTime" BO_ 2416444672 3300;
BA_ "SendType" BO_ 2416444672 "Burst";
BA_ "Status" BO_ 2416444672 "Planned";
BA_ "Variant" BO_ 2416444672 "bmu_qev6";
BA_ "VFrameFormat" BO_ 2416444672 1;
BA_ "GenMsgCycleTime" BO_ 2416444673 3300;
BA_ "SendType" BO_ 2416444673 "Burst";
BA_ "Status" BO_ 2416444673 "Planned";
BA_ "Variant" BO_ 2416444673 "bmu_qev6";
BA_ "VFrameFormat" BO_ 2416444673 1;
BA_ "GenMsgCycleTime" BO_ 2416444688 3300;
BA_ "SendType" BO_ 2416444688 "Burst";
BA_ "Status" BO_ 2416444688 "Planned";
BA_ "Variant" BO_ 2416444688 "bmu_qev6";
BA_ "VFrameFormat" BO_ 2416444688 1;
BA_ "GenMsgCycleTime" BO_ 2416444689 3300;
BA_ "SendType" BO_ 2416444689 "Burst";
BA_ "Status" BO_ 2416444689 "Planned";
BA_ "Variant" BO_ 2416444689 "bmu_qev6";
BA_ "VFrameFormat" BO_ 2416444689 1;
BA_ "GenMsgCycleTime" BO_ 2416444704 3300;
BA_ "SendType" BO_ 2416444704 "Burst";
BA_ "Status" BO_ 2416444704 "Planned";
BA_ "Variant" BO_ 2416444704 "bmu_qev6";
BA_ "VFrameFormat" BO_ 2416444704 1;
BA_ "GenMsgCycleTime" BO_ 2416444705 3300;
BA_ "SendType" BO_ 2416444705 "Burst";
BA_ "Status" BO_ 2416444705 "Planned";
BA_ "Variant" BO_ 2416444705 "bmu_qev6";
BA_ "VFrameFormat" BO_ 2416444705 1;
BA_ "GenMsgCycleTime" BO_ 2416444720 3300;
BA_ "SendType" BO_ 2416444720 "Burst";
BA_ "Status" BO_ 2416444720 "Planned";
BA_ "Variant" BO_ 2416444720 "bmu_qev6";
BA_ "VFrameFormat" BO_ 2416444720 1;
BA_ "GenMsgCycleTime" BO_ 2416444721 3300;
BA_ "SendType" BO_ 2416444721 "Burst";
BA_ "Status" BO_ 2416444721 "Planned";
BA_ "Variant" BO_ 2416444721 "bmu_qev6";
BA_ "VFrameFormat" BO_ 2416444721 1;
BA_ "GenMsgCycleTime" BO_ 2416444736 3300;
BA_ "SendType" BO_ 2416444736 "Burst";
BA_ "Status" BO_ 2416444736 "Planned";
BA_ "Variant" BO_ 2416444736 "bmu_qev6";
BA_ "VFrameFormat" BO_ 2416444736 1;
BA_ "GenMsgCycleTime" BO_ 2416444737 3300;
BA_ "SendType" BO_ 2416444737 "Burst";
BA_ "Status" BO_ 2416444737 "Planned";
BA_ "Variant" BO_ 2416444737 "bmu_qev6";
BA_ "VFrameFormat" BO_ 2416444737 1;
BA_ "GenMsgCycleTime" BO_ 2416444752 3300;
BA_ "SendType" BO_ 2416444752 "Burst";
BA_ "Status" BO_ 2416444752 "Planned";
BA_ "Variant" BO_ 2416444752 "bmu_qev6";
BA_ "VFrameFormat" BO_ 2416444752 1;
BA_ "GenMsgCycleTime" BO_ 2416444753 3300;
BA_ "SendType" BO_ 2416444753 "Burst";
BA_ "Status" BO_ 2416444753 "Planned";
BA_ "Variant" BO_ 2416444753 "bmu_qev6";
BA_ "VFrameFormat" BO_ 2416444753 1;
BA_ "GenMsgCycleTime" BO_ 2416444768 3300;
BA_ "SendType" BO_ 2416444768 "Burst";
BA_ "Status" BO_ 2416444768 "Planned";
BA_ "Variant" BO_ 2416444768 "bmu_qev6";
BA_ "VFrameFormat" BO_ 2416444768 1;
BA_ "GenMsgCycleTime" BO_ 2416444769 3300;
BA_ "SendType" BO_ 2416444769 "Burst";
BA_ "Status" BO_ 2416444769 "Planned";
BA_ "Variant" BO_ 2416444769 "bmu_qev6";
BA_ "VFrameFormat" BO_ 2416444769 1;
BA_ "GenMsgCycleTime" BO_ 2416444784 3300;
BA_ "SendType" BO_ 2416444784 "Burst";
BA_ "Status" BO_ 2416444784 "Planned";
BA_ "Variant" BO_ 2416444784 "bmu_qev6";
BA_ "VFrameFormat" BO_ 2416444784 1;
BA_ "GenMsgCycleTime" BO_ 2416444785 3300;
BA_ "SendType" BO_ 2416444785 "Burst";
BA_ "Status" BO_ 2416444785 "Planned";
BA_ "Variant" BO_ 2416444785 "bmu_qev6";
BA_ "VFrameFormat" BO_ 2416444785 1;
BA_ "GenMsgCycleTime" BO_ 2416445440 3300;
BA_ "SendType" BO_ 2416445440 "Burst";
BA_ "Status" BO_ 2416445440 "Planned";
BA_ "Variant" BO_ 2416445440 "bmu_qev6";
BA_ "VFrameFormat" BO_ 2416445440 1;
BA_ "GenMsgCycleTime" BO_ 2416445456 3300;
BA_ "SendType" BO_ 2416445456 "Burst";
BA_ "Status" BO_ 2416445456 "Planned";
BA_ "Variant" BO_ 2416445456 "bmu_qev6";
BA_ "VFrameFormat" BO_ 2416445456 1;
BA_ "GenMsgCycleTime" BO_ 2416445472 3300;
BA_ "SendType" BO_ 2416445472 "Burst";
BA_ "Status" BO_ 2416445472 "Planned";
BA_ "Variant" BO_ 2416445472 "bmu_qev6";
BA_ "VFrameFormat" BO_ 2416445472 1;
BA_ "GenMsgCycleTime" BO_ 2416445488 3300;
BA_ "SendType" BO_ 2416445488 "Burst";
BA_ "Status" BO_ 2416445488 "Planned";
BA_ "Variant" BO_ 2416445488 "bmu_qev6";
BA_ "VFrameFormat" BO_ 2416445488 1;
BA_ "GenMsgCycleTime" BO_ 2416445504 3300;
BA_ "SendType" BO_ 2416445504 "Burst";
BA_ "Status" BO_ 2416445504 "Planned";
BA_ "Variant" BO_ 2416445504 "bmu_qev6";
BA_ "VFrameFormat" BO_ 2416445504 1;
BA_ "GenMsgCycleTime" BO_ 2416445520 3300;
BA_ "SendType" BO_ 2416445520 "Burst";
BA_ "Status" BO_ 2416445520 "Planned";
BA_ "Variant" BO_ 2416445520 "bmu_qev6";
BA_ "VFrameFormat" BO_ 2416445520 1;
BA_ "GenMsgCycleTime" BO_ 2416445536 3300;
BA_ "SendType" BO_ 2416445536 "Burst";
BA_ "Status" BO_ 2416445536 "Planned";
BA_ "Variant" BO_ 2416445536 "bmu_qev6";
BA_ "VFrameFormat" BO_ 2416445536 1;
BA_ "GenMsgCycleTime" BO_ 2416445552 3300;
BA_ "SendType" BO_ 2416445552 "Burst";
BA_ "Status" BO_ 2416445552 "Planned";
BA_ "Variant" BO_ 2416445552 "bmu_qev6";
BA_ "VFrameFormat" BO_ 2416445552 1;
BA_ "GenMsgCycleTime" BO_ 2416445568 3300;
BA_ "SendType" BO_ 2416445568 "Burst";
BA_ "Status" BO_ 2416445568 "Planned";
BA_ "Variant" BO_ 2416445568 "bmu_qev6";
BA_ "VFrameFormat" BO_ 2416445568 1;
BA_ "GenMsgCycleTime" BO_ 2416445584 3300;
BA_ "SendType" BO_ 2416445584 "Burst";
BA_ "Status" BO_ 2416445584 "Planned";
BA_ "Variant" BO_ 2416445584 "bmu_qev6";
BA_ "VFrameFormat" BO_ 2416445584 1;
BA_ "GenMsgCycleTime" BO_ 2416445600 3300;
BA_ "SendType" BO_ 2416445600 "Burst";
BA_ "Status" BO_ 2416445600 "Planned";
BA_ "Variant" BO_ 2416445600 "bmu_qev6";
BA_ "VFrameFormat" BO_ 2416445600 1;
BA_ "GenMsgCycleTime" BO_ 2416445616 3300;
BA_ "SendType" BO_ 2416445616 "Burst";
BA_ "Status" BO_ 2416445616 "Planned";
BA_ "Variant" BO_ 2416445616 "bmu_qev6";
BA_ "VFrameFormat" BO_ 2416445616 1;
BA_ "GenMsgCycleTime" BO_ 2416445632 3300;
BA_ "SendType" BO_ 2416445632 "Burst";
BA_ "Status" BO_ 2416445632 "Planned";
BA_ "Variant" BO_ 2416445632 "bmu_qev6";
BA_ "VFrameFormat" BO_ 2416445632 1;
BA_ "GenMsgCycleTime" BO_ 2416445648 3300;
BA_ "SendType" BO_ 2416445648 "Burst";
BA_ "Status" BO_ 2416445648 "Planned";
BA_ "Variant" BO_ 2416445648 "bmu_qev6";
BA_ "VFrameFormat" BO_ 2416445648 1;
BA_ "GenMsgCycleTime" BO_ 2416445664 3300;
BA_ "SendType" BO_ 2416445664 "Burst";
BA_ "Status" BO_ 2416445664 "Planned";
BA_ "Variant" BO_ 2416445664 "bmu_qev6";
BA_ "VFrameFormat" BO_ 2416445664 1;
BA_ "GenMsgCycleTime" BO_ 2416445680 3300;
BA_ "SendType" BO_ 2416445680 "Burst";
BA_ "Status" BO_ 2416445680 "Planned";
BA_ "Variant" BO_ 2416445680 "bmu_qev6";
BA_ "VFrameFormat" BO_ 2416445680 1;
BA_ "GenMsgCycleTime" BO_ 2416445696 3300;
BA_ "SendType" BO_ 2416445696 "Burst";
BA_ "Status" BO_ 2416445696 "Planned";
BA_ "Variant" BO_ 2416445696 "bmu_qev6";
BA_ "VFrameFormat" BO_ 2416445696 1;
BA_ "GenMsgCycleTime" BO_ 2416445712 3300;
BA_ "SendType" BO_ 2416445712 "Burst";
BA_ "Status" BO_ 2416445712 "Planned";
BA_ "Variant" BO_ 2416445712 "bmu_qev6";
BA_ "VFrameFormat" BO_ 2416445712 1;
BA_ "GenMsgCycleTime" BO_ 2416445728 3300;
BA_ "SendType" BO_ 2416445728 "Burst";
BA_ "Status" BO_ 2416445728 "Planned";
BA_ "Variant" BO_ 2416445728 "bmu_qev6";
BA_ "VFrameFormat" BO_ 2416445728 1;
BA_ "GenMsgCycleTime" BO_ 2416445744 3300;
BA_ "SendType" BO_ 2416445744 "Burst";
BA_ "Status" BO_ 2416445744 "Planned";
BA_ "Variant" BO_ 2416445744 "bmu_qev6";
BA_ "VFrameFormat" BO_ 2416445744 1;
BA_ "GenMsgCycleTime" BO_ 2416445760 3300;
BA_ "SendType" BO_ 2416445760 "Burst";
BA_ "Status" BO_ 2416445760 "Planned";
BA_ "Variant" BO_ 2416445760 "bmu_qev6";
BA_ "VFrameFormat" BO_ 2416445760 1;
BA_ "GenMsgCycleTime" BO_ 2416445776 3300;
BA_ "SendType" BO_ 2416445776 "Burst";
BA_ "Status" BO_ 2416445776 "Planned";
BA_ "Variant" BO_ 2416445776 "bmu_qev6";
BA_ "VFrameFormat" BO_ 2416445776 1;
BA_ "GenMsgCycleTime" BO_ 2416445792 3300;
BA_ "SendType" BO_ 2416445792 "Burst";
BA_ "Status" BO_ 2416445792 "Planned";
BA_ "Variant" BO_ 2416445792 "bmu_qev6";
BA_ "VFrameFormat" BO_ 2416445792 1;
BA_ "GenMsgCycleTime" BO_ 2416445808 3300;
BA_ "SendType" BO_ 2416445808 "Burst";
BA_ "Status" BO_ 2416445808 "Planned";
BA_ "Variant" BO_ 2416445808 "bmu_qev6";
BA_ "VFrameFormat" BO_ 2416445808 1;
BA_ "GenMsgCycleTime" BO_ 2416446464 3300;
BA_ "SendType" BO_ 2416446464 "Burst";
BA_ "Status" BO_ 2416446464 "Planned";
BA_ "Variant" BO_ 2416446464 "bmu_qev6";
BA_ "VFrameFormat" BO_ 2416446464 1;
BA_ "GenMsgCycleTime" BO_ 2416446720 100;
BA_ "RxTimeoutMs" BO_ 2416446720 500;
BA_ "MoTeC" BO_ 2416446720 "Yes";
BA_ "Status" BO_ 2416446720 "Planned";
BA_ "Variant" BO_ 2416446720 "bmu_qev6";
BA_ "VFrameFormat" BO_ 2416446720 1;
BA_ "GenMsgCycleTime" BO_ 2416446736 500;
BA_ "RxTimeoutMs" BO_ 2416446736 2000;
BA_ "MoTeC" BO_ 2416446736 "Yes";
BA_ "Status" BO_ 2416446736 "Planned";
BA_ "Variant" BO_ 2416446736 "bmu_qev6";
BA_ "VFrameFormat" BO_ 2416446736 1;
BA_ "GenMsgCycleTime" BO_ 2416446752 1000;
BA_ "RxTimeoutMs" BO_ 2416446752 3000;
BA_ "MoTeC" BO_ 2416446752 "Yes";
BA_ "Status" BO_ 2416446752 "Planned";
BA_ "Variant" BO_ 2416446752 "bmu_qev6";
BA_ "VFrameFormat" BO_ 2416446752 1;
BA_ "MoTeCGroup" SG_ 2416446752 BMU_SocValid "BMU_SocFlags";
BA_ "MoTeCGroup" SG_ 2416446752 BMU_SocCalibrated "BMU_SocFlags";
BA_ "GenMsgCycleTime" BO_ 2416446768 500;
BA_ "RxTimeoutMs" BO_ 2416446768 2000;
BA_ "MoTeC" BO_ 2416446768 "Yes";
BA_ "Status" BO_ 2416446768 "Proposed";
BA_ "Variant" BO_ 2416446768 "bmu_qev6";
BA_ "VFrameFormat" BO_ 2416446768 1;
BA_ "GenMsgCycleTime" BO_ 2416446976 100;
BA_ "Status" BO_ 2416446976 "Planned";
BA_ "Variant" BO_ 2416446976 "bmu_qev6";
BA_ "VFrameFormat" BO_ 2416446976 1;
BA_ "GenMsgCycleTime" BO_ 2418327552 100;
BA_ "RxTimeoutMs" BO_ 2418327552 1000;
BA_ "MoTeC" BO_ 2418327552 "Yes";
BA_ "Variant" BO_ 2418327552 "bmu_comp25";
BA_ "VFrameFormat" BO_ 2418327552 1;
BA_ "MoTeCGroup" SG_ 2418327552 BMU_F_HbCmu "BMU_Flags";
BA_ "MoTeCGroup" SG_ 2418327552 BMU_F_HbSendyne1 "BMU_Flags";
BA_ "MoTeCGroup" SG_ 2418327552 BMU_F_HbSendyne2 "BMU_Flags";
BA_ "MoTeCGroup" SG_ 2418327552 BMU_F_HbEcu "BMU_Flags";
BA_ "MoTeCGroup" SG_ 2418327552 BMU_F_HbChrgCtrl "BMU_Flags";
BA_ "MoTeCGroup" SG_ 2418327552 BMU_F_Watchdog "BMU_Flags";
BA_ "MoTeCGroup" SG_ 2418327552 BMU_F_Can1 "BMU_Flags";
BA_ "MoTeCGroup" SG_ 2418327552 BMU_F_Can2 "BMU_Flags";
BA_ "MoTeCGroup" SG_ 2418327552 BMU_F_ContactorPos "BMU_Flags";
BA_ "MoTeCGroup" SG_ 2418327552 BMU_F_ContactorNeg "BMU_Flags";
BA_ "MoTeCGroup" SG_ 2418327552 BMU_F_ContactorPchrg "BMU_Flags";
BA_ "MoTeCGroup" SG_ 2418327552 BMU_F_PrechargeTimeout "BMU_Flags";
BA_ "MoTeCGroup" SG_ 2418327552 BMU_F_CmuOverVolt "BMU_Flags";
BA_ "MoTeCGroup" SG_ 2418327552 BMU_F_CmuUnderVolt "BMU_Flags";
BA_ "MoTeCGroup" SG_ 2418327552 BMU_F_CmuBadTemp "BMU_Flags";
BA_ "MoTeCGroup" SG_ 2418327552 BMU_F_CmuOpenVolt "BMU_Flags";
BA_ "MoTeCGroup" SG_ 2418327552 BMU_F_CmuOpenTemp "BMU_Flags";
BA_ "MoTeCGroup" SG_ 2418327552 BMU_F_CmuMissingVolt "BMU_Flags";
BA_ "MoTeCGroup" SG_ 2418327552 BMU_F_CmuMissingTemp "BMU_Flags";
BA_ "MoTeCGroup" SG_ 2418327552 BMU_F_ShdnBmu "BMU_Flags";
BA_ "MoTeCGroup" SG_ 2418327552 BMU_F_ShdnPdoc "BMU_Flags";
BA_ "MoTeCGroup" SG_ 2418327552 BMU_F_ShdnImd "BMU_Flags";
BA_ "MoTeCGroup" SG_ 2418327552 BMU_F_ShdnInterlock "BMU_Flags";
BA_ "MoTeCGroup" SG_ 2418327552 BMU_F_Balancing "BMU_Flags";
BA_ "MoTeCGroup" SG_ 2418327552 BMU_F_DieTemps "BMU_Flags";
BA_ "MoTeCGroup" SG_ 2418327552 BMU_F_HvKey "BMU_Flags";
BA_ "MoTeCGroup" SG_ 2418327552 BMU_F_ChrgDetect "BMU_Flags";
BA_ "MoTeCGroup" SG_ 2418327552 BMU_F_ChrgCtrl "BMU_Flags";
BA_ "MoTeCLog" SG_ 2418327552 BMU_PackState "No";
BA_ "MoTeCLog" SG_ 2418327552 BMU_SOC "No";
BA_ "GenMsgCycleTime" BO_ 2424356864 100;
BA_ "Status" BO_ 2424356864 "Legacy";
BA_ "VFrameFormat" BO_ 2424356864 1;
BA_ "GenMsgCycleTime" BO_ 2424356865 100;
BA_ "RxTimeoutMs" BO_ 2424356865 1000;
BA_ "Status" BO_ 2424356865 "Planned";
BA_ "Variant" BO_ 2424356865 "bmu_comp25";
BA_ "VFrameFormat" BO_ 2424356865 1;
BA_ "SendType" BO_ 2424357104 "OnRequest";
BA_ "Status" BO_ 2424357104 "Legacy";
BA_ "VFrameFormat" BO_ 2424357104 1;
BA_ "SendType" BO_ 2424357105 "OnRequest";
BA_ "Status" BO_ 2424357105 "Legacy";
BA_ "VFrameFormat" BO_ 2424357105 1;
BA_ "SendType" BO_ 2554855424 "OnRequest";
BA_ "Status" BO_ 2554855424 "Planned";
BA_ "VFrameFormat" BO_ 2554855424 1;
BA_ "SendType" BO_ 2555117568 "OnRequest";
BA_ "Status" BO_ 2555117568 "Planned";
BA_ "VFrameFormat" BO_ 2555117568 1;
BA_ "GenMsgCycleTime" BO_ 2568552305 10;
BA_ "RxTimeoutMs" BO_ 2568552305 3000;
BA_ "MoTeC" BO_ 2568552305 "Yes";
BA_ "Variant" BO_ 2568552305 "inv_sevcon";
BA_ "VFrameFormat" BO_ 2568552305 1;
BA_ "GenMsgCycleTime" BO_ 2568552306 10;
BA_ "RxTimeoutMs" BO_ 2568552306 3000;
BA_ "MoTeC" BO_ 2568552306 "Yes";
BA_ "Variant" BO_ 2568552306 "inv_sevcon";
BA_ "VFrameFormat" BO_ 2568552306 1;
BA_ "GenMsgCycleTime" BO_ 2568617841 10;
BA_ "RxTimeoutMs" BO_ 2568617841 3000;
BA_ "MoTeC" BO_ 2568617841 "Yes";
BA_ "Variant" BO_ 2568617841 "inv_sevcon";
BA_ "VFrameFormat" BO_ 2568617841 1;
BA_ "GenMsgCycleTime" BO_ 2568617842 10;
BA_ "RxTimeoutMs" BO_ 2568617842 3000;
BA_ "MoTeC" BO_ 2568617842 "Yes";
BA_ "Variant" BO_ 2568617842 "inv_sevcon";
BA_ "VFrameFormat" BO_ 2568617842 1;
BA_ "GenMsgCycleTime" BO_ 2568683377 10;
BA_ "RxTimeoutMs" BO_ 2568683377 3000;
BA_ "MoTeC" BO_ 2568683377 "Yes";
BA_ "Variant" BO_ 2568683377 "inv_sevcon";
BA_ "VFrameFormat" BO_ 2568683377 1;
BA_ "GenMsgCycleTime" BO_ 2568683378 10;
BA_ "RxTimeoutMs" BO_ 2568683378 3000;
BA_ "MoTeC" BO_ 2568683378 "Yes";
BA_ "Variant" BO_ 2568683378 "inv_sevcon";
BA_ "VFrameFormat" BO_ 2568683378 1;
BA_ "GenMsgCycleTime" BO_ 2568748913 100;
BA_ "RxTimeoutMs" BO_ 2568748913 3000;
BA_ "Variant" BO_ 2568748913 "inv_sevcon";
BA_ "VFrameFormat" BO_ 2568748913 1;
BA_ "GenMsgCycleTime" BO_ 2568748914 100;
BA_ "RxTimeoutMs" BO_ 2568748914 3000;
BA_ "Variant" BO_ 2568748914 "inv_sevcon";
BA_ "VFrameFormat" BO_ 2568748914 1;
BA_ "GenMsgCycleTime" BO_ 2568814449 100;
BA_ "RxTimeoutMs" BO_ 2568814449 3000;
BA_ "Variant" BO_ 2568814449 "inv_sevcon";
BA_ "VFrameFormat" BO_ 2568814449 1;
BA_ "GenMsgCycleTime" BO_ 2568814450 100;
BA_ "RxTimeoutMs" BO_ 2568814450 3000;
BA_ "Variant" BO_ 2568814450 "inv_sevcon";
BA_ "VFrameFormat" BO_ 2568814450 1;
BA_ "SendType" BO_ 2569600881 "Event";
BA_ "Variant" BO_ 2569600881 "inv_sevcon";
BA_ "VFrameFormat" BO_ 2569600881 1;
BA_ "SendType" BO_ 2569600882 "Event";
BA_ "Variant" BO_ 2569600882 "inv_sevcon";
BA_ "VFrameFormat" BO_ 2569600882 1;
BA_ "SendType" BO_ 2569666417 "Event";
BA_ "Variant" BO_ 2569666417 "inv_sevcon";
BA_ "VFrameFormat" BO_ 2569666417 1;
BA_ "SendType" BO_ 2569666418 "Event";
BA_ "Variant" BO_ 2569666418 "inv_sevcon";
BA_ "VFrameFormat" BO_ 2569666418 1;
BA_ "SendType" BO_ 2569731953 "Event";
BA_ "Variant" BO_ 2569731953 "inv_sevcon";
BA_ "VFrameFormat" BO_ 2569731953 1;
BA_ "SendType" BO_ 2569731954 "Event";
BA_ "Variant" BO_ 2569731954 "inv_sevcon";
BA_ "VFrameFormat" BO_ 2569731954 1;
BA_ "SendType" BO_ 2569797489 "Event";
BA_ "Variant" BO_ 2569797489 "inv_sevcon";
BA_ "VFrameFormat" BO_ 2569797489 1;
BA_ "SendType" BO_ 2569797490 "Event";
BA_ "Variant" BO_ 2569797490 "inv_sevcon";
BA_ "VFrameFormat" BO_ 2569797490 1;
BA_ "SendType" BO_ 2569863025 "Event";
BA_ "Variant" BO_ 2569863025 "inv_sevcon";
BA_ "VFrameFormat" BO_ 2569863025 1;
BA_ "SendType" BO_ 2569863026 "Event";
BA_ "Variant" BO_ 2569863026 "inv_sevcon";
BA_ "VFrameFormat" BO_ 2569863026 1;
VAL_ 2286157824 ECU_State 0 "BOOT" 1 "POWERUP" 20 "PREFLIGHT" 40 "PRECHARGE" 41 "ENERGISE" 42 "RTD" 100 "DRIVING" 240 "FAULT" 250 "SHUTDOWN" ;
VAL_ 2286157824 ECU_FaultCode 0 "NONE" 257 "BOARD_OUTPUT_INIT" 258 "BOARD_ADC" 259 "BOARD_EEPROM" 260 "BOARD_CAN" 512 "OUTPUT_CRITICAL" 768 "BMU_TIMEOUT" 769 "BMU_SHUTDOWN" 770 "BMU_PRECHARGE_TIMEOUT" 771 "BMU_HV_FAULT" 772 "BMU_TEMP_FAULT" 773 "BMU_ISOLATION" 774 "BMU_CONTACTOR" 775 "BMU_STATE_UNEXPECTED" 1024 "INV_FAULT" 1040 "INV_TIMEOUT" 1056 "INV_ENERGISE_TIMEOUT" 1057 "INV_ENABLE_FAIL" 1280 "PEDAL_APPS" 1281 "PEDAL_BSE" 1282 "PEDAL_BRAKE_APPS" 1283 "PEDAL_UNCALIBRATED" 1536 "SAFETY_SHDN_OPEN" 1537 "SAFETY_SHDN_TIMEOUT" 1538 "SAFETY_WATCHDOG" 2048 "COMM_CAN_A_BUSOFF" 2049 "COMM_CAN_B_BUSOFF" ;
VAL_ 2286157824 ECU_FaultSeverity 0 "NONE" 1 "WARNING" 2 "CRITICAL" 3 "FATAL" ;
VAL_ 2290122752 SHDN_OldFirstFault 0 "HEALTHY" 1 "INPUT_1_OPEN" 2 "INPUT_2_OPEN" 3 "INPUT_3_OPEN" 4 "INPUT_4_OPEN" 5 "INPUT_5_OPEN" 6 "INPUT_6_OPEN" 7 "INPUT_7_OPEN" 8 "INPUT_8_OPEN" 9 "INPUT_9_OPEN" 10 "INPUT_10_OPEN" ;
VAL_ 2298740736 SHDN_LoopClosed 0 "OPEN" 1 "CLOSED" ;
VAL_ 2298740736 SHDN_FirstOpen 0 "NONE" ;
VAL_ 2307129344 CHRG_State 1 "IDLE" 2 "PRECHARGE_REQUEST" 3 "PRECHARGE" 4 "CHARGING" 15 "STOP_CHARGE" ;
VAL_ 2418327552 BMU_State 0 "START" 1 "INIT_PERIPHERAL" 2 "INIT_CMU" 3 "CHECK_CMU_GPIO" 4 "CHECK_SENDYNE" 5 "CHECK_BOARD" 6 "READY" 7 "PRECHARGE" 8 "TS_ACTIVE" 13 "TRIG_SHDN" 15 "SHUTDOWN" 22 "CHRG_CHECK_BOARD" 23 "CHRG_READY" 24 "CHRG_PRECHARGE" 25 "CHRG_TS_ACTIVE" 26 "CHRG_FAIL" 255 "ERROR" ;
VAL_ 2424356864 VCU_Heartbeat_StateID 0 "BOOT" 1 "POWERUP" 20 "PREFLIGHT" 40 "PRECHARGE" 41 "ENERGISE" 42 "RTD" 100 "DRIVING" 240 "FAULT" 250 "SHUTDOWN" ;
VAL_ 2424356864 fault_code 0 "NONE" 257 "BOARD_OUTPUT_INIT" 258 "BOARD_ADC" 259 "BOARD_EEPROM" 260 "BOARD_CAN" 512 "OUTPUT_CRITICAL(+load)" 768 "BMU_TIMEOUT" 769 "BMU_SHUTDOWN" 770 "BMU_PRECHARGE_TIMEOUT" 771 "BMU_HV_FAULT" 772 "BMU_TEMP_FAULT" 773 "BMU_ISOLATION" 774 "BMU_CONTACTOR" 775 "BMU_STATE_UNEXPECTED" 1024 "INV_FAULT(+inv)" 1040 "INV_TIMEOUT(+inv)" 1056 "INV_ENERGISE_TIMEOUT" 1057 "INV_ENABLE_FAIL" 1280 "PEDAL_APPS" 1281 "PEDAL_BSE" 1282 "PEDAL_BRAKE_APPS" 1283 "PEDAL_UNCALIBRATED" 1536 "SAFETY_SHDN_OPEN" 1537 "SAFETY_SHDN_TIMEOUT" 1538 "SAFETY_WATCHDOG" 2048 "COMM_CAN_A_BUSOFF" 2049 "COMM_CAN_B_BUSOFF" ;
VAL_ 2424356865 ECU_C25_State 0 "BOOT" 1 "POWERUP" 20 "PREFLIGHT" 40 "PRECHARGE" 41 "ENERGISE" 42 "RTD" 100 "DRIVING" 240 "FAULT" 250 "SHUTDOWN" ;
VAL_ 2424357104 DBG_ReqCmd 1 "PING" 16 "OUTPUT_SET" 17 "OUTPUT_DUTY" 18 "OUTPUT_CLEAR" 19 "OUTPUT_TEST_MODE" 32 "PARAM_GET" 33 "PARAM_SET" 34 "PARAM_SAVE" 35 "PARAM_DEFAULTS" 36 "PROFILE_SELECT" 48 "CAL_PEDAL_START" 49 "CAL_PEDAL_PRESSED" 50 "CAL_PEDAL_SAVE" 51 "CAL_PEDAL_ABORT" 52 "CAL_ADC_ZERO" 53 "CAL_ADC_SPAN" 54 "CAL_ADC_SAVE" 55 "CAL_BRAKE_FULLSCALE" 64 "FAULT_CLEAR" 65 "FAULT_LOG_READ" 80 "INV_FAULT_RESET" 96 "LOG_LEVEL" 97 "TELEM_RAW_ADC" 98 "CAPTURE_CONFIG" 99 "CAPTURE_ARM" 100 "CAPTURE_STATUS" 101 "CAPTURE_ABORT" 126 "TEST_WATCHDOG" 127 "REBOOT" ;
VAL_ 2424357105 DBG_RespCmd 1 "PING" 16 "OUTPUT_SET" 17 "OUTPUT_DUTY" 18 "OUTPUT_CLEAR" 19 "OUTPUT_TEST_MODE" 32 "PARAM_GET" 33 "PARAM_SET" 34 "PARAM_SAVE" 35 "PARAM_DEFAULTS" 36 "PROFILE_SELECT" 48 "CAL_PEDAL_START" 49 "CAL_PEDAL_PRESSED" 50 "CAL_PEDAL_SAVE" 51 "CAL_PEDAL_ABORT" 52 "CAL_ADC_ZERO" 53 "CAL_ADC_SPAN" 54 "CAL_ADC_SAVE" 55 "CAL_BRAKE_FULLSCALE" 64 "FAULT_CLEAR" 65 "FAULT_LOG_READ" 80 "INV_FAULT_RESET" 96 "LOG_LEVEL" 97 "TELEM_RAW_ADC" 98 "CAPTURE_CONFIG" 99 "CAPTURE_ARM" 100 "CAPTURE_STATUS" 101 "CAPTURE_ABORT" 126 "TEST_WATCHDOG" 127 "REBOOT" ;
VAL_ 2424357105 DBG_RespStatus 0 "OK" 1 "UNKNOWN_CMD" 2 "REFUSED" 3 "BAD_INDEX" 4 "OUT_OF_RANGE" 5 "BAD_ARG" 6 "FAILED" ;
VAL_ 2554855424 DBG_RespCmd 1 "PING" 16 "OUTPUT_SET" 17 "OUTPUT_DUTY" 18 "OUTPUT_CLEAR" 19 "OUTPUT_TEST_MODE" 32 "PARAM_GET" 33 "PARAM_SET" 34 "PARAM_SAVE" 35 "PARAM_DEFAULTS" 36 "PROFILE_SELECT" 48 "CAL_PEDAL_START" 49 "CAL_PEDAL_PRESSED" 50 "CAL_PEDAL_SAVE" 51 "CAL_PEDAL_ABORT" 52 "CAL_ADC_ZERO" 53 "CAL_ADC_SPAN" 54 "CAL_ADC_SAVE" 55 "CAL_BRAKE_FULLSCALE" 64 "FAULT_CLEAR" 65 "FAULT_LOG_READ" 80 "INV_FAULT_RESET" 96 "LOG_LEVEL" 97 "TELEM_RAW_ADC" 98 "CAPTURE_CONFIG" 99 "CAPTURE_ARM" 100 "CAPTURE_STATUS" 101 "CAPTURE_ABORT" 126 "TEST_WATCHDOG" 127 "REBOOT" ;
VAL_ 2554855424 DBG_RespStatus 0 "OK" 1 "UNKNOWN_CMD" 2 "REFUSED" 3 "BAD_INDEX" 4 "OUT_OF_RANGE" 5 "BAD_ARG" 6 "FAILED" ;
VAL_ 2555117568 DBG_ReqCmd 1 "PING" 16 "OUTPUT_SET" 17 "OUTPUT_DUTY" 18 "OUTPUT_CLEAR" 19 "OUTPUT_TEST_MODE" 32 "PARAM_GET" 33 "PARAM_SET" 34 "PARAM_SAVE" 35 "PARAM_DEFAULTS" 36 "PROFILE_SELECT" 48 "CAL_PEDAL_START" 49 "CAL_PEDAL_PRESSED" 50 "CAL_PEDAL_SAVE" 51 "CAL_PEDAL_ABORT" 52 "CAL_ADC_ZERO" 53 "CAL_ADC_SPAN" 54 "CAL_ADC_SAVE" 55 "CAL_BRAKE_FULLSCALE" 64 "FAULT_CLEAR" 65 "FAULT_LOG_READ" 80 "INV_FAULT_RESET" 96 "LOG_LEVEL" 97 "TELEM_RAW_ADC" 98 "CAPTURE_CONFIG" 99 "CAPTURE_ARM" 100 "CAPTURE_STATUS" 101 "CAPTURE_ABORT" 126 "TEST_WATCHDOG" 127 "REBOOT" ;
